VERSION ""

NS_ :

BS_:

BU_: WSGW VCM TBIOM RCIOM FCIOM CCIOM BPMU

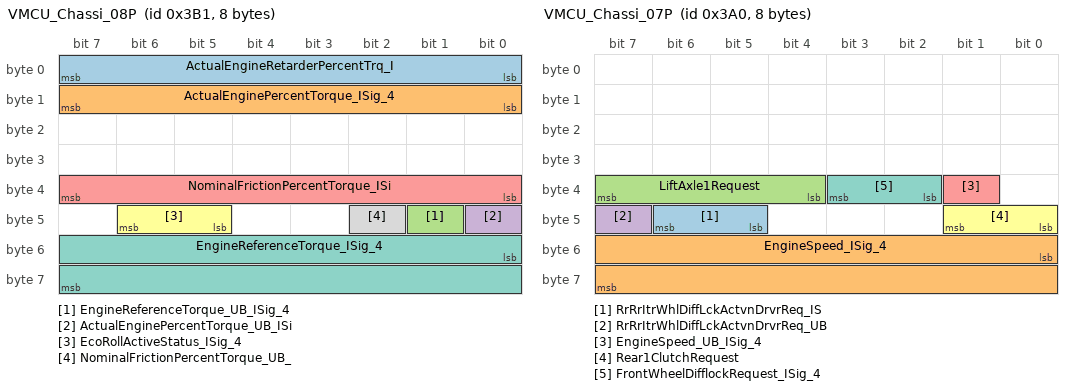
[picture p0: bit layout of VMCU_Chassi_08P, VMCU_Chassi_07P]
BO_ 945 VMCU_Chassi_08P: 8 VCM
 SG_ ActualEngineRetarderPercentTrq_I : 0|8@1+ (1,-125) [-125|130] "Percent"  RCIOM
 SG_ ActualEnginePercentTorque_ISig_4 : 8|8@1+ (1,-125) [-125|130] "Percent"  CCIOM,RCIOM
 SG_ EngineReferenceTorque_UB_ISig_4 : 41|1@1+ (1,0) [0|0] ""  RCIOM
 SG_ ActualEnginePercentTorque_UB_ISi : 40|1@1+ (1,0) [0|0] ""  RCIOM,CCIOM
 SG_ NominalFrictionPercentTorque_ISi : 32|8@1+ (1,-125) [-125|130] "Percent"  RCIOM
 SG_ EcoRollActiveStatus_ISig_4 : 45|2@1+ (1,0) [0|0] ""  CCIOM
 SG_ EngineReferenceTorque_ISig_4 : 48|16@1+ (1,0) [0|65535] "Nm"  RCIOM
 SG_ NominalFrictionPercentTorque_UB_ : 42|1@1+ (1,0) [0|0] ""  RCIOM

BO_ 928 VMCU_Chassi_07P: 8 VCM
 SG_ RrRrItrWhlDiffLckActvnDrvrReq_IS : 45|2@1+ (1,0) [0|0] ""  RCIOM
 SG_ EngineSpeed_ISig_4 : 48|16@1+ (0.125,0) [0|8191.875] "rpm"  CCIOM
 SG_ LiftAxle1Request : 36|4@1+ (1,0) [0|0] ""  RCIOM
 SG_ RrRrItrWhlDiffLckActvnDrvrReq_UB : 47|1@1+ (1,0) [0|0] ""  RCIOM
 SG_ EngineSpeed_UB_ISig_4 : 33|1@1+ (1,0) [0|0] ""  CCIOM
 SG_ Rear1ClutchRequest : 40|2@1+ (1,0) [0|0] ""  RCIOM
 SG_ FrontWheelDifflockRequest_ISig_4 : 34|2@1+ (1,0) [0|0] ""  CCIOM

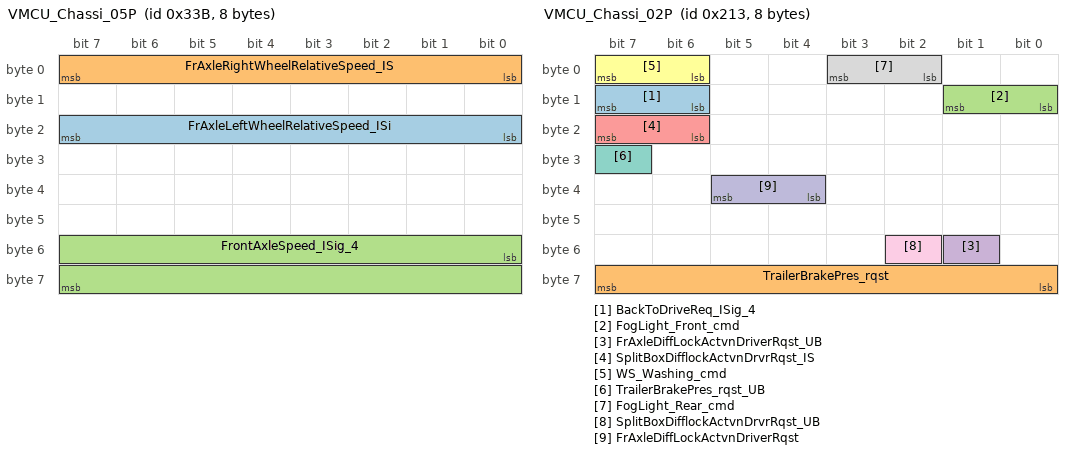
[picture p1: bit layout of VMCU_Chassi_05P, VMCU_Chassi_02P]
BO_ 827 VMCU_Chassi_05P: 8 VCM
 SG_ FrAxleLeftWheelRelativeSpeed_ISi : 16|8@1+ (0.0625,-7.8125) [-7.8125|8.125] "Km_per_h"  RCIOM
 SG_ FrAxleRightWheelRelativeSpeed_IS : 0|8@1+ (0.0625,-7.8125) [-7.8125|8.125] "Km_per_h"  RCIOM
 SG_ FrontAxleSpeed_ISig_4 : 48|16@1+ (0.00390625,0) [0|255.99609375] "Km_per_h"  RCIOM,CCIOM

BO_ 537 VMCU_Chassi_04P: 8 VCM
 SG_ LiftAxle2LiftPositionRequest_ISi : 43|3@1+ (1,0) [0|0] ""  RCIOM
 SG_ LoadDistributionChangeRequest_IS : 48|2@1+ (1,0) [0|0] ""  RCIOM
 SG_ AltLoadDistribution_rqst_ISig_4 : 56|3@1+ (1,0) [0|0] ""  RCIOM
 SG_ LiftAxle1LiftPositionRequest_ISi : 36|3@1+ (1,0) [0|0] ""  RCIOM
 SG_ FerryFunctionRequest_UB_ISig_4 : 10|1@1+ (1,0) [0|0] ""  RCIOM
 SG_ RampLevelRequest_ISig_4 : 0|4@1+ (1,0) [0|0] ""  RCIOM
 SG_ RampLevelStorageRequest_ISig_4 : 16|4@1+ (1,0) [0|0] ""  RCIOM
 SG_ RideHeightFunctionRequest_ISig_4 : 12|4@1+ (1,0) [0|0] ""  RCIOM
 SG_ LiftAxle1AutoLiftRequest_ISig_4 : 34|2@1+ (1,0) [0|0] ""  RCIOM
 SG_ FerryFunctionRequest_ISig_4 : 28|2@1+ (1,0) [0|0] ""  RCIOM
 SG_ AltLoadDistribution_rqst_UB_ISig : 54|1@1+ (1,0) [0|0] ""  RCIOM
 SG_ BBSystemKneelRequest : 8|2@1+ (1,0) [0|0] ""  RCIOM
 SG_ StopLevelChangeRequest_ISig_4 : 24|2@1+ (1,0) [0|0] ""  RCIOM
 SG_ LiftAxle1LiftPositionRequest_UB_ : 39|1@1+ (1,0) [0|0] ""  RCIOM
 SG_ LiftAxle2LiftPositionRequest_UB_ : 46|1@1+ (1,0) [0|0] ""  RCIOM
 SG_ FirstAxleLowerPrioRequested_ISig : 50|3@1+ (1,0) [0|0] ""  RCIOM
 SG_ LiftAxle1AutoLiftRequest_UB_ISig : 23|1@1+ (1,0) [0|0] ""  RCIOM
 SG_ LiftAxle2AutoLiftRequest_ISig_4 : 40|2@1+ (1,0) [0|0] ""  RCIOM
 SG_ LiftAxle2AutoLiftRequest_UB_ISig : 42|1@1+ (1,0) [0|0] ""  RCIOM
 SG_ FerryFunctionSwitchChangeReq_ISi : 61|2@1+ (1,0) [0|0] ""  RCIOM
 SG_ LevelStrokeRequest_ISig_4 : 32|2@1+ (1,0) [0|0] ""  RCIOM
 SG_ BBSystemAlternatLoadDistribReq_U : 55|1@1+ (1,0) [0|0] ""  RCIOM
 SG_ RideHeightFunctionRequest_UB_ISi : 63|1@1+ (1,0) [0|0] ""  RCIOM
 SG_ FirstAxleLowerPrioRequested_UB_I : 53|1@1+ (1,0) [0|0] ""  RCIOM
 SG_ BBSystemProhibitControlRequest : 30|2@1+ (1,0) [0|0] ""  RCIOM
 SG_ LoadDistributionChangeRequest_UB : 47|1@1+ (1,0) [0|0] ""  RCIOM
 SG_ BBSystemAlternatLoadDistribReq : 59|2@1+ (1,0) [0|0] ""  RCIOM
 SG_ RideHeightStorageRequest_ISig_4 : 4|4@1+ (1,0) [0|0] ""  RCIOM
 SG_ BBSystemSpeedDepDriveLevelReq : 26|2@1+ (1,0) [0|0] ""  RCIOM

BO_ 531 VMCU_Chassi_02P: 8 VCM
 SG_ BackToDriveReq_ISig_4 : 14|2@1+ (1,0) [0|0] ""  RCIOM
 SG_ TrailerBrakePres_rqst : 56|8@1+ (8,0) [0|2040] "kPa"  CCIOM
 SG_ FogLight_Front_cmd : 8|2@1+ (1,0) [0|0] ""  FCIOM
 SG_ FrAxleDiffLockActvnDriverRqst_UB : 49|1@1+ (1,0) [0|0] ""  CCIOM
 SG_ SplitBoxDifflockActvnDrvrRqst_IS : 22|2@1+ (1,0) [0|0] ""  CCIOM
 SG_ WS_Washing_cmd : 6|2@1+ (1,0) [0|0] ""  FCIOM
 SG_ TrailerBrakePres_rqst_UB : 31|1@1+ (1,0) [0|0] ""  CCIOM
 SG_ FogLight_Rear_cmd : 2|2@1+ (1,0) [0|0] ""  RCIOM,CCIOM
 SG_ SplitBoxDifflockActvnDrvrRqst_UB : 50|1@1+ (1,0) [0|0] ""  CCIOM
 SG_ FrAxleDiffLockActvnDriverRqst : 36|2@1+ (1,0) [0|0] ""  CCIOM

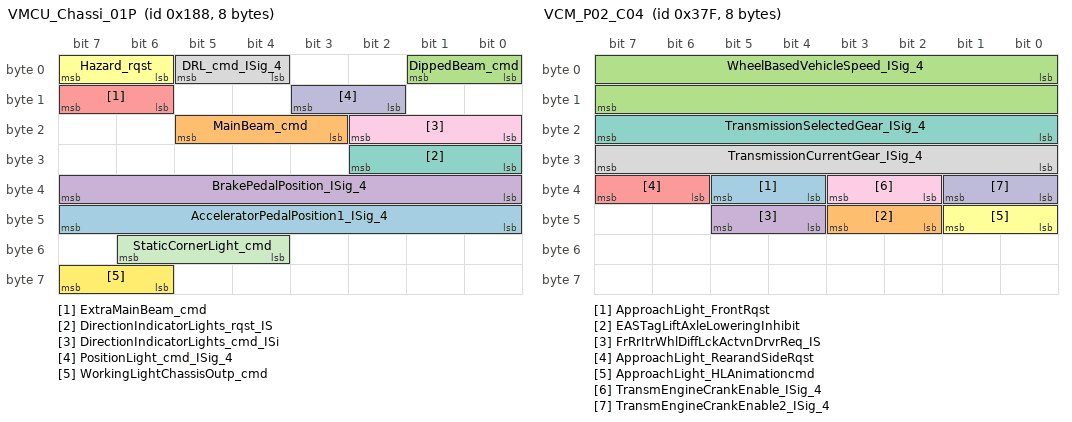
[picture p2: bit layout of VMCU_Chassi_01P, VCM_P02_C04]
BO_ 392 VMCU_Chassi_01P: 8 VCM
 SG_ AcceleratorPedalPosition1_ISig_4 : 40|8@1+ (0.4,0) [0|102] "Percent"  RCIOM,CCIOM
 SG_ MainBeam_cmd : 19|3@1+ (1,0) [0|0] ""  FCIOM,RCIOM
 SG_ DippedBeam_cmd : 0|2@1+ (1,0) [0|0] ""  FCIOM,RCIOM
 SG_ BrakePedalPosition_ISig_4 : 32|8@1+ (0.4,0) [0|102] "Percent"  RCIOM,CCIOM
 SG_ ExtraMainBeam_cmd : 14|2@1+ (1,0) [0|0] ""  FCIOM
 SG_ Hazard_rqst : 6|2@1+ (1,0) [0|0] ""  FCIOM
 SG_ DirectionIndicatorLights_rqst_IS : 24|3@1+ (1,0) [0|0] ""  FCIOM
 SG_ DRL_cmd_ISig_4 : 4|2@1+ (1,0) [0|0] ""  FCIOM,RCIOM
 SG_ DirectionIndicatorLights_cmd_ISi : 16|3@1+ (1,0) [0|0] ""  FCIOM,RCIOM,CCIOM
 SG_ PositionLight_cmd_ISig_4 : 10|2@1+ (1,0) [0|0] ""  FCIOM,RCIOM
 SG_ StaticCornerLight_cmd : 52|3@1+ (1,0) [0|0] ""  FCIOM
 SG_ WorkingLightChassisOutp_cmd : 62|2@1+ (1,0) [0|0] ""  CCIOM

BO_ 895 VCM_P02_C04: 8 VCM
 SG_ ApproachLight_FrontRqst : 36|2@1+ (1,0) [0|0] ""  FCIOM
 SG_ EASTagLiftAxleLoweringInhibit : 42|2@1+ (1,0) [0|0] ""  RCIOM
 SG_ WheelBasedVehicleSpeed_ISig_4 : 0|16@1+ (0.00390625,0) [0|255.99609375] "Km_per_h"  RCIOM,CCIOM,WSGW
 SG_ FrRrItrWhlDiffLckActvnDrvrReq_IS : 44|2@1+ (1,0) [0|0] ""  RCIOM
 SG_ ApproachLight_RearandSideRqst : 38|2@1+ (1,0) [0|0] ""  RCIOM
 SG_ ApproachLight_HLAnimationcmd : 40|2@1+ (1,0) [0|0] ""  FCIOM
 SG_ TransmissionSelectedGear_ISig_4 : 16|8@1+ (1,-125) [-125|130] "GearValue"  CCIOM
 SG_ TransmissionCurrentGear_ISig_4 : 24|8@1+ (1,-125) [-125|130] "GearValue"  CCIOM
 SG_ TransmEngineCrankEnable_ISig_4 : 34|2@1+ (1,0) [0|0] ""  CCIOM
 SG_ TransmEngineCrankEnable2_ISig_4 : 32|2@1+ (1,0) [0|0] ""  CCIOM

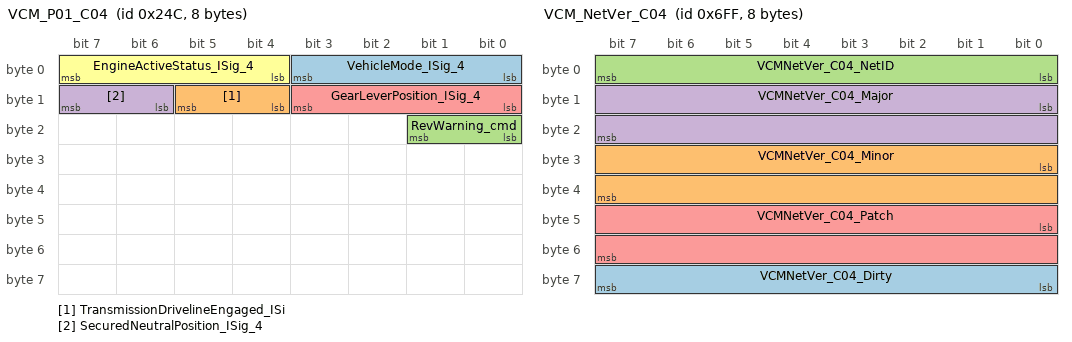
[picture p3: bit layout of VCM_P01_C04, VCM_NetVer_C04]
BO_ 588 VCM_P01_C04: 8 VCM
 SG_ VehicleMode_ISig_4 : 0|4@1+ (1,0) [0|0] ""  CCIOM,WSGW,BPMU,TBIOM,FCIOM,RCIOM
 SG_ TransmissionDrivelineEngaged_ISi : 12|2@1+ (1,0) [0|0] ""  CCIOM
 SG_ RevWarning_cmd : 16|2@1+ (1,0) [0|0] ""  RCIOM
 SG_ SecuredNeutralPosition_ISig_4 : 14|2@1+ (1,0) [0|0] ""  CCIOM
 SG_ GearLeverPosition_ISig_4 : 8|4@1+ (1,0) [0|0] ""  CCIOM
 SG_ EngineActiveStatus_ISig_4 : 4|4@1+ (1,0) [0|0] ""  CCIOM

BO_ 1791 VCM_NetVer_C04: 8 VCM
 SG_ VCMNetVer_C04_Dirty : 56|8@1+ (1,0) [0|255] "NotApplicable" Vector__XXX
 SG_ VCMNetVer_C04_Minor : 24|16@1+ (1,0) [0|65535] "Not Applicable" Vector__XXX
 SG_ VCMNetVer_C04_NetID : 0|8@1+ (1,0) [0|255] "NotApplicable" Vector__XXX
 SG_ VCMNetVer_C04_Major : 8|16@1+ (1,0) [0|65535] "Not Applicable" Vector__XXX
 SG_ VCMNetVer_C04_Patch : 40|16@1+ (1,0) [0|65535] "Not Applicable" Vector__XXX

BO_ 2671902706 TesterFuncDiagMsg_C04: 8 VCM
 SG_ FuncDiagDataTester_ISig_4 : 0|64@1+ (1,0) [0|0] ""  TBIOM,RCIOM,WSGW,FCIOM,CCIOM,BPMU

BO_ 2671902708 TesterFuncDiagMsgF4_C04: 8 VCM
 SG_ FuncDiagDataIntTesterF4_ISig_4 : 0|64@1+ (1,0) [0|0] ""  FCIOM,BPMU,RCIOM,CCIOM,WSGW,TBIOM

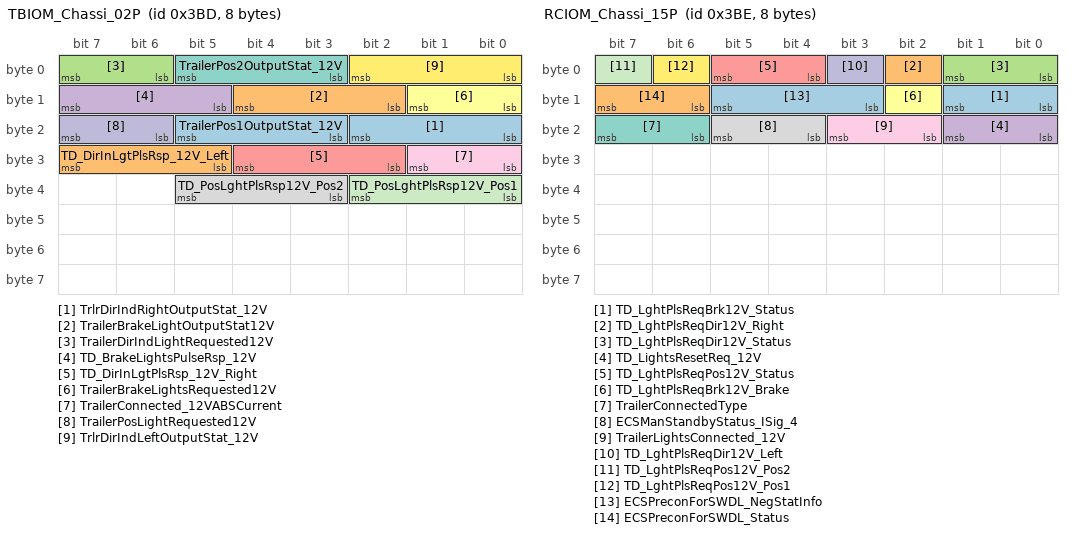
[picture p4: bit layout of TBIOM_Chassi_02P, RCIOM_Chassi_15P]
BO_ 957 TBIOM_Chassi_02P: 8 VCM
 SG_ TrlrDirIndRightOutputStat_12V : 16|3@1+ (1,0) [0|0] ""  RCIOM
 SG_ TrailerBrakeLightOutputStat12V : 10|3@1+ (1,0) [0|0] ""  RCIOM
 SG_ TrailerDirIndLightRequested12V : 6|2@1+ (1,0) [0|0] ""  RCIOM
 SG_ TD_BrakeLightsPulseRsp_12V : 13|3@1+ (1,0) [0|0] ""  RCIOM
 SG_ TD_DirInLgtPlsRsp_12V_Right : 26|3@1+ (1,0) [0|0] ""  RCIOM
 SG_ TrailerBrakeLightsRequested12V : 8|2@1+ (1,0) [0|0] ""  RCIOM
 SG_ TrailerPos2OutputStat_12V : 3|3@1+ (1,0) [0|0] ""  RCIOM
 SG_ TD_PosLghtPlsRsp12V_Pos2 : 35|3@1+ (1,0) [0|0] ""  RCIOM
 SG_ TrailerConnected_12VABSCurrent : 24|2@1+ (1,0) [0|0] ""  RCIOM
 SG_ TrailerPosLightRequested12V : 22|2@1+ (1,0) [0|0] ""  RCIOM
 SG_ TD_PosLghtPlsRsp12V_Pos1 : 32|3@1+ (1,0) [0|0] ""  RCIOM
 SG_ TrlrDirIndLeftOutputStat_12V : 0|3@1+ (1,0) [0|0] ""  RCIOM
 SG_ TrailerPos1OutputStat_12V : 19|3@1+ (1,0) [0|0] ""  RCIOM
 SG_ TD_DirInLgtPlsRsp_12V_Left : 29|3@1+ (1,0) [0|0] ""  RCIOM

BO_ 958 RCIOM_Chassi_15P: 8 RCIOM
 SG_ TD_LghtPlsReqBrk12V_Status : 8|2@1+ (1,0) [0|0] ""  VCM
 SG_ TD_LghtPlsReqDir12V_Right : 2|1@1+ (1,0) [0|0] ""  VCM
 SG_ TD_LghtPlsReqDir12V_Status : 0|2@1+ (1,0) [0|0] ""  VCM
 SG_ TD_LightsResetReq_12V : 16|2@1+ (1,0) [0|0] ""  VCM
 SG_ TD_LghtPlsReqPos12V_Status : 4|2@1+ (1,0) [0|0] ""  VCM
 SG_ TD_LghtPlsReqBrk12V_Brake : 10|1@1+ (1,0) [0|0] ""  VCM
 SG_ TrailerConnectedType : 22|2@1+ (1,0) [0|0] ""  VCM,CCIOM
 SG_ ECSManStandbyStatus_ISig_4 : 20|2@1+ (1,0) [0|0] ""  VCM
 SG_ TrailerLightsConnected_12V : 18|2@1+ (1,0) [0|0] ""  VCM
 SG_ TD_LghtPlsReqDir12V_Left : 3|1@1+ (1,0) [0|0] ""  VCM
 SG_ TD_LghtPlsReqPos12V_Pos2 : 7|1@1+ (1,0) [0|0] ""  VCM
 SG_ TD_LghtPlsReqPos12V_Pos1 : 6|1@1+ (1,0) [0|0] ""  VCM
 SG_ ECSPreconForSWDL_NegStatInfo : 11|3@1+ (1,0) [0|0] ""  VCM
 SG_ ECSPreconForSWDL_Status : 14|2@1+ (1,0) [0|0] ""  VCM

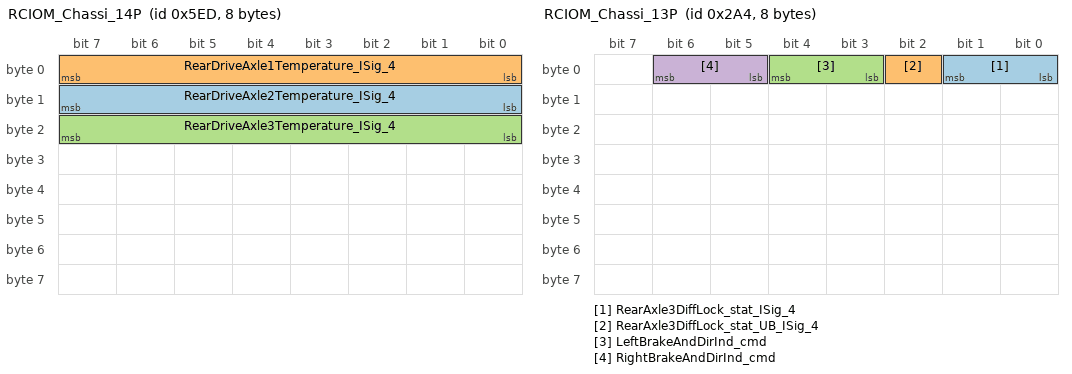
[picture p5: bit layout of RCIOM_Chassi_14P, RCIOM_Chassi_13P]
BO_ 1517 RCIOM_Chassi_14P: 8 RCIOM
 SG_ RearDriveAxle2Temperature_ISig_4 : 8|8@1+ (1,0) [0|255] "DegreeC"  VCM
 SG_ RearDriveAxle1Temperature_ISig_4 : 0|8@1+ (1,0) [0|255] "DegreeC"  VCM
 SG_ RearDriveAxle3Temperature_ISig_4 : 16|8@1+ (1,0) [0|255] "DegreeC"  VCM

BO_ 676 RCIOM_Chassi_13P: 8 RCIOM
 SG_ RearAxle3DiffLock_stat_ISig_4 : 0|2@1+ (1,0) [0|0] ""  VCM
 SG_ RearAxle3DiffLock_stat_UB_ISig_4 : 2|1@1+ (1,0) [0|0] ""  VCM
 SG_ LeftBrakeAndDirInd_cmd : 3|2@1+ (1,0) [0|0] ""  VCM
 SG_ RightBrakeAndDirInd_cmd : 5|2@1+ (1,0) [0|0] ""  VCM

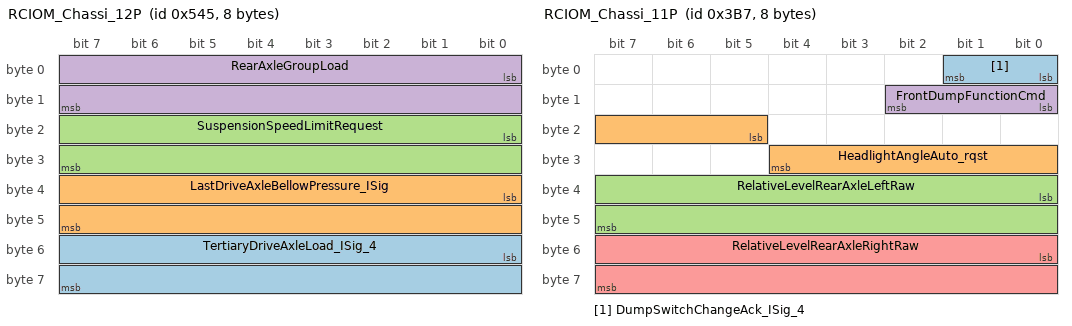
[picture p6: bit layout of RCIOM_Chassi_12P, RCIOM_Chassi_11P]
BO_ 1349 RCIOM_Chassi_12P: 8 RCIOM
 SG_ TertiaryDriveAxleLoad_ISig_4 : 48|16@1+ (0.5,0) [0|32767.5] "kg"  VCM
 SG_ LastDriveAxleBellowPressure_ISig : 32|16@1+ (0.1,0) [0|6553.5] "kPa"  VCM
 SG_ SuspensionSpeedLimitRequest : 16|16@1+ (0.00390625,0) [0|255.99609375] "Km_per_h"  VCM
 SG_ RearAxleGroupLoad : 0|16@1+ (2,0) [0|131070] "kg"  VCM

BO_ 951 RCIOM_Chassi_11P: 8 RCIOM
 SG_ DumpSwitchChangeAck_ISig_4 : 0|2@1+ (1,0) [0|0] ""  VCM
 SG_ HeadlightAngleAuto_rqst : 21|8@1+ (0.025,-4) [-4|2.375] "deg"  VCM
 SG_ RelativeLevelRearAxleLeftRaw : 32|16@1+ (0.1,-3200) [-3200|3353.5] "mm"  VCM
 SG_ FrontDumpFunctionCmd : 8|3@1+ (1,0) [0|0] ""  VCM,CCIOM
 SG_ RelativeLevelRearAxleRightRaw : 48|16@1+ (0.1,-3200) [-3200|3353.5] "mm"  VCM

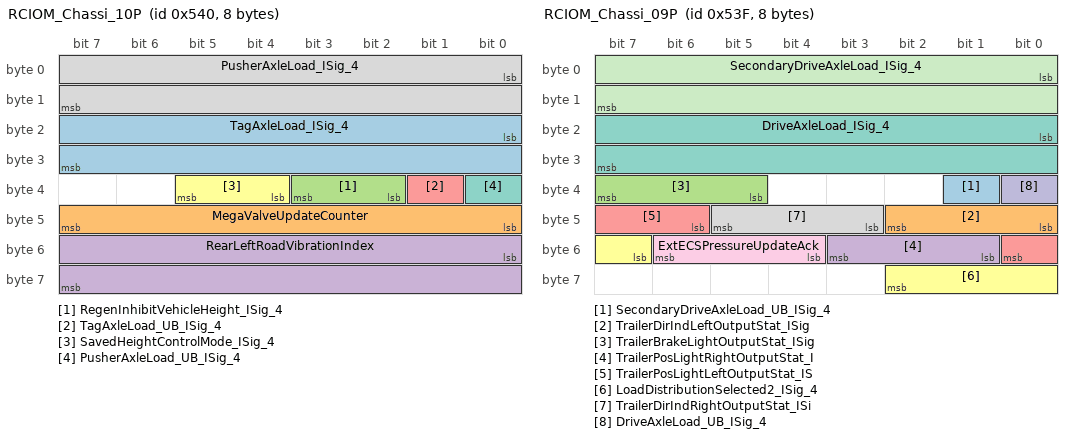
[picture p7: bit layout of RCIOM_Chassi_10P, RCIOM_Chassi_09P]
BO_ 1344 RCIOM_Chassi_10P: 8 RCIOM
 SG_ TagAxleLoad_ISig_4 : 16|16@1+ (0.5,0) [0|32767.5] "kg"  VCM
 SG_ MegaValveUpdateCounter : 40|8@1+ (1,0) [0|255] "Count"  VCM
 SG_ RegenInhibitVehicleHeight_ISig_4 : 34|2@1+ (1,0) [0|0] ""  VCM
 SG_ RearLeftRoadVibrationIndex : 48|16@1+ (0.01,0) [0|655.35] ""  VCM
 SG_ TagAxleLoad_UB_ISig_4 : 33|1@1+ (1,0) [0|0] ""  VCM
 SG_ SavedHeightControlMode_ISig_4 : 36|2@1+ (1,0) [0|0] ""  VCM
 SG_ PusherAxleLoad_UB_ISig_4 : 32|1@1+ (1,0) [0|0] ""  VCM
 SG_ PusherAxleLoad_ISig_4 : 0|16@1+ (0.5,0) [0|32767.5] "kg"  VCM

BO_ 1343 RCIOM_Chassi_09P: 8 RCIOM
 SG_ SecondaryDriveAxleLoad_UB_ISig_4 : 33|1@1+ (1,0) [0|0] ""  VCM
 SG_ TrailerDirIndLeftOutputStat_ISig : 40|3@1+ (1,0) [0|0] ""  VCM
 SG_ TrailerBrakeLightOutputStat_ISig : 37|3@1+ (1,0) [0|0] ""  VCM
 SG_ TrailerPosLightRightOutputStat_I : 49|3@1+ (1,0) [0|0] ""  VCM
 SG_ TrailerPosLightLeftOutputStat_IS : 46|3@1+ (1,0) [0|0] ""  VCM
 SG_ LoadDistributionSelected2_ISig_4 : 55|4@1+ (1,0) [0|0] ""  VCM
 SG_ DriveAxleLoad_ISig_4 : 16|16@1+ (0.5,0) [0|32767.5] "kg"  VCM
 SG_ TrailerDirIndRightOutputStat_ISi : 43|3@1+ (1,0) [0|0] ""  VCM
 SG_ ExtECSPressureUpdateAck : 52|3@1+ (1,0) [0|0] ""  VCM
 SG_ DriveAxleLoad_UB_ISig_4 : 32|1@1+ (1,0) [0|0] ""  VCM
 SG_ SecondaryDriveAxleLoad_ISig_4 : 0|16@1+ (0.5,0) [0|32767.5] "kg"  VCM

BO_ 825 RCIOM_Chassi_08P: 8 RCIOM
 SG_ RevLightLamp_stat_ISig_4 : 43|3@1+ (1,0) [0|0] ""  VCM
 SG_ FirstAxleLowerPrioSelected_ISig_ : 27|3@1+ (1,0) [0|0] ""  VCM
 SG_ FrontParkBrakeOverrideInd_ISig_4 : 46|2@1+ (1,0) [0|0] ""  VCM
 SG_ ECSLimpHomeNotification_ISig_4 : 19|3@1+ (1,0) [0|0] ""  VCM
 SG_ ECSValveActivationAllowed : 30|2@1+ (1,0) [0|0] ""  VCM,CCIOM
 SG_ UnevenLoadWarning_ISig_4 : 38|2@1+ (1,0) [0|0] ""  VCM
 SG_ RampLevelRequestACK_ISig_4 : 4|2@1+ (1,0) [0|0] ""  VCM
 SG_ LoadDistributionSelected_ISig_4 : 12|4@1+ (1,0) [0|0] ""  VCM
 SG_ TrailerABSStatus_ISig_4 : 2|2@1+ (1,0) [0|0] ""  VCM
 SG_ LoadDistributionALDChangeACK_ISi : 32|3@1+ (1,0) [0|0] ""  VCM
 SG_ FogLightRearLamp_stat_ISig_4 : 48|3@1+ (1,0) [0|0] ""  VCM
 SG_ PositionLightRearLamp_stat_ISig_ : 40|3@1+ (1,0) [0|0] ""  VCM
 SG_ FerryFunctionSwitchChangeACK_ISi : 0|2@1+ (1,0) [0|0] ""  VCM
 SG_ LiftAxle1AutoLiftSelected_ISig_4 : 8|2@1+ (1,0) [0|0] ""  VCM
 SG_ BrakeLightLamp_stat_ISig_4 : 35|3@1+ (1,0) [0|0] ""  VCM
 SG_ LiftAxle2AutoLiftSelected_ISig_4 : 10|2@1+ (1,0) [0|0] ""  VCM
 SG_ StartupProhibitStatus_ISig_4 : 53|2@1+ (1,0) [0|0] ""  VCM
 SG_ LiftAxle1LowerACK_ISig_4 : 24|3@1+ (1,0) [0|0] ""  VCM
 SG_ TrailerDirInd_status : 56|3@1+ (1,0) [0|0] ""  VCM
 SG_ DriveLevelPosUserInteraction_ISi : 59|3@1+ (1,0) [0|0] ""  VCM

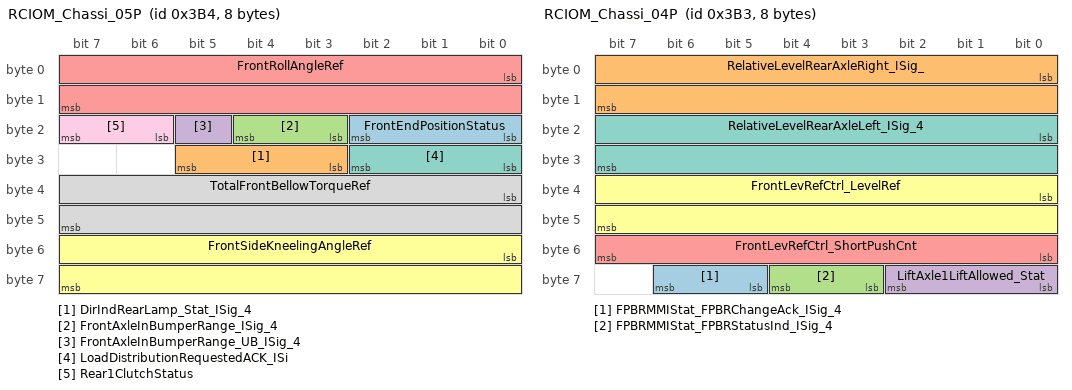
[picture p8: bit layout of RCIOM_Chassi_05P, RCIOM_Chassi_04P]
BO_ 948 RCIOM_Chassi_05P: 8 RCIOM
 SG_ FrontEndPositionStatus : 16|3@1+ (1,0) [0|0] ""  VCM
 SG_ DirIndRearLamp_Stat_ISig_4 : 27|3@1+ (1,0) [0|0] ""  VCM
 SG_ FrontAxleInBumperRange_ISig_4 : 19|2@1+ (1,0) [0|0] ""  VCM
 SG_ FrontAxleInBumperRange_UB_ISig_4 : 21|1@1+ (1,0) [0|0] ""  VCM
 SG_ FrontRollAngleRef : 0|16@1+ (0.001,-30) [-30|35.535] "deg"  VCM,CCIOM
 SG_ FrontSideKneelingAngleRef : 48|16@1+ (0.001,-30) [-30|35.535] "deg"  CCIOM,VCM
 SG_ LoadDistributionRequestedACK_ISi : 24|3@1+ (1,0) [0|0] ""  VCM
 SG_ TotalFrontBellowTorqueRef : 32|16@1+ (1000,-10000000) [-10000000|55535000] "Nm"  VCM,CCIOM
 SG_ Rear1ClutchStatus : 22|2@1+ (1,0) [0|0] ""  VCM

BO_ 947 RCIOM_Chassi_04P: 8 RCIOM
 SG_ FPBRMMIStat_FPBRChangeAck_ISig_4 : 61|2@1+ (1,0) [0|0] ""  VCM
 SG_ RelativeLevelRearAxleRight_ISig_ : 0|16@1+ (0.1,-3200) [-3200|3353.5] "mm"  VCM
 SG_ FPBRMMIStat_FPBRStatusInd_ISig_4 : 59|2@1+ (1,0) [0|0] ""  VCM
 SG_ LiftAxle1LiftAllowed_Stat : 56|3@1+ (1,0) [0|0] ""  VCM
 SG_ FrontLevRefCtrl_ShortPushCnt : 48|8@1+ (1,0) [0|255] "Count"  VCM,CCIOM
 SG_ FrontLevRefCtrl_LevelRef : 32|16@1+ (0.1,-3200) [-3200|3353.5] "mm"  CCIOM,VCM
 SG_ RelativeLevelRearAxleLeft_ISig_4 : 16|16@1+ (0.1,-3200) [-3200|3353.5] "mm"  VCM

BO_ 530 RCIOM_Chassi_03P: 8 RCIOM
 SG_ AirDumpStatus_ISig_4 : 60|3@1+ (1,0) [0|0] ""  VCM
 SG_ RearAxle2DiffLock_stat_ISig_4 : 46|2@1+ (1,0) [0|0] ""  WSGW,VCM
 SG_ SWBrakeSwitch_UB_ISig_4 : 51|1@1+ (1,0) [0|0] ""  VCM
 SG_ SWBrakeSwitch_ISig_4 : 49|2@1+ (1,0) [0|0] ""  VCM
 SG_ RearAxle1DiffLock_stat_ISig_4 : 43|2@1+ (1,0) [0|0] ""  WSGW,VCM
 SG_ SupplyPressure_ISig_4 : 0|8@1+ (8,0) [0|2040] "kPa"  VCM,CCIOM
 SG_ RearAxle2DiffLock_stat_UB_ISig_4 : 48|1@1+ (1,0) [0|0] ""  VCM
 SG_ BackToDriveReqACK_ISig_4 : 58|2@1+ (1,0) [0|0] ""  VCM
 SG_ PitchAngleRef_ISig_4 : 24|16@1+ (0.001,-30) [-30|35.535] "deg"  VCM,CCIOM
 SG_ TrailerConnected_UB_ISig_4 : 54|1@1+ (1,0) [0|0] ""  VCM,CCIOM
 SG_ CentralRearDiffLock_stat_UB_ISig : 42|1@1+ (1,0) [0|0] ""  VCM
 SG_ PitchAngle_ISig_4 : 8|16@1+ (0.001,-30) [-30|35.535] "deg"  VCM,CCIOM
 SG_ TrailerWithoutABS_ISig_4 : 56|2@1+ (1,0) [0|0] ""  VCM
 SG_ TrailerWithoutABS_UB_ISig_4 : 55|1@1+ (1,0) [0|0] ""  VCM
 SG_ TrailerConnected_ISig_4 : 52|2@1+ (1,0) [0|0] ""  VCM,CCIOM,WSGW
 SG_ CentralRearDiffLock_stat_ISig_4 : 40|2@1+ (1,0) [0|0] ""  VCM
 SG_ RearAxle1DiffLock_stat_UB_ISig_4 : 45|1@1+ (1,0) [0|0] ""  VCM

BO_ 528 RCIOM_Chassi_02P: 8 RCIOM
 SG_ RollEndPositionStatus_ISig_4 : 3|3@1+ (1,0) [0|0] ""  VCM
 SG_ FrontFerryFunctionCmd_ISig_4 : 59|3@1+ (1,0) [0|0] ""  VCM,CCIOM
 SG_ RideHeightFunctionStatus_ISig_4 : 36|4@1+ (1,0) [0|0] ""  VCM
 SG_ HeightControlMode_ISig_4 : 32|4@1+ (1,0) [0|0] ""  CCIOM,VCM
 SG_ ECSShutdownCmd_ISig_4 : 43|2@1+ (1,0) [0|0] ""  VCM,CCIOM
 SG_ FerryFunctionStatus_ISig_4 : 56|3@1+ (1,0) [0|0] ""  VCM
 SG_ LevelControlInformation_ISig_4 : 16|4@1+ (1,0) [0|0] ""  VCM
 SG_ ChangeKneelACK_ISig_4 : 45|2@1+ (1,0) [0|0] ""  VCM
 SG_ RearEndPositionStatus_ISig_4 : 48|3@1+ (1,0) [0|0] ""  VCM
 SG_ RampHeightOutsideTargetRange_ISi : 51|3@1+ (1,0) [0|0] ""  VCM
 SG_ LoadDistributionFuncSelected_ISi : 28|4@1+ (1,0) [0|0] ""  VCM
 SG_ HeightAdjustmentAllowed_ISig_4 : 54|2@1+ (1,0) [0|0] ""  VCM
 SG_ LevelControlInformation_UB_ISig_ : 40|1@1+ (1,0) [0|0] ""  VCM
 SG_ KneelingInformation_ISig_4 : 24|4@1+ (1,0) [0|0] ""  VCM
 SG_ KneelingStatusHMI_ISig_4 : 41|2@1+ (1,0) [0|0] ""  VCM
 SG_ LiftAxle1PositionStatus_ISig_4 : 8|3@1+ (1,0) [0|0] ""  CCIOM,WSGW,VCM
 SG_ VehicleDynamicSuspProhibitStat_I : 62|2@1+ (1,0) [0|0] ""  CCIOM,VCM
 SG_ LiftAxle2PositionStatus_ISig_4 : 11|3@1+ (1,0) [0|0] ""  WSGW,VCM
 SG_ RideHeightStatus_ISig_4 : 20|4@1+ (1,0) [0|0] ""  VCM
 SG_ DirInd_Rear_Status_ISig_4 : 0|3@1+ (1,0) [0|0] ""  VCM

CM_ BO_ 827 "This is a sporadic message but this message comes periodically because all signal in the message are gatewayed signals from BB1 and they are periodical there. If there is no traffic on BB1 this message is not sent on Chassi network.";
BA_DEF_ BO_  "GenMsgStartDelayTime" INT 0 0;
BA_DEF_ BO_  "GenMsgDelayTime" INT 0 0;
BA_DEF_ BO_  "GenMsgCycleTime" INT 0 0;
BA_DEF_ BO_  "GenMsgSendType" ENUM  "Cyclic","NotUsed","NotUsed","NotUsed","NotUsed","NotUsed","NotUsed","IfActive","NoMsgSendType","NotUsed";
BA_DEF_ SG_  "GenSigStartValue" INT 0 0;
BA_DEF_ SG_  "GenSigInactiveValue" INT 0 0;
BA_DEF_ SG_  "GenSigCycleTimeActive" INT 0 0;
BA_DEF_ SG_  "GenSigCycleTime" INT 0 0;
BA_DEF_ SG_  "GenSigSendType" ENUM  "Cyclic","OnWrite","OnWriteWithRepetition","OnChange","OnChangeWithRepetition","IfActive","IfActiveWithRepetition","NoSigSendType","NotUsed","NotUsed","NotUsed","NotUsed","NotUsed";
BA_DEF_ BO_  "VFrameFormat" ENUM  "StandardCAN","ExtendedCAN","reserved","J1939PG","reserved","reserved","reserved","reserved","reserved","reserved","reserved","reserved","reserved","reserved","StandardCAN_FD","ExtendedCAN_FD";
BA_DEF_ SG_  "SigType" ENUM  "Default","Range","RangeSigned","ASCII","Discrete","Control","ReferencePGN","DTC","StringDelimiter","StringLength","StringLengthControl";
BA_DEF_ SG_  "Platform_Vivis2_Sig" ENUM  "No","Yes";
BA_DEF_ SG_  "Platform_VMCU1_Sig" ENUM  "No","Yes";
BA_DEF_ BO_  "NmAsrMessage" ENUM  "No","Yes";
BA_DEF_ SG_  "NeedsUpdateBit" ENUM  "No","Yes";
BA_DEF_ SG_  "MmAnSignal" ENUM  "No","Yes";
BA_DEF_ SG_  "GenSigMaxLatency" INT 0 65535;
BA_DEF_ SG_  "GenSigILSupport" ENUM  "Yes","No";
BA_DEF_ BO_  "GenMsgILSupport" ENUM  "No","Yes";
BA_DEF_ SG_  "E2EProfile" STRING ;
BA_DEF_ SG_  "E2EDataLength" INT 0 65535;
BA_DEF_ SG_  "E2EDataId" INT 0 65535;
BA_DEF_ BO_  "DiagUUDTResponse" ENUM  "No","Yes";
BA_DEF_ BO_  "DiagState" ENUM  "No","Yes";
BA_DEF_ BO_  "DiagResponse" ENUM  "No","Yes";
BA_DEF_ BO_  "DiagRequest" ENUM  "No","Yes";
BA_DEF_ BO_  "DiagConnection" HEX 0 65535;
BA_DEF_ BO_  "CanTpFcFrameId" HEX 0 2147483647;
BA_DEF_ BO_  "CanTpBs" INT 0 255;
BA_DEF_ SG_  "SystemSignalLongSymbol" STRING ;
BA_DEF_REL_ BU_SG_REL_  "GenSigTimeoutTime" INT 0 65535;
BA_DEF_REL_ BU_SG_REL_  "GenSigFirstTimeoutTime" INT 0 65535;
BA_DEF_DEF_  "GenMsgStartDelayTime" 0;
BA_DEF_DEF_  "GenMsgDelayTime" 0;
BA_DEF_DEF_  "GenMsgCycleTime" 0;
BA_DEF_DEF_  "GenMsgSendType" "Cyclic";
BA_DEF_DEF_  "GenSigStartValue" 0;
BA_DEF_DEF_  "GenSigInactiveValue" 0;
BA_DEF_DEF_  "GenSigCycleTimeActive" 0;
BA_DEF_DEF_  "GenSigCycleTime" 0;
BA_DEF_DEF_  "GenSigSendType" "Cyclic";
BA_DEF_DEF_  "VFrameFormat" "ExtendedCAN";
BA_DEF_DEF_  "SigType" "Default";
BA_DEF_DEF_  "Platform_Vivis2_Sig" "No";
BA_DEF_DEF_  "Platform_VMCU1_Sig" "No";
BA_DEF_DEF_  "NmAsrMessage" "No";
BA_DEF_DEF_  "NeedsUpdateBit" "No";
BA_DEF_DEF_  "MmAnSignal" "No";
BA_DEF_DEF_  "GenSigMaxLatency" 0;
BA_DEF_DEF_  "GenSigILSupport" "Yes";
BA_DEF_DEF_  "GenMsgILSupport" "Yes";
BA_DEF_DEF_  "E2EProfile" "none";
BA_DEF_DEF_  "E2EDataLength" 0;
BA_DEF_DEF_  "E2EDataId" 0;
BA_DEF_DEF_  "DiagUUDTResponse" "No";
BA_DEF_DEF_  "DiagState" "No";
BA_DEF_DEF_  "DiagResponse" "No";
BA_DEF_DEF_  "DiagRequest" "No";
BA_DEF_DEF_  "DiagConnection" 0;
BA_DEF_DEF_  "CanTpFcFrameId" 2147483647;
BA_DEF_DEF_  "CanTpBs" 255;
BA_DEF_DEF_REL_ "GenSigTimeoutTime" 0;
BA_DEF_DEF_REL_ "GenSigFirstTimeoutTime" 0;
BA_DEF_DEF_  "SystemSignalLongSymbol" "";
BA_ "VFrameFormat" BO_ 945 0;
BA_ "GenMsgCycleTime" BO_ 945 50;
BA_ "GenMsgStartDelayTime" BO_ 945 15;
BA_ "VFrameFormat" BO_ 928 0;
BA_ "GenMsgCycleTime" BO_ 928 50;
BA_ "GenMsgStartDelayTime" BO_ 928 20;
BA_ "VFrameFormat" BO_ 827 0;
BA_ "GenMsgSendType" BO_ 827 8;
BA_ "GenMsgDelayTime" BO_ 827 25;
BA_ "VFrameFormat" BO_ 537 0;
BA_ "GenMsgCycleTime" BO_ 537 20;
BA_ "GenMsgStartDelayTime" BO_ 537 15;
BA_ "VFrameFormat" BO_ 531 0;
BA_ "GenMsgCycleTime" BO_ 531 20;
BA_ "VFrameFormat" BO_ 392 0;
BA_ "GenMsgCycleTime" BO_ 392 10;
BA_ "GenMsgStartDelayTime" BO_ 392 5;
BA_ "VFrameFormat" BO_ 895 0;
BA_ "GenMsgCycleTime" BO_ 895 50;
BA_ "GenMsgStartDelayTime" BO_ 895 5;
BA_ "VFrameFormat" BO_ 588 0;
BA_ "GenMsgCycleTime" BO_ 588 20;
BA_ "GenMsgStartDelayTime" BO_ 588 5;
BA_ "VFrameFormat" BO_ 1791 0;
BA_ "GenMsgCycleTime" BO_ 1791 1000;
BA_ "DiagConnection" BO_ 2671902706 61991;
BA_ "DiagState" BO_ 2671902706 1;
BA_ "GenMsgILSupport" BO_ 2671902706 0;
BA_ "GenMsgSendType" BO_ 2671902706 8;
BA_ "DiagConnection" BO_ 2671902708 62719;
BA_ "DiagState" BO_ 2671902708 1;
BA_ "GenMsgILSupport" BO_ 2671902708 0;
BA_ "GenMsgSendType" BO_ 2671902708 8;
BA_ "VFrameFormat" BO_ 957 0;
BA_ "GenMsgCycleTime" BO_ 957 100;
BA_ "GenMsgStartDelayTime" BO_ 957 5;
BA_ "VFrameFormat" BO_ 958 0;
BA_ "GenMsgCycleTime" BO_ 958 100;
BA_ "GenMsgStartDelayTime" BO_ 958 10;
BA_ "VFrameFormat" BO_ 1517 0;
BA_ "GenMsgCycleTime" BO_ 1517 1000;
BA_ "GenMsgStartDelayTime" BO_ 1517 60;
BA_ "VFrameFormat" BO_ 676 0;
BA_ "GenMsgCycleTime" BO_ 676 20;
BA_ "GenMsgStartDelayTime" BO_ 676 15;
BA_ "VFrameFormat" BO_ 1349 0;
BA_ "GenMsgCycleTime" BO_ 1349 250;
BA_ "GenMsgStartDelayTime" BO_ 1349 75;
BA_ "VFrameFormat" BO_ 951 0;
BA_ "GenMsgCycleTime" BO_ 951 50;
BA_ "GenMsgStartDelayTime" BO_ 951 5;
BA_ "VFrameFormat" BO_ 1344 0;
BA_ "GenMsgCycleTime" BO_ 1344 250;
BA_ "GenMsgStartDelayTime" BO_ 1344 150;
BA_ "VFrameFormat" BO_ 1343 0;
BA_ "GenMsgCycleTime" BO_ 1343 250;
BA_ "GenMsgStartDelayTime" BO_ 1343 50;
BA_ "VFrameFormat" BO_ 825 0;
BA_ "GenMsgCycleTime" BO_ 825 30;
BA_ "GenMsgStartDelayTime" BO_ 825 5;
BA_ "VFrameFormat" BO_ 948 0;
BA_ "GenMsgCycleTime" BO_ 948 50;
BA_ "GenMsgStartDelayTime" BO_ 948 30;
BA_ "VFrameFormat" BO_ 947 0;
BA_ "GenMsgCycleTime" BO_ 947 50;
BA_ "GenMsgStartDelayTime" BO_ 947 10;
BA_ "VFrameFormat" BO_ 530 0;
BA_ "GenMsgCycleTime" BO_ 530 20;
BA_ "GenMsgStartDelayTime" BO_ 530 10;
BA_ "VFrameFormat" BO_ 528 0;
BA_ "GenMsgCycleTime" BO_ 528 20;
BA_ "GenMsgStartDelayTime" BO_ 528 5;
BA_ "GenSigCycleTime" SG_ 945 ActualEngineRetarderPercentTrq_I 100;
BA_ "GenSigCycleTimeActive" SG_ 945 ActualEngineRetarderPercentTrq_I 100;
BA_ "GenSigStartValue" SG_ 945 ActualEngineRetarderPercentTrq_I 255;
BA_ "GenSigMaxLatency" SG_ 945 ActualEngineRetarderPercentTrq_I 54;
BA_ "Platform_VMCU1_Sig" SG_ 945 ActualEngineRetarderPercentTrq_I 1;
BA_ "Platform_Vivis2_Sig" SG_ 945 ActualEngineRetarderPercentTrq_I 1;
BA_ "SystemSignalLongSymbol" SG_ 945 ActualEngineRetarderPercentTrq_I "ActualEngineRetarderPercentTrq_ISig_4";
BA_ "GenSigCycleTime" SG_ 945 ActualEnginePercentTorque_ISig_4 100;
BA_ "GenSigCycleTimeActive" SG_ 945 ActualEnginePercentTorque_ISig_4 100;
BA_ "GenSigStartValue" SG_ 945 ActualEnginePercentTorque_ISig_4 255;
BA_ "GenSigMaxLatency" SG_ 945 ActualEnginePercentTorque_ISig_4 54;
BA_ "NeedsUpdateBit" SG_ 945 ActualEnginePercentTorque_ISig_4 1;
BA_ "Platform_VMCU1_Sig" SG_ 945 ActualEnginePercentTorque_ISig_4 1;
BA_ "Platform_Vivis2_Sig" SG_ 945 ActualEnginePercentTorque_ISig_4 1;
BA_ "GenSigSendType" SG_ 945 EngineReferenceTorque_UB_ISig_4 7;
BA_ "Platform_VMCU1_Sig" SG_ 945 EngineReferenceTorque_UB_ISig_4 1;
BA_ "Platform_Vivis2_Sig" SG_ 945 EngineReferenceTorque_UB_ISig_4 1;
BA_ "GenSigSendType" SG_ 945 ActualEnginePercentTorque_UB_ISi 7;
BA_ "Platform_VMCU1_Sig" SG_ 945 ActualEnginePercentTorque_UB_ISi 1;
BA_ "Platform_Vivis2_Sig" SG_ 945 ActualEnginePercentTorque_UB_ISi 1;
BA_ "SystemSignalLongSymbol" SG_ 945 ActualEnginePercentTorque_UB_ISi "ActualEnginePercentTorque_UB_ISig_4";
BA_ "GenSigCycleTime" SG_ 945 NominalFrictionPercentTorque_ISi 100;
BA_ "GenSigCycleTimeActive" SG_ 945 NominalFrictionPercentTorque_ISi 100;
BA_ "GenSigStartValue" SG_ 945 NominalFrictionPercentTorque_ISi 255;
BA_ "GenSigMaxLatency" SG_ 945 NominalFrictionPercentTorque_ISi 35;
BA_ "NeedsUpdateBit" SG_ 945 NominalFrictionPercentTorque_ISi 1;
BA_ "Platform_VMCU1_Sig" SG_ 945 NominalFrictionPercentTorque_ISi 1;
BA_ "Platform_Vivis2_Sig" SG_ 945 NominalFrictionPercentTorque_ISi 1;
BA_ "SystemSignalLongSymbol" SG_ 945 NominalFrictionPercentTorque_ISi "NominalFrictionPercentTorque_ISig_4";
BA_ "GenSigCycleTime" SG_ 945 EcoRollActiveStatus_ISig_4 100;
BA_ "GenSigCycleTimeActive" SG_ 945 EcoRollActiveStatus_ISig_4 100;
BA_ "GenSigStartValue" SG_ 945 EcoRollActiveStatus_ISig_4 3;
BA_ "Platform_VMCU1_Sig" SG_ 945 EcoRollActiveStatus_ISig_4 1;
BA_ "Platform_Vivis2_Sig" SG_ 945 EcoRollActiveStatus_ISig_4 1;
BA_ "GenSigCycleTime" SG_ 945 EngineReferenceTorque_ISig_4 100;
BA_ "GenSigCycleTimeActive" SG_ 945 EngineReferenceTorque_ISig_4 100;
BA_ "GenSigStartValue" SG_ 945 EngineReferenceTorque_ISig_4 65535;
BA_ "NeedsUpdateBit" SG_ 945 EngineReferenceTorque_ISig_4 1;
BA_ "Platform_VMCU1_Sig" SG_ 945 EngineReferenceTorque_ISig_4 1;
BA_ "Platform_Vivis2_Sig" SG_ 945 EngineReferenceTorque_ISig_4 1;
BA_ "GenSigSendType" SG_ 945 NominalFrictionPercentTorque_UB_ 7;
BA_ "Platform_VMCU1_Sig" SG_ 945 NominalFrictionPercentTorque_UB_ 1;
BA_ "Platform_Vivis2_Sig" SG_ 945 NominalFrictionPercentTorque_UB_ 1;
BA_ "SystemSignalLongSymbol" SG_ 945 NominalFrictionPercentTorque_UB_ "NominalFrictionPercentTorque_UB_ISig_4";
BA_ "GenSigCycleTime" SG_ 928 RrRrItrWhlDiffLckActvnDrvrReq_IS 100;
BA_ "GenSigCycleTimeActive" SG_ 928 RrRrItrWhlDiffLckActvnDrvrReq_IS 100;
BA_ "GenSigStartValue" SG_ 928 RrRrItrWhlDiffLckActvnDrvrReq_IS 3;
BA_ "NeedsUpdateBit" SG_ 928 RrRrItrWhlDiffLckActvnDrvrReq_IS 1;
BA_ "Platform_Vivis2_Sig" SG_ 928 RrRrItrWhlDiffLckActvnDrvrReq_IS 1;
BA_ "SystemSignalLongSymbol" SG_ 928 RrRrItrWhlDiffLckActvnDrvrReq_IS "RrRrItrWhlDiffLckActvnDrvrReq_ISig_4";
BA_ "GenSigCycleTime" SG_ 928 EngineSpeed_ISig_4 100;
BA_ "GenSigCycleTimeActive" SG_ 928 EngineSpeed_ISig_4 100;
BA_ "GenSigStartValue" SG_ 928 EngineSpeed_ISig_4 65535;
BA_ "GenSigMaxLatency" SG_ 928 EngineSpeed_ISig_4 54;
BA_ "NeedsUpdateBit" SG_ 928 EngineSpeed_ISig_4 1;
BA_ "Platform_VMCU1_Sig" SG_ 928 EngineSpeed_ISig_4 1;
BA_ "Platform_Vivis2_Sig" SG_ 928 EngineSpeed_ISig_4 1;
BA_ "GenSigCycleTime" SG_ 928 LiftAxle1Request 100;
BA_ "GenSigCycleTimeActive" SG_ 928 LiftAxle1Request 100;
BA_ "GenSigStartValue" SG_ 928 LiftAxle1Request 15;
BA_ "Platform_VMCU1_Sig" SG_ 928 LiftAxle1Request 1;
BA_ "Platform_Vivis2_Sig" SG_ 928 LiftAxle1Request 1;
BA_ "GenSigSendType" SG_ 928 RrRrItrWhlDiffLckActvnDrvrReq_UB 7;
BA_ "Platform_Vivis2_Sig" SG_ 928 RrRrItrWhlDiffLckActvnDrvrReq_UB 1;
BA_ "SystemSignalLongSymbol" SG_ 928 RrRrItrWhlDiffLckActvnDrvrReq_UB "RrRrItrWhlDiffLckActvnDrvrReq_UB_ISig_4";
BA_ "GenSigSendType" SG_ 928 EngineSpeed_UB_ISig_4 7;
BA_ "Platform_VMCU1_Sig" SG_ 928 EngineSpeed_UB_ISig_4 1;
BA_ "Platform_Vivis2_Sig" SG_ 928 EngineSpeed_UB_ISig_4 1;
BA_ "GenSigCycleTime" SG_ 928 Rear1ClutchRequest 100;
BA_ "GenSigCycleTimeActive" SG_ 928 Rear1ClutchRequest 100;
BA_ "GenSigStartValue" SG_ 928 Rear1ClutchRequest 3;
BA_ "Platform_VMCU1_Sig" SG_ 928 Rear1ClutchRequest 1;
BA_ "Platform_Vivis2_Sig" SG_ 928 Rear1ClutchRequest 1;
BA_ "GenSigCycleTime" SG_ 928 FrontWheelDifflockRequest_ISig_4 100;
BA_ "GenSigCycleTimeActive" SG_ 928 FrontWheelDifflockRequest_ISig_4 100;
BA_ "GenSigStartValue" SG_ 928 FrontWheelDifflockRequest_ISig_4 3;
BA_ "Platform_VMCU1_Sig" SG_ 928 FrontWheelDifflockRequest_ISig_4 1;
BA_ "Platform_Vivis2_Sig" SG_ 928 FrontWheelDifflockRequest_ISig_4 1;
BA_ "GenSigSendType" SG_ 827 FrAxleLeftWheelRelativeSpeed_ISi 1;
BA_ "GenSigStartValue" SG_ 827 FrAxleLeftWheelRelativeSpeed_ISi 255;
BA_ "GenSigMaxLatency" SG_ 827 FrAxleLeftWheelRelativeSpeed_ISi 50;
BA_ "Platform_VMCU1_Sig" SG_ 827 FrAxleLeftWheelRelativeSpeed_ISi 1;
BA_ "Platform_Vivis2_Sig" SG_ 827 FrAxleLeftWheelRelativeSpeed_ISi 1;
BA_ "SystemSignalLongSymbol" SG_ 827 FrAxleLeftWheelRelativeSpeed_ISi "FrAxleLeftWheelRelativeSpeed_ISig_4";
BA_ "GenSigSendType" SG_ 827 FrAxleRightWheelRelativeSpeed_IS 1;
BA_ "GenSigStartValue" SG_ 827 FrAxleRightWheelRelativeSpeed_IS 255;
BA_ "GenSigMaxLatency" SG_ 827 FrAxleRightWheelRelativeSpeed_IS 50;
BA_ "Platform_VMCU1_Sig" SG_ 827 FrAxleRightWheelRelativeSpeed_IS 1;
BA_ "Platform_Vivis2_Sig" SG_ 827 FrAxleRightWheelRelativeSpeed_IS 1;
BA_ "SystemSignalLongSymbol" SG_ 827 FrAxleRightWheelRelativeSpeed_IS "FrAxleRightWheelRelativeSpeed_ISig_4";
BA_ "GenSigSendType" SG_ 827 FrontAxleSpeed_ISig_4 1;
BA_ "GenSigStartValue" SG_ 827 FrontAxleSpeed_ISig_4 65535;
BA_ "GenSigMaxLatency" SG_ 827 FrontAxleSpeed_ISig_4 50;
BA_ "Platform_VMCU1_Sig" SG_ 827 FrontAxleSpeed_ISig_4 1;
BA_ "Platform_Vivis2_Sig" SG_ 827 FrontAxleSpeed_ISig_4 1;
BA_ "GenSigCycleTime" SG_ 537 LiftAxle2LiftPositionRequest_ISi 100;
BA_ "GenSigCycleTimeActive" SG_ 537 LiftAxle2LiftPositionRequest_ISi 100;
BA_ "GenSigStartValue" SG_ 537 LiftAxle2LiftPositionRequest_ISi 7;
BA_ "GenSigMaxLatency" SG_ 537 LiftAxle2LiftPositionRequest_ISi 29;
BA_ "NeedsUpdateBit" SG_ 537 LiftAxle2LiftPositionRequest_ISi 1;
BA_ "Platform_VMCU1_Sig" SG_ 537 LiftAxle2LiftPositionRequest_ISi 1;
BA_ "Platform_Vivis2_Sig" SG_ 537 LiftAxle2LiftPositionRequest_ISi 1;
BA_ "SystemSignalLongSymbol" SG_ 537 LiftAxle2LiftPositionRequest_ISi "LiftAxle2LiftPositionRequest_ISig_4";
BA_ "GenSigCycleTime" SG_ 537 LoadDistributionChangeRequest_IS 100;
BA_ "GenSigCycleTimeActive" SG_ 537 LoadDistributionChangeRequest_IS 100;
BA_ "GenSigStartValue" SG_ 537 LoadDistributionChangeRequest_IS 3;
BA_ "GenSigMaxLatency" SG_ 537 LoadDistributionChangeRequest_IS 29;
BA_ "NeedsUpdateBit" SG_ 537 LoadDistributionChangeRequest_IS 1;
BA_ "Platform_VMCU1_Sig" SG_ 537 LoadDistributionChangeRequest_IS 1;
BA_ "Platform_Vivis2_Sig" SG_ 537 LoadDistributionChangeRequest_IS 1;
BA_ "SystemSignalLongSymbol" SG_ 537 LoadDistributionChangeRequest_IS "LoadDistributionChangeRequest_ISig_4";
BA_ "GenSigCycleTime" SG_ 537 AltLoadDistribution_rqst_ISig_4 100;
BA_ "GenSigCycleTimeActive" SG_ 537 AltLoadDistribution_rqst_ISig_4 100;
BA_ "GenSigStartValue" SG_ 537 AltLoadDistribution_rqst_ISig_4 7;
BA_ "GenSigMaxLatency" SG_ 537 AltLoadDistribution_rqst_ISig_4 29;
BA_ "NeedsUpdateBit" SG_ 537 AltLoadDistribution_rqst_ISig_4 1;
BA_ "Platform_VMCU1_Sig" SG_ 537 AltLoadDistribution_rqst_ISig_4 1;
BA_ "Platform_Vivis2_Sig" SG_ 537 AltLoadDistribution_rqst_ISig_4 1;
BA_ "GenSigCycleTime" SG_ 537 LiftAxle1LiftPositionRequest_ISi 100;
BA_ "GenSigCycleTimeActive" SG_ 537 LiftAxle1LiftPositionRequest_ISi 100;
BA_ "GenSigStartValue" SG_ 537 LiftAxle1LiftPositionRequest_ISi 7;
BA_ "GenSigMaxLatency" SG_ 537 LiftAxle1LiftPositionRequest_ISi 29;
BA_ "NeedsUpdateBit" SG_ 537 LiftAxle1LiftPositionRequest_ISi 1;
BA_ "Platform_VMCU1_Sig" SG_ 537 LiftAxle1LiftPositionRequest_ISi 1;
BA_ "Platform_Vivis2_Sig" SG_ 537 LiftAxle1LiftPositionRequest_ISi 1;
BA_ "SystemSignalLongSymbol" SG_ 537 LiftAxle1LiftPositionRequest_ISi "LiftAxle1LiftPositionRequest_ISig_4";
BA_ "GenSigSendType" SG_ 537 FerryFunctionRequest_UB_ISig_4 7;
BA_ "Platform_VMCU1_Sig" SG_ 537 FerryFunctionRequest_UB_ISig_4 1;
BA_ "Platform_Vivis2_Sig" SG_ 537 FerryFunctionRequest_UB_ISig_4 1;
BA_ "GenSigCycleTime" SG_ 537 RampLevelRequest_ISig_4 100;
BA_ "GenSigCycleTimeActive" SG_ 537 RampLevelRequest_ISig_4 100;
BA_ "GenSigStartValue" SG_ 537 RampLevelRequest_ISig_4 15;
BA_ "GenSigMaxLatency" SG_ 537 RampLevelRequest_ISig_4 29;
BA_ "Platform_VMCU1_Sig" SG_ 537 RampLevelRequest_ISig_4 1;
BA_ "Platform_Vivis2_Sig" SG_ 537 RampLevelRequest_ISig_4 1;
BA_ "GenSigCycleTime" SG_ 537 RampLevelStorageRequest_ISig_4 100;
BA_ "GenSigCycleTimeActive" SG_ 537 RampLevelStorageRequest_ISig_4 100;
BA_ "GenSigStartValue" SG_ 537 RampLevelStorageRequest_ISig_4 15;
BA_ "GenSigMaxLatency" SG_ 537 RampLevelStorageRequest_ISig_4 29;
BA_ "Platform_VMCU1_Sig" SG_ 537 RampLevelStorageRequest_ISig_4 1;
BA_ "Platform_Vivis2_Sig" SG_ 537 RampLevelStorageRequest_ISig_4 1;
BA_ "GenSigCycleTime" SG_ 537 RideHeightFunctionRequest_ISig_4 100;
BA_ "GenSigCycleTimeActive" SG_ 537 RideHeightFunctionRequest_ISig_4 100;
BA_ "GenSigStartValue" SG_ 537 RideHeightFunctionRequest_ISig_4 15;
BA_ "GenSigMaxLatency" SG_ 537 RideHeightFunctionRequest_ISig_4 29;
BA_ "NeedsUpdateBit" SG_ 537 RideHeightFunctionRequest_ISig_4 1;
BA_ "Platform_VMCU1_Sig" SG_ 537 RideHeightFunctionRequest_ISig_4 1;
BA_ "Platform_Vivis2_Sig" SG_ 537 RideHeightFunctionRequest_ISig_4 1;
BA_ "GenSigCycleTime" SG_ 537 LiftAxle1AutoLiftRequest_ISig_4 100;
BA_ "GenSigCycleTimeActive" SG_ 537 LiftAxle1AutoLiftRequest_ISig_4 100;
BA_ "GenSigStartValue" SG_ 537 LiftAxle1AutoLiftRequest_ISig_4 3;
BA_ "GenSigMaxLatency" SG_ 537 LiftAxle1AutoLiftRequest_ISig_4 29;
BA_ "NeedsUpdateBit" SG_ 537 LiftAxle1AutoLiftRequest_ISig_4 1;
BA_ "Platform_VMCU1_Sig" SG_ 537 LiftAxle1AutoLiftRequest_ISig_4 1;
BA_ "Platform_Vivis2_Sig" SG_ 537 LiftAxle1AutoLiftRequest_ISig_4 1;
BA_ "GenSigCycleTime" SG_ 537 FerryFunctionRequest_ISig_4 100;
BA_ "GenSigCycleTimeActive" SG_ 537 FerryFunctionRequest_ISig_4 100;
BA_ "GenSigStartValue" SG_ 537 FerryFunctionRequest_ISig_4 3;
BA_ "GenSigMaxLatency" SG_ 537 FerryFunctionRequest_ISig_4 29;
BA_ "NeedsUpdateBit" SG_ 537 FerryFunctionRequest_ISig_4 1;
BA_ "Platform_VMCU1_Sig" SG_ 537 FerryFunctionRequest_ISig_4 1;
BA_ "Platform_Vivis2_Sig" SG_ 537 FerryFunctionRequest_ISig_4 1;
BA_ "GenSigSendType" SG_ 537 AltLoadDistribution_rqst_UB_ISig 7;
BA_ "Platform_VMCU1_Sig" SG_ 537 AltLoadDistribution_rqst_UB_ISig 1;
BA_ "Platform_Vivis2_Sig" SG_ 537 AltLoadDistribution_rqst_UB_ISig 1;
BA_ "SystemSignalLongSymbol" SG_ 537 AltLoadDistribution_rqst_UB_ISig "AltLoadDistribution_rqst_UB_ISig_4";
BA_ "GenSigCycleTime" SG_ 537 BBSystemKneelRequest 100;
BA_ "GenSigCycleTimeActive" SG_ 537 BBSystemKneelRequest 100;
BA_ "GenSigStartValue" SG_ 537 BBSystemKneelRequest 3;
BA_ "Platform_VMCU1_Sig" SG_ 537 BBSystemKneelRequest 1;
BA_ "Platform_Vivis2_Sig" SG_ 537 BBSystemKneelRequest 1;
BA_ "GenSigCycleTime" SG_ 537 StopLevelChangeRequest_ISig_4 100;
BA_ "GenSigCycleTimeActive" SG_ 537 StopLevelChangeRequest_ISig_4 100;
BA_ "GenSigStartValue" SG_ 537 StopLevelChangeRequest_ISig_4 3;
BA_ "GenSigMaxLatency" SG_ 537 StopLevelChangeRequest_ISig_4 29;
BA_ "Platform_VMCU1_Sig" SG_ 537 StopLevelChangeRequest_ISig_4 1;
BA_ "Platform_Vivis2_Sig" SG_ 537 StopLevelChangeRequest_ISig_4 1;
BA_ "GenSigSendType" SG_ 537 LiftAxle1LiftPositionRequest_UB_ 7;
BA_ "Platform_VMCU1_Sig" SG_ 537 LiftAxle1LiftPositionRequest_UB_ 1;
BA_ "Platform_Vivis2_Sig" SG_ 537 LiftAxle1LiftPositionRequest_UB_ 1;
BA_ "SystemSignalLongSymbol" SG_ 537 LiftAxle1LiftPositionRequest_UB_ "LiftAxle1LiftPositionRequest_UB_ISig_4";
BA_ "GenSigSendType" SG_ 537 LiftAxle2LiftPositionRequest_UB_ 7;
BA_ "Platform_VMCU1_Sig" SG_ 537 LiftAxle2LiftPositionRequest_UB_ 1;
BA_ "Platform_Vivis2_Sig" SG_ 537 LiftAxle2LiftPositionRequest_UB_ 1;
BA_ "SystemSignalLongSymbol" SG_ 537 LiftAxle2LiftPositionRequest_UB_ "LiftAxle2LiftPositionRequest_UB_ISig_4";
BA_ "GenSigCycleTime" SG_ 537 FirstAxleLowerPrioRequested_ISig 100;
BA_ "GenSigCycleTimeActive" SG_ 537 FirstAxleLowerPrioRequested_ISig 100;
BA_ "GenSigStartValue" SG_ 537 FirstAxleLowerPrioRequested_ISig 7;
BA_ "NeedsUpdateBit" SG_ 537 FirstAxleLowerPrioRequested_ISig 1;
BA_ "Platform_Vivis2_Sig" SG_ 537 FirstAxleLowerPrioRequested_ISig 1;
BA_ "SystemSignalLongSymbol" SG_ 537 FirstAxleLowerPrioRequested_ISig "FirstAxleLowerPrioRequested_ISig_4";
BA_ "GenSigSendType" SG_ 537 LiftAxle1AutoLiftRequest_UB_ISig 7;
BA_ "Platform_VMCU1_Sig" SG_ 537 LiftAxle1AutoLiftRequest_UB_ISig 1;
BA_ "Platform_Vivis2_Sig" SG_ 537 LiftAxle1AutoLiftRequest_UB_ISig 1;
BA_ "SystemSignalLongSymbol" SG_ 537 LiftAxle1AutoLiftRequest_UB_ISig "LiftAxle1AutoLiftRequest_UB_ISig_4";
BA_ "GenSigCycleTime" SG_ 537 LiftAxle2AutoLiftRequest_ISig_4 100;
BA_ "GenSigCycleTimeActive" SG_ 537 LiftAxle2AutoLiftRequest_ISig_4 100;
BA_ "GenSigStartValue" SG_ 537 LiftAxle2AutoLiftRequest_ISig_4 3;
BA_ "GenSigMaxLatency" SG_ 537 LiftAxle2AutoLiftRequest_ISig_4 29;
BA_ "NeedsUpdateBit" SG_ 537 LiftAxle2AutoLiftRequest_ISig_4 1;
BA_ "Platform_VMCU1_Sig" SG_ 537 LiftAxle2AutoLiftRequest_ISig_4 1;
BA_ "Platform_Vivis2_Sig" SG_ 537 LiftAxle2AutoLiftRequest_ISig_4 1;
BA_ "GenSigSendType" SG_ 537 LiftAxle2AutoLiftRequest_UB_ISig 7;
BA_ "Platform_VMCU1_Sig" SG_ 537 LiftAxle2AutoLiftRequest_UB_ISig 1;
BA_ "Platform_Vivis2_Sig" SG_ 537 LiftAxle2AutoLiftRequest_UB_ISig 1;
BA_ "SystemSignalLongSymbol" SG_ 537 LiftAxle2AutoLiftRequest_UB_ISig "LiftAxle2AutoLiftRequest_UB_ISig_4";
BA_ "GenSigCycleTime" SG_ 537 FerryFunctionSwitchChangeReq_ISi 100;
BA_ "GenSigCycleTimeActive" SG_ 537 FerryFunctionSwitchChangeReq_ISi 100;
BA_ "GenSigStartValue" SG_ 537 FerryFunctionSwitchChangeReq_ISi 3;
BA_ "Platform_VMCU1_Sig" SG_ 537 FerryFunctionSwitchChangeReq_ISi 1;
BA_ "Platform_Vivis2_Sig" SG_ 537 FerryFunctionSwitchChangeReq_ISi 1;
BA_ "SystemSignalLongSymbol" SG_ 537 FerryFunctionSwitchChangeReq_ISi "FerryFunctionSwitchChangeReq_ISig_4";
BA_ "GenSigCycleTime" SG_ 537 LevelStrokeRequest_ISig_4 100;
BA_ "GenSigCycleTimeActive" SG_ 537 LevelStrokeRequest_ISig_4 100;
BA_ "GenSigStartValue" SG_ 537 LevelStrokeRequest_ISig_4 3;
BA_ "GenSigMaxLatency" SG_ 537 LevelStrokeRequest_ISig_4 29;
BA_ "Platform_VMCU1_Sig" SG_ 537 LevelStrokeRequest_ISig_4 1;
BA_ "Platform_Vivis2_Sig" SG_ 537 LevelStrokeRequest_ISig_4 1;
BA_ "GenSigSendType" SG_ 537 BBSystemAlternatLoadDistribReq_U 7;
BA_ "Platform_VMCU1_Sig" SG_ 537 BBSystemAlternatLoadDistribReq_U 1;
BA_ "Platform_Vivis2_Sig" SG_ 537 BBSystemAlternatLoadDistribReq_U 1;
BA_ "SystemSignalLongSymbol" SG_ 537 BBSystemAlternatLoadDistribReq_U "BBSystemAlternatLoadDistribReq_UB";
BA_ "GenSigSendType" SG_ 537 RideHeightFunctionRequest_UB_ISi 7;
BA_ "Platform_VMCU1_Sig" SG_ 537 RideHeightFunctionRequest_UB_ISi 1;
BA_ "Platform_Vivis2_Sig" SG_ 537 RideHeightFunctionRequest_UB_ISi 1;
BA_ "SystemSignalLongSymbol" SG_ 537 RideHeightFunctionRequest_UB_ISi "RideHeightFunctionRequest_UB_ISig_4";
BA_ "GenSigSendType" SG_ 537 FirstAxleLowerPrioRequested_UB_I 7;
BA_ "Platform_Vivis2_Sig" SG_ 537 FirstAxleLowerPrioRequested_UB_I 1;
BA_ "SystemSignalLongSymbol" SG_ 537 FirstAxleLowerPrioRequested_UB_I "FirstAxleLowerPrioRequested_UB_ISig_4";
BA_ "GenSigCycleTime" SG_ 537 BBSystemProhibitControlRequest 100;
BA_ "GenSigCycleTimeActive" SG_ 537 BBSystemProhibitControlRequest 100;
BA_ "GenSigStartValue" SG_ 537 BBSystemProhibitControlRequest 3;
BA_ "Platform_VMCU1_Sig" SG_ 537 BBSystemProhibitControlRequest 1;
BA_ "Platform_Vivis2_Sig" SG_ 537 BBSystemProhibitControlRequest 1;
BA_ "GenSigSendType" SG_ 537 LoadDistributionChangeRequest_UB 7;
BA_ "Platform_VMCU1_Sig" SG_ 537 LoadDistributionChangeRequest_UB 1;
BA_ "Platform_Vivis2_Sig" SG_ 537 LoadDistributionChangeRequest_UB 1;
BA_ "SystemSignalLongSymbol" SG_ 537 LoadDistributionChangeRequest_UB "LoadDistributionChangeRequest_UB_ISig_4";
BA_ "GenSigCycleTime" SG_ 537 BBSystemAlternatLoadDistribReq 100;
BA_ "GenSigCycleTimeActive" SG_ 537 BBSystemAlternatLoadDistribReq 100;
BA_ "GenSigStartValue" SG_ 537 BBSystemAlternatLoadDistribReq 3;
BA_ "NeedsUpdateBit" SG_ 537 BBSystemAlternatLoadDistribReq 1;
BA_ "Platform_VMCU1_Sig" SG_ 537 BBSystemAlternatLoadDistribReq 1;
BA_ "Platform_Vivis2_Sig" SG_ 537 BBSystemAlternatLoadDistribReq 1;
BA_ "GenSigCycleTime" SG_ 537 RideHeightStorageRequest_ISig_4 100;
BA_ "GenSigCycleTimeActive" SG_ 537 RideHeightStorageRequest_ISig_4 100;
BA_ "GenSigStartValue" SG_ 537 RideHeightStorageRequest_ISig_4 15;
BA_ "GenSigMaxLatency" SG_ 537 RideHeightStorageRequest_ISig_4 29;
BA_ "Platform_VMCU1_Sig" SG_ 537 RideHeightStorageRequest_ISig_4 1;
BA_ "Platform_Vivis2_Sig" SG_ 537 RideHeightStorageRequest_ISig_4 1;
BA_ "GenSigCycleTime" SG_ 537 BBSystemSpeedDepDriveLevelReq 100;
BA_ "GenSigCycleTimeActive" SG_ 537 BBSystemSpeedDepDriveLevelReq 100;
BA_ "GenSigStartValue" SG_ 537 BBSystemSpeedDepDriveLevelReq 3;
BA_ "Platform_VMCU1_Sig" SG_ 537 BBSystemSpeedDepDriveLevelReq 1;
BA_ "Platform_Vivis2_Sig" SG_ 537 BBSystemSpeedDepDriveLevelReq 1;
BA_ "GenSigCycleTime" SG_ 531 BackToDriveReq_ISig_4 100;
BA_ "GenSigCycleTimeActive" SG_ 531 BackToDriveReq_ISig_4 100;
BA_ "GenSigStartValue" SG_ 531 BackToDriveReq_ISig_4 3;
BA_ "Platform_VMCU1_Sig" SG_ 531 BackToDriveReq_ISig_4 1;
BA_ "Platform_Vivis2_Sig" SG_ 531 BackToDriveReq_ISig_4 1;
BA_ "GenSigCycleTime" SG_ 531 TrailerBrakePres_rqst 100;
BA_ "GenSigCycleTimeActive" SG_ 531 TrailerBrakePres_rqst 100;
BA_ "GenSigStartValue" SG_ 531 TrailerBrakePres_rqst 255;
BA_ "GenSigMaxLatency" SG_ 531 TrailerBrakePres_rqst 35;
BA_ "NeedsUpdateBit" SG_ 531 TrailerBrakePres_rqst 1;
BA_ "Platform_VMCU1_Sig" SG_ 531 TrailerBrakePres_rqst 1;
BA_ "Platform_Vivis2_Sig" SG_ 531 TrailerBrakePres_rqst 1;
BA_ "GenSigCycleTime" SG_ 531 FogLight_Front_cmd 100;
BA_ "GenSigCycleTimeActive" SG_ 531 FogLight_Front_cmd 100;
BA_ "GenSigStartValue" SG_ 531 FogLight_Front_cmd 3;
BA_ "GenSigMaxLatency" SG_ 531 FogLight_Front_cmd 24;
BA_ "Platform_VMCU1_Sig" SG_ 531 FogLight_Front_cmd 1;
BA_ "Platform_Vivis2_Sig" SG_ 531 FogLight_Front_cmd 1;
BA_ "GenSigSendType" SG_ 531 FrAxleDiffLockActvnDriverRqst_UB 7;
BA_ "Platform_VMCU1_Sig" SG_ 531 FrAxleDiffLockActvnDriverRqst_UB 1;
BA_ "Platform_Vivis2_Sig" SG_ 531 FrAxleDiffLockActvnDriverRqst_UB 1;
BA_ "GenSigCycleTime" SG_ 531 SplitBoxDifflockActvnDrvrRqst_IS 100;
BA_ "GenSigCycleTimeActive" SG_ 531 SplitBoxDifflockActvnDrvrRqst_IS 100;
BA_ "GenSigStartValue" SG_ 531 SplitBoxDifflockActvnDrvrRqst_IS 3;
BA_ "GenSigMaxLatency" SG_ 531 SplitBoxDifflockActvnDrvrRqst_IS 35;
BA_ "NeedsUpdateBit" SG_ 531 SplitBoxDifflockActvnDrvrRqst_IS 1;
BA_ "Platform_VMCU1_Sig" SG_ 531 SplitBoxDifflockActvnDrvrRqst_IS 1;
BA_ "Platform_Vivis2_Sig" SG_ 531 SplitBoxDifflockActvnDrvrRqst_IS 1;
BA_ "SystemSignalLongSymbol" SG_ 531 SplitBoxDifflockActvnDrvrRqst_IS "SplitBoxDifflockActvnDrvrRqst_ISig_4";
BA_ "GenSigCycleTime" SG_ 531 WS_Washing_cmd 100;
BA_ "GenSigCycleTimeActive" SG_ 531 WS_Washing_cmd 100;
BA_ "GenSigStartValue" SG_ 531 WS_Washing_cmd 3;
BA_ "GenSigMaxLatency" SG_ 531 WS_Washing_cmd 24;
BA_ "Platform_VMCU1_Sig" SG_ 531 WS_Washing_cmd 1;
BA_ "Platform_Vivis2_Sig" SG_ 531 WS_Washing_cmd 1;
BA_ "GenSigSendType" SG_ 531 TrailerBrakePres_rqst_UB 7;
BA_ "Platform_VMCU1_Sig" SG_ 531 TrailerBrakePres_rqst_UB 1;
BA_ "Platform_Vivis2_Sig" SG_ 531 TrailerBrakePres_rqst_UB 1;
BA_ "GenSigCycleTime" SG_ 531 FogLight_Rear_cmd 100;
BA_ "GenSigCycleTimeActive" SG_ 531 FogLight_Rear_cmd 100;
BA_ "GenSigStartValue" SG_ 531 FogLight_Rear_cmd 3;
BA_ "GenSigMaxLatency" SG_ 531 FogLight_Rear_cmd 24;
BA_ "Platform_VMCU1_Sig" SG_ 531 FogLight_Rear_cmd 1;
BA_ "Platform_Vivis2_Sig" SG_ 531 FogLight_Rear_cmd 1;
BA_ "GenSigSendType" SG_ 531 SplitBoxDifflockActvnDrvrRqst_UB 7;
BA_ "Platform_VMCU1_Sig" SG_ 531 SplitBoxDifflockActvnDrvrRqst_UB 1;
BA_ "Platform_Vivis2_Sig" SG_ 531 SplitBoxDifflockActvnDrvrRqst_UB 1;
BA_ "SystemSignalLongSymbol" SG_ 531 SplitBoxDifflockActvnDrvrRqst_UB "SplitBoxDifflockActvnDrvrRqst_UB_ISig_4";
BA_ "GenSigCycleTime" SG_ 531 FrAxleDiffLockActvnDriverRqst 100;
BA_ "GenSigCycleTimeActive" SG_ 531 FrAxleDiffLockActvnDriverRqst 100;
BA_ "GenSigStartValue" SG_ 531 FrAxleDiffLockActvnDriverRqst 3;
BA_ "GenSigMaxLatency" SG_ 531 FrAxleDiffLockActvnDriverRqst 35;
BA_ "NeedsUpdateBit" SG_ 531 FrAxleDiffLockActvnDriverRqst 1;
BA_ "Platform_VMCU1_Sig" SG_ 531 FrAxleDiffLockActvnDriverRqst 1;
BA_ "Platform_Vivis2_Sig" SG_ 531 FrAxleDiffLockActvnDriverRqst 1;
BA_ "GenSigCycleTime" SG_ 392 AcceleratorPedalPosition1_ISig_4 100;
BA_ "GenSigCycleTimeActive" SG_ 392 AcceleratorPedalPosition1_ISig_4 100;
BA_ "GenSigStartValue" SG_ 392 AcceleratorPedalPosition1_ISig_4 255;
BA_ "GenSigMaxLatency" SG_ 392 AcceleratorPedalPosition1_ISig_4 23;
BA_ "Platform_VMCU1_Sig" SG_ 392 AcceleratorPedalPosition1_ISig_4 1;
BA_ "Platform_Vivis2_Sig" SG_ 392 AcceleratorPedalPosition1_ISig_4 1;
BA_ "GenSigCycleTime" SG_ 392 MainBeam_cmd 100;
BA_ "GenSigCycleTimeActive" SG_ 392 MainBeam_cmd 100;
BA_ "GenSigStartValue" SG_ 392 MainBeam_cmd 7;
BA_ "GenSigMaxLatency" SG_ 392 MainBeam_cmd 23;
BA_ "Platform_VMCU1_Sig" SG_ 392 MainBeam_cmd 1;
BA_ "Platform_Vivis2_Sig" SG_ 392 MainBeam_cmd 1;
BA_ "GenSigCycleTime" SG_ 392 DippedBeam_cmd 100;
BA_ "GenSigCycleTimeActive" SG_ 392 DippedBeam_cmd 100;
BA_ "GenSigStartValue" SG_ 392 DippedBeam_cmd 3;
BA_ "GenSigMaxLatency" SG_ 392 DippedBeam_cmd 23;
BA_ "Platform_VMCU1_Sig" SG_ 392 DippedBeam_cmd 1;
BA_ "Platform_Vivis2_Sig" SG_ 392 DippedBeam_cmd 1;
BA_ "GenSigCycleTime" SG_ 392 BrakePedalPosition_ISig_4 100;
BA_ "GenSigCycleTimeActive" SG_ 392 BrakePedalPosition_ISig_4 100;
BA_ "GenSigStartValue" SG_ 392 BrakePedalPosition_ISig_4 255;
BA_ "GenSigMaxLatency" SG_ 392 BrakePedalPosition_ISig_4 23;
BA_ "Platform_VMCU1_Sig" SG_ 392 BrakePedalPosition_ISig_4 1;
BA_ "Platform_Vivis2_Sig" SG_ 392 BrakePedalPosition_ISig_4 1;
BA_ "GenSigCycleTime" SG_ 392 ExtraMainBeam_cmd 100;
BA_ "GenSigCycleTimeActive" SG_ 392 ExtraMainBeam_cmd 100;
BA_ "GenSigStartValue" SG_ 392 ExtraMainBeam_cmd 3;
BA_ "GenSigMaxLatency" SG_ 392 ExtraMainBeam_cmd 35;
BA_ "Platform_VMCU1_Sig" SG_ 392 ExtraMainBeam_cmd 1;
BA_ "Platform_Vivis2_Sig" SG_ 392 ExtraMainBeam_cmd 1;
BA_ "GenSigCycleTime" SG_ 392 Hazard_rqst 100;
BA_ "GenSigCycleTimeActive" SG_ 392 Hazard_rqst 100;
BA_ "GenSigStartValue" SG_ 392 Hazard_rqst 3;
BA_ "GenSigMaxLatency" SG_ 392 Hazard_rqst 23;
BA_ "Platform_VMCU1_Sig" SG_ 392 Hazard_rqst 1;
BA_ "Platform_Vivis2_Sig" SG_ 392 Hazard_rqst 1;
BA_ "GenSigCycleTime" SG_ 392 DirectionIndicatorLights_rqst_IS 100;
BA_ "GenSigCycleTimeActive" SG_ 392 DirectionIndicatorLights_rqst_IS 100;
BA_ "GenSigStartValue" SG_ 392 DirectionIndicatorLights_rqst_IS 7;
BA_ "GenSigMaxLatency" SG_ 392 DirectionIndicatorLights_rqst_IS 23;
BA_ "Platform_VMCU1_Sig" SG_ 392 DirectionIndicatorLights_rqst_IS 1;
BA_ "Platform_Vivis2_Sig" SG_ 392 DirectionIndicatorLights_rqst_IS 1;
BA_ "SystemSignalLongSymbol" SG_ 392 DirectionIndicatorLights_rqst_IS "DirectionIndicatorLights_rqst_ISig_4";
BA_ "GenSigCycleTime" SG_ 392 DRL_cmd_ISig_4 100;
BA_ "GenSigCycleTimeActive" SG_ 392 DRL_cmd_ISig_4 100;
BA_ "GenSigStartValue" SG_ 392 DRL_cmd_ISig_4 3;
BA_ "GenSigMaxLatency" SG_ 392 DRL_cmd_ISig_4 23;
BA_ "Platform_VMCU1_Sig" SG_ 392 DRL_cmd_ISig_4 1;
BA_ "Platform_Vivis2_Sig" SG_ 392 DRL_cmd_ISig_4 1;
BA_ "GenSigCycleTime" SG_ 392 DirectionIndicatorLights_cmd_ISi 100;
BA_ "GenSigCycleTimeActive" SG_ 392 DirectionIndicatorLights_cmd_ISi 100;
BA_ "GenSigStartValue" SG_ 392 DirectionIndicatorLights_cmd_ISi 7;
BA_ "GenSigMaxLatency" SG_ 392 DirectionIndicatorLights_cmd_ISi 23;
BA_ "Platform_VMCU1_Sig" SG_ 392 DirectionIndicatorLights_cmd_ISi 1;
BA_ "Platform_Vivis2_Sig" SG_ 392 DirectionIndicatorLights_cmd_ISi 1;
BA_ "SystemSignalLongSymbol" SG_ 392 DirectionIndicatorLights_cmd_ISi "DirectionIndicatorLights_cmd_ISig_4";
BA_ "GenSigCycleTime" SG_ 392 PositionLight_cmd_ISig_4 100;
BA_ "GenSigCycleTimeActive" SG_ 392 PositionLight_cmd_ISig_4 100;
BA_ "GenSigStartValue" SG_ 392 PositionLight_cmd_ISig_4 3;
BA_ "GenSigMaxLatency" SG_ 392 PositionLight_cmd_ISig_4 24;
BA_ "Platform_VMCU1_Sig" SG_ 392 PositionLight_cmd_ISig_4 1;
BA_ "Platform_Vivis2_Sig" SG_ 392 PositionLight_cmd_ISig_4 1;
BA_ "GenSigCycleTime" SG_ 392 StaticCornerLight_cmd 100;
BA_ "GenSigCycleTimeActive" SG_ 392 StaticCornerLight_cmd 100;
BA_ "GenSigInactiveValue" SG_ 392 StaticCornerLight_cmd 7;
BA_ "GenSigStartValue" SG_ 392 StaticCornerLight_cmd 7;
BA_ "Platform_VMCU1_Sig" SG_ 392 StaticCornerLight_cmd 1;
BA_ "Platform_Vivis2_Sig" SG_ 392 StaticCornerLight_cmd 1;
BA_ "GenSigCycleTime" SG_ 392 WorkingLightChassisOutp_cmd 100;
BA_ "GenSigCycleTimeActive" SG_ 392 WorkingLightChassisOutp_cmd 100;
BA_ "GenSigStartValue" SG_ 392 WorkingLightChassisOutp_cmd 3;
BA_ "Platform_VMCU1_Sig" SG_ 392 WorkingLightChassisOutp_cmd 1;
BA_ "Platform_Vivis2_Sig" SG_ 392 WorkingLightChassisOutp_cmd 1;
BA_ "GenSigCycleTime" SG_ 895 ApproachLight_FrontRqst 100;
BA_ "GenSigCycleTimeActive" SG_ 895 ApproachLight_FrontRqst 100;
BA_ "GenSigStartValue" SG_ 895 ApproachLight_FrontRqst 3;
BA_ "GenSigCycleTime" SG_ 895 EASTagLiftAxleLoweringInhibit 100;
BA_ "GenSigCycleTimeActive" SG_ 895 EASTagLiftAxleLoweringInhibit 100;
BA_ "GenSigStartValue" SG_ 895 EASTagLiftAxleLoweringInhibit 3;
BA_ "GenSigCycleTime" SG_ 895 WheelBasedVehicleSpeed_ISig_4 100;
BA_ "GenSigCycleTimeActive" SG_ 895 WheelBasedVehicleSpeed_ISig_4 100;
BA_ "GenSigStartValue" SG_ 895 WheelBasedVehicleSpeed_ISig_4 65535;
BA_ "GenSigMaxLatency" SG_ 895 WheelBasedVehicleSpeed_ISig_4 50;
BA_ "GenSigCycleTime" SG_ 895 FrRrItrWhlDiffLckActvnDrvrReq_IS 100;
BA_ "GenSigCycleTimeActive" SG_ 895 FrRrItrWhlDiffLckActvnDrvrReq_IS 100;
BA_ "GenSigStartValue" SG_ 895 FrRrItrWhlDiffLckActvnDrvrReq_IS 3;
BA_ "SystemSignalLongSymbol" SG_ 895 FrRrItrWhlDiffLckActvnDrvrReq_IS "FrRrItrWhlDiffLckActvnDrvrReq_ISig_4";
BA_ "GenSigCycleTime" SG_ 895 ApproachLight_RearandSideRqst 100;
BA_ "GenSigCycleTimeActive" SG_ 895 ApproachLight_RearandSideRqst 100;
BA_ "GenSigStartValue" SG_ 895 ApproachLight_RearandSideRqst 3;
BA_ "GenSigCycleTime" SG_ 895 ApproachLight_HLAnimationcmd 100;
BA_ "GenSigCycleTimeActive" SG_ 895 ApproachLight_HLAnimationcmd 100;
BA_ "GenSigStartValue" SG_ 895 ApproachLight_HLAnimationcmd 3;
BA_ "GenSigCycleTime" SG_ 895 TransmissionSelectedGear_ISig_4 100;
BA_ "GenSigCycleTimeActive" SG_ 895 TransmissionSelectedGear_ISig_4 100;
BA_ "GenSigStartValue" SG_ 895 TransmissionSelectedGear_ISig_4 255;
BA_ "GenSigMaxLatency" SG_ 895 TransmissionSelectedGear_ISig_4 50;
BA_ "GenSigCycleTime" SG_ 895 TransmissionCurrentGear_ISig_4 100;
BA_ "GenSigCycleTimeActive" SG_ 895 TransmissionCurrentGear_ISig_4 100;
BA_ "GenSigStartValue" SG_ 895 TransmissionCurrentGear_ISig_4 255;
BA_ "GenSigMaxLatency" SG_ 895 TransmissionCurrentGear_ISig_4 50;
BA_ "GenSigCycleTime" SG_ 895 TransmEngineCrankEnable_ISig_4 100;
BA_ "GenSigCycleTimeActive" SG_ 895 TransmEngineCrankEnable_ISig_4 100;
BA_ "GenSigStartValue" SG_ 895 TransmEngineCrankEnable_ISig_4 3;
BA_ "GenSigMaxLatency" SG_ 895 TransmEngineCrankEnable_ISig_4 50;
BA_ "GenSigCycleTime" SG_ 895 TransmEngineCrankEnable2_ISig_4 100;
BA_ "GenSigCycleTimeActive" SG_ 895 TransmEngineCrankEnable2_ISig_4 100;
BA_ "GenSigStartValue" SG_ 895 TransmEngineCrankEnable2_ISig_4 3;
BA_ "GenSigMaxLatency" SG_ 895 TransmEngineCrankEnable2_ISig_4 50;
BA_ "GenSigCycleTime" SG_ 588 VehicleMode_ISig_4 100;
BA_ "GenSigCycleTimeActive" SG_ 588 VehicleMode_ISig_4 100;
BA_ "GenSigStartValue" SG_ 588 VehicleMode_ISig_4 15;
BA_ "GenSigMaxLatency" SG_ 588 VehicleMode_ISig_4 20;
BA_ "GenSigCycleTime" SG_ 588 TransmissionDrivelineEngaged_ISi 100;
BA_ "GenSigCycleTimeActive" SG_ 588 TransmissionDrivelineEngaged_ISi 100;
BA_ "GenSigStartValue" SG_ 588 TransmissionDrivelineEngaged_ISi 3;
BA_ "GenSigMaxLatency" SG_ 588 TransmissionDrivelineEngaged_ISi 20;
BA_ "SystemSignalLongSymbol" SG_ 588 TransmissionDrivelineEngaged_ISi "TransmissionDrivelineEngaged_ISig_4";
BA_ "GenSigCycleTime" SG_ 588 RevWarning_cmd 100;
BA_ "GenSigCycleTimeActive" SG_ 588 RevWarning_cmd 100;
BA_ "GenSigStartValue" SG_ 588 RevWarning_cmd 3;
BA_ "Platform_Vivis2_Sig" SG_ 588 RevWarning_cmd 1;
BA_ "GenSigCycleTime" SG_ 588 SecuredNeutralPosition_ISig_4 100;
BA_ "GenSigCycleTimeActive" SG_ 588 SecuredNeutralPosition_ISig_4 100;
BA_ "GenSigStartValue" SG_ 588 SecuredNeutralPosition_ISig_4 3;
BA_ "GenSigMaxLatency" SG_ 588 SecuredNeutralPosition_ISig_4 20;
BA_ "GenSigCycleTime" SG_ 588 GearLeverPosition_ISig_4 100;
BA_ "GenSigCycleTimeActive" SG_ 588 GearLeverPosition_ISig_4 100;
BA_ "GenSigStartValue" SG_ 588 GearLeverPosition_ISig_4 15;
BA_ "GenSigMaxLatency" SG_ 588 GearLeverPosition_ISig_4 20;
BA_ "GenSigCycleTime" SG_ 588 EngineActiveStatus_ISig_4 100;
BA_ "GenSigCycleTimeActive" SG_ 588 EngineActiveStatus_ISig_4 100;
BA_ "GenSigStartValue" SG_ 588 EngineActiveStatus_ISig_4 15;
BA_ "GenSigMaxLatency" SG_ 588 EngineActiveStatus_ISig_4 20;
BA_ "GenSigCycleTime" SG_ 1791 VCMNetVer_C04_Dirty 100;
BA_ "GenSigCycleTimeActive" SG_ 1791 VCMNetVer_C04_Dirty 100;
BA_ "GenSigCycleTime" SG_ 1791 VCMNetVer_C04_Minor 100;
BA_ "GenSigCycleTimeActive" SG_ 1791 VCMNetVer_C04_Minor 100;
BA_ "GenSigStartValue" SG_ 1791 VCMNetVer_C04_Minor 3;
BA_ "GenSigCycleTime" SG_ 1791 VCMNetVer_C04_NetID 100;
BA_ "GenSigCycleTimeActive" SG_ 1791 VCMNetVer_C04_NetID 100;
BA_ "GenSigStartValue" SG_ 1791 VCMNetVer_C04_NetID 4;
BA_ "GenSigCycleTime" SG_ 1791 VCMNetVer_C04_Major 100;
BA_ "GenSigCycleTimeActive" SG_ 1791 VCMNetVer_C04_Major 100;
BA_ "GenSigStartValue" SG_ 1791 VCMNetVer_C04_Major 2;
BA_ "GenSigCycleTime" SG_ 1791 VCMNetVer_C04_Patch 100;
BA_ "GenSigCycleTimeActive" SG_ 1791 VCMNetVer_C04_Patch 100;
BA_ "GenSigSendType" SG_ 2671902706 FuncDiagDataTester_ISig_4 7;
BA_ "GenSigSendType" SG_ 2671902708 FuncDiagDataIntTesterF4_ISig_4 7;
BA_ "GenSigCycleTime" SG_ 957 TrlrDirIndRightOutputStat_12V 100;
BA_ "GenSigCycleTimeActive" SG_ 957 TrlrDirIndRightOutputStat_12V 100;
BA_ "GenSigStartValue" SG_ 957 TrlrDirIndRightOutputStat_12V 7;
BA_ "GenSigMaxLatency" SG_ 957 TrlrDirIndRightOutputStat_12V 100;
BA_ "Platform_Vivis2_Sig" SG_ 957 TrlrDirIndRightOutputStat_12V 1;
BA_ "GenSigCycleTime" SG_ 957 TrailerBrakeLightOutputStat12V 100;
BA_ "GenSigCycleTimeActive" SG_ 957 TrailerBrakeLightOutputStat12V 100;
BA_ "GenSigStartValue" SG_ 957 TrailerBrakeLightOutputStat12V 7;
BA_ "GenSigMaxLatency" SG_ 957 TrailerBrakeLightOutputStat12V 100;
BA_ "Platform_Vivis2_Sig" SG_ 957 TrailerBrakeLightOutputStat12V 1;
BA_ "GenSigCycleTime" SG_ 957 TrailerDirIndLightRequested12V 100;
BA_ "GenSigCycleTimeActive" SG_ 957 TrailerDirIndLightRequested12V 100;
BA_ "GenSigStartValue" SG_ 957 TrailerDirIndLightRequested12V 3;
BA_ "GenSigMaxLatency" SG_ 957 TrailerDirIndLightRequested12V 100;
BA_ "Platform_Vivis2_Sig" SG_ 957 TrailerDirIndLightRequested12V 1;
BA_ "GenSigCycleTime" SG_ 957 TD_BrakeLightsPulseRsp_12V 100;
BA_ "GenSigCycleTimeActive" SG_ 957 TD_BrakeLightsPulseRsp_12V 100;
BA_ "GenSigStartValue" SG_ 957 TD_BrakeLightsPulseRsp_12V 7;
BA_ "GenSigMaxLatency" SG_ 957 TD_BrakeLightsPulseRsp_12V 100;
BA_ "Platform_Vivis2_Sig" SG_ 957 TD_BrakeLightsPulseRsp_12V 1;
BA_ "GenSigCycleTime" SG_ 957 TD_DirInLgtPlsRsp_12V_Right 100;
BA_ "GenSigCycleTimeActive" SG_ 957 TD_DirInLgtPlsRsp_12V_Right 100;
BA_ "GenSigStartValue" SG_ 957 TD_DirInLgtPlsRsp_12V_Right 7;
BA_ "GenSigMaxLatency" SG_ 957 TD_DirInLgtPlsRsp_12V_Right 100;
BA_ "Platform_Vivis2_Sig" SG_ 957 TD_DirInLgtPlsRsp_12V_Right 1;
BA_ "GenSigCycleTime" SG_ 957 TrailerBrakeLightsRequested12V 100;
BA_ "GenSigCycleTimeActive" SG_ 957 TrailerBrakeLightsRequested12V 100;
BA_ "GenSigStartValue" SG_ 957 TrailerBrakeLightsRequested12V 3;
BA_ "GenSigMaxLatency" SG_ 957 TrailerBrakeLightsRequested12V 100;
BA_ "Platform_Vivis2_Sig" SG_ 957 TrailerBrakeLightsRequested12V 1;
BA_ "GenSigCycleTime" SG_ 957 TrailerPos2OutputStat_12V 100;
BA_ "GenSigCycleTimeActive" SG_ 957 TrailerPos2OutputStat_12V 100;
BA_ "GenSigStartValue" SG_ 957 TrailerPos2OutputStat_12V 7;
BA_ "GenSigMaxLatency" SG_ 957 TrailerPos2OutputStat_12V 100;
BA_ "Platform_Vivis2_Sig" SG_ 957 TrailerPos2OutputStat_12V 1;
BA_ "GenSigCycleTime" SG_ 957 TD_PosLghtPlsRsp12V_Pos2 100;
BA_ "GenSigCycleTimeActive" SG_ 957 TD_PosLghtPlsRsp12V_Pos2 100;
BA_ "GenSigStartValue" SG_ 957 TD_PosLghtPlsRsp12V_Pos2 7;
BA_ "GenSigMaxLatency" SG_ 957 TD_PosLghtPlsRsp12V_Pos2 100;
BA_ "Platform_Vivis2_Sig" SG_ 957 TD_PosLghtPlsRsp12V_Pos2 1;
BA_ "GenSigCycleTime" SG_ 957 TrailerConnected_12VABSCurrent 100;
BA_ "GenSigCycleTimeActive" SG_ 957 TrailerConnected_12VABSCurrent 100;
BA_ "GenSigStartValue" SG_ 957 TrailerConnected_12VABSCurrent 3;
BA_ "GenSigMaxLatency" SG_ 957 TrailerConnected_12VABSCurrent 100;
BA_ "Platform_Vivis2_Sig" SG_ 957 TrailerConnected_12VABSCurrent 1;
BA_ "GenSigCycleTime" SG_ 957 TrailerPosLightRequested12V 100;
BA_ "GenSigCycleTimeActive" SG_ 957 TrailerPosLightRequested12V 100;
BA_ "GenSigStartValue" SG_ 957 TrailerPosLightRequested12V 3;
BA_ "GenSigMaxLatency" SG_ 957 TrailerPosLightRequested12V 100;
BA_ "Platform_Vivis2_Sig" SG_ 957 TrailerPosLightRequested12V 1;
BA_ "GenSigCycleTime" SG_ 957 TD_PosLghtPlsRsp12V_Pos1 100;
BA_ "GenSigCycleTimeActive" SG_ 957 TD_PosLghtPlsRsp12V_Pos1 100;
BA_ "GenSigStartValue" SG_ 957 TD_PosLghtPlsRsp12V_Pos1 7;
BA_ "GenSigMaxLatency" SG_ 957 TD_PosLghtPlsRsp12V_Pos1 100;
BA_ "Platform_Vivis2_Sig" SG_ 957 TD_PosLghtPlsRsp12V_Pos1 1;
BA_ "GenSigCycleTime" SG_ 957 TrlrDirIndLeftOutputStat_12V 100;
BA_ "GenSigCycleTimeActive" SG_ 957 TrlrDirIndLeftOutputStat_12V 100;
BA_ "GenSigStartValue" SG_ 957 TrlrDirIndLeftOutputStat_12V 7;
BA_ "GenSigMaxLatency" SG_ 957 TrlrDirIndLeftOutputStat_12V 100;
BA_ "Platform_Vivis2_Sig" SG_ 957 TrlrDirIndLeftOutputStat_12V 1;
BA_ "GenSigCycleTime" SG_ 957 TrailerPos1OutputStat_12V 100;
BA_ "GenSigCycleTimeActive" SG_ 957 TrailerPos1OutputStat_12V 100;
BA_ "GenSigStartValue" SG_ 957 TrailerPos1OutputStat_12V 7;
BA_ "GenSigMaxLatency" SG_ 957 TrailerPos1OutputStat_12V 100;
BA_ "Platform_Vivis2_Sig" SG_ 957 TrailerPos1OutputStat_12V 1;
BA_ "GenSigCycleTime" SG_ 957 TD_DirInLgtPlsRsp_12V_Left 100;
BA_ "GenSigCycleTimeActive" SG_ 957 TD_DirInLgtPlsRsp_12V_Left 100;
BA_ "GenSigStartValue" SG_ 957 TD_DirInLgtPlsRsp_12V_Left 7;
BA_ "GenSigMaxLatency" SG_ 957 TD_DirInLgtPlsRsp_12V_Left 100;
BA_ "Platform_Vivis2_Sig" SG_ 957 TD_DirInLgtPlsRsp_12V_Left 1;
BA_ "GenSigCycleTime" SG_ 958 TD_LghtPlsReqBrk12V_Status 100;
BA_ "GenSigCycleTimeActive" SG_ 958 TD_LghtPlsReqBrk12V_Status 100;
BA_ "GenSigStartValue" SG_ 958 TD_LghtPlsReqBrk12V_Status 3;
BA_ "GenSigMaxLatency" SG_ 958 TD_LghtPlsReqBrk12V_Status 100;
BA_ "Platform_Vivis2_Sig" SG_ 958 TD_LghtPlsReqBrk12V_Status 1;
BA_ "GenSigCycleTime" SG_ 958 TD_LghtPlsReqDir12V_Right 100;
BA_ "GenSigCycleTimeActive" SG_ 958 TD_LghtPlsReqDir12V_Right 100;
BA_ "GenSigMaxLatency" SG_ 958 TD_LghtPlsReqDir12V_Right 100;
BA_ "Platform_Vivis2_Sig" SG_ 958 TD_LghtPlsReqDir12V_Right 1;
BA_ "GenSigCycleTime" SG_ 958 TD_LghtPlsReqDir12V_Status 100;
BA_ "GenSigCycleTimeActive" SG_ 958 TD_LghtPlsReqDir12V_Status 100;
BA_ "GenSigStartValue" SG_ 958 TD_LghtPlsReqDir12V_Status 3;
BA_ "GenSigMaxLatency" SG_ 958 TD_LghtPlsReqDir12V_Status 100;
BA_ "Platform_Vivis2_Sig" SG_ 958 TD_LghtPlsReqDir12V_Status 1;
BA_ "GenSigCycleTime" SG_ 958 TD_LightsResetReq_12V 100;
BA_ "GenSigCycleTimeActive" SG_ 958 TD_LightsResetReq_12V 100;
BA_ "GenSigStartValue" SG_ 958 TD_LightsResetReq_12V 3;
BA_ "GenSigMaxLatency" SG_ 958 TD_LightsResetReq_12V 100;
BA_ "Platform_Vivis2_Sig" SG_ 958 TD_LightsResetReq_12V 1;
BA_ "GenSigCycleTime" SG_ 958 TD_LghtPlsReqPos12V_Status 100;
BA_ "GenSigCycleTimeActive" SG_ 958 TD_LghtPlsReqPos12V_Status 100;
BA_ "GenSigStartValue" SG_ 958 TD_LghtPlsReqPos12V_Status 3;
BA_ "GenSigMaxLatency" SG_ 958 TD_LghtPlsReqPos12V_Status 100;
BA_ "Platform_Vivis2_Sig" SG_ 958 TD_LghtPlsReqPos12V_Status 1;
BA_ "GenSigCycleTime" SG_ 958 TD_LghtPlsReqBrk12V_Brake 100;
BA_ "GenSigCycleTimeActive" SG_ 958 TD_LghtPlsReqBrk12V_Brake 100;
BA_ "GenSigMaxLatency" SG_ 958 TD_LghtPlsReqBrk12V_Brake 100;
BA_ "Platform_Vivis2_Sig" SG_ 958 TD_LghtPlsReqBrk12V_Brake 1;
BA_ "GenSigCycleTime" SG_ 958 TrailerConnectedType 100;
BA_ "GenSigCycleTimeActive" SG_ 958 TrailerConnectedType 100;
BA_ "GenSigStartValue" SG_ 958 TrailerConnectedType 3;
BA_ "Platform_Vivis2_Sig" SG_ 958 TrailerConnectedType 1;
BA_ "GenSigCycleTime" SG_ 958 ECSManStandbyStatus_ISig_4 100;
BA_ "GenSigCycleTimeActive" SG_ 958 ECSManStandbyStatus_ISig_4 100;
BA_ "GenSigStartValue" SG_ 958 ECSManStandbyStatus_ISig_4 3;
BA_ "Platform_Vivis2_Sig" SG_ 958 ECSManStandbyStatus_ISig_4 1;
BA_ "GenSigCycleTime" SG_ 958 TrailerLightsConnected_12V 100;
BA_ "GenSigCycleTimeActive" SG_ 958 TrailerLightsConnected_12V 100;
BA_ "GenSigStartValue" SG_ 958 TrailerLightsConnected_12V 3;
BA_ "GenSigMaxLatency" SG_ 958 TrailerLightsConnected_12V 100;
BA_ "Platform_Vivis2_Sig" SG_ 958 TrailerLightsConnected_12V 1;
BA_ "GenSigCycleTime" SG_ 958 TD_LghtPlsReqDir12V_Left 100;
BA_ "GenSigCycleTimeActive" SG_ 958 TD_LghtPlsReqDir12V_Left 100;
BA_ "GenSigMaxLatency" SG_ 958 TD_LghtPlsReqDir12V_Left 100;
BA_ "Platform_Vivis2_Sig" SG_ 958 TD_LghtPlsReqDir12V_Left 1;
BA_ "GenSigCycleTime" SG_ 958 TD_LghtPlsReqPos12V_Pos2 100;
BA_ "GenSigCycleTimeActive" SG_ 958 TD_LghtPlsReqPos12V_Pos2 100;
BA_ "GenSigMaxLatency" SG_ 958 TD_LghtPlsReqPos12V_Pos2 100;
BA_ "Platform_Vivis2_Sig" SG_ 958 TD_LghtPlsReqPos12V_Pos2 1;
BA_ "GenSigCycleTime" SG_ 958 TD_LghtPlsReqPos12V_Pos1 100;
BA_ "GenSigCycleTimeActive" SG_ 958 TD_LghtPlsReqPos12V_Pos1 100;
BA_ "GenSigMaxLatency" SG_ 958 TD_LghtPlsReqPos12V_Pos1 100;
BA_ "Platform_Vivis2_Sig" SG_ 958 TD_LghtPlsReqPos12V_Pos1 1;
BA_ "GenSigCycleTime" SG_ 958 ECSPreconForSWDL_NegStatInfo 100;
BA_ "GenSigCycleTimeActive" SG_ 958 ECSPreconForSWDL_NegStatInfo 100;
BA_ "GenSigStartValue" SG_ 958 ECSPreconForSWDL_NegStatInfo 7;
BA_ "GenSigMaxLatency" SG_ 958 ECSPreconForSWDL_NegStatInfo 100;
BA_ "Platform_Vivis2_Sig" SG_ 958 ECSPreconForSWDL_NegStatInfo 1;
BA_ "GenSigCycleTime" SG_ 958 ECSPreconForSWDL_Status 100;
BA_ "GenSigCycleTimeActive" SG_ 958 ECSPreconForSWDL_Status 100;
BA_ "GenSigStartValue" SG_ 958 ECSPreconForSWDL_Status 3;
BA_ "GenSigMaxLatency" SG_ 958 ECSPreconForSWDL_Status 100;
BA_ "Platform_Vivis2_Sig" SG_ 958 ECSPreconForSWDL_Status 1;
BA_ "GenSigCycleTime" SG_ 1517 RearDriveAxle2Temperature_ISig_4 100;
BA_ "GenSigCycleTimeActive" SG_ 1517 RearDriveAxle2Temperature_ISig_4 100;
BA_ "GenSigStartValue" SG_ 1517 RearDriveAxle2Temperature_ISig_4 255;
BA_ "Platform_Vivis2_Sig" SG_ 1517 RearDriveAxle2Temperature_ISig_4 1;
BA_ "GenSigCycleTime" SG_ 1517 RearDriveAxle1Temperature_ISig_4 100;
BA_ "GenSigCycleTimeActive" SG_ 1517 RearDriveAxle1Temperature_ISig_4 100;
BA_ "GenSigStartValue" SG_ 1517 RearDriveAxle1Temperature_ISig_4 255;
BA_ "Platform_Vivis2_Sig" SG_ 1517 RearDriveAxle1Temperature_ISig_4 1;
BA_ "GenSigCycleTime" SG_ 1517 RearDriveAxle3Temperature_ISig_4 100;
BA_ "GenSigCycleTimeActive" SG_ 1517 RearDriveAxle3Temperature_ISig_4 100;
BA_ "GenSigStartValue" SG_ 1517 RearDriveAxle3Temperature_ISig_4 255;
BA_ "Platform_Vivis2_Sig" SG_ 1517 RearDriveAxle3Temperature_ISig_4 1;
BA_ "GenSigCycleTime" SG_ 676 RearAxle3DiffLock_stat_ISig_4 100;
BA_ "GenSigCycleTimeActive" SG_ 676 RearAxle3DiffLock_stat_ISig_4 100;
BA_ "GenSigStartValue" SG_ 676 RearAxle3DiffLock_stat_ISig_4 3;
BA_ "NeedsUpdateBit" SG_ 676 RearAxle3DiffLock_stat_ISig_4 1;
BA_ "Platform_Vivis2_Sig" SG_ 676 RearAxle3DiffLock_stat_ISig_4 1;
BA_ "GenSigSendType" SG_ 676 RearAxle3DiffLock_stat_UB_ISig_4 7;
BA_ "Platform_Vivis2_Sig" SG_ 676 RearAxle3DiffLock_stat_UB_ISig_4 1;
BA_ "GenSigCycleTime" SG_ 676 LeftBrakeAndDirInd_cmd 100;
BA_ "GenSigCycleTimeActive" SG_ 676 LeftBrakeAndDirInd_cmd 100;
BA_ "GenSigStartValue" SG_ 676 LeftBrakeAndDirInd_cmd 3;
BA_ "Platform_Vivis2_Sig" SG_ 676 LeftBrakeAndDirInd_cmd 1;
BA_ "GenSigCycleTime" SG_ 676 RightBrakeAndDirInd_cmd 100;
BA_ "GenSigCycleTimeActive" SG_ 676 RightBrakeAndDirInd_cmd 100;
BA_ "GenSigStartValue" SG_ 676 RightBrakeAndDirInd_cmd 3;
BA_ "Platform_Vivis2_Sig" SG_ 676 RightBrakeAndDirInd_cmd 1;
BA_ "GenSigCycleTime" SG_ 1349 TertiaryDriveAxleLoad_ISig_4 100;
BA_ "GenSigCycleTimeActive" SG_ 1349 TertiaryDriveAxleLoad_ISig_4 100;
BA_ "GenSigStartValue" SG_ 1349 TertiaryDriveAxleLoad_ISig_4 65535;
BA_ "Platform_Vivis2_Sig" SG_ 1349 TertiaryDriveAxleLoad_ISig_4 1;
BA_ "GenSigCycleTime" SG_ 1349 LastDriveAxleBellowPressure_ISig 100;
BA_ "GenSigCycleTimeActive" SG_ 1349 LastDriveAxleBellowPressure_ISig 100;
BA_ "GenSigStartValue" SG_ 1349 LastDriveAxleBellowPressure_ISig 65535;
BA_ "Platform_Vivis2_Sig" SG_ 1349 LastDriveAxleBellowPressure_ISig 1;
BA_ "SystemSignalLongSymbol" SG_ 1349 LastDriveAxleBellowPressure_ISig "LastDriveAxleBellowPressure_ISig_4";
BA_ "GenSigCycleTime" SG_ 1349 SuspensionSpeedLimitRequest 100;
BA_ "GenSigCycleTimeActive" SG_ 1349 SuspensionSpeedLimitRequest 100;
BA_ "GenSigStartValue" SG_ 1349 SuspensionSpeedLimitRequest 65535;
BA_ "Platform_Vivis2_Sig" SG_ 1349 SuspensionSpeedLimitRequest 1;
BA_ "GenSigCycleTime" SG_ 1349 RearAxleGroupLoad 100;
BA_ "GenSigCycleTimeActive" SG_ 1349 RearAxleGroupLoad 100;
BA_ "GenSigStartValue" SG_ 1349 RearAxleGroupLoad 65535;
BA_ "Platform_Vivis2_Sig" SG_ 1349 RearAxleGroupLoad 1;
BA_ "GenSigCycleTime" SG_ 951 DumpSwitchChangeAck_ISig_4 100;
BA_ "GenSigCycleTimeActive" SG_ 951 DumpSwitchChangeAck_ISig_4 100;
BA_ "GenSigStartValue" SG_ 951 DumpSwitchChangeAck_ISig_4 3;
BA_ "Platform_Vivis2_Sig" SG_ 951 DumpSwitchChangeAck_ISig_4 1;
BA_ "GenSigCycleTime" SG_ 951 HeadlightAngleAuto_rqst 100;
BA_ "GenSigCycleTimeActive" SG_ 951 HeadlightAngleAuto_rqst 100;
BA_ "GenSigStartValue" SG_ 951 HeadlightAngleAuto_rqst 255;
BA_ "Platform_Vivis2_Sig" SG_ 951 HeadlightAngleAuto_rqst 1;
BA_ "GenSigCycleTime" SG_ 951 RelativeLevelRearAxleLeftRaw 100;
BA_ "GenSigCycleTimeActive" SG_ 951 RelativeLevelRearAxleLeftRaw 100;
BA_ "GenSigStartValue" SG_ 951 RelativeLevelRearAxleLeftRaw 65535;
BA_ "Platform_Vivis2_Sig" SG_ 951 RelativeLevelRearAxleLeftRaw 1;
BA_ "GenSigCycleTime" SG_ 951 FrontDumpFunctionCmd 100;
BA_ "GenSigCycleTimeActive" SG_ 951 FrontDumpFunctionCmd 100;
BA_ "GenSigStartValue" SG_ 951 FrontDumpFunctionCmd 7;
BA_ "Platform_Vivis2_Sig" SG_ 951 FrontDumpFunctionCmd 1;
BA_ "GenSigCycleTime" SG_ 951 RelativeLevelRearAxleRightRaw 100;
BA_ "GenSigCycleTimeActive" SG_ 951 RelativeLevelRearAxleRightRaw 100;
BA_ "GenSigStartValue" SG_ 951 RelativeLevelRearAxleRightRaw 65535;
BA_ "Platform_Vivis2_Sig" SG_ 951 RelativeLevelRearAxleRightRaw 1;
BA_ "GenSigCycleTime" SG_ 1344 TagAxleLoad_ISig_4 100;
BA_ "GenSigCycleTimeActive" SG_ 1344 TagAxleLoad_ISig_4 100;
BA_ "GenSigStartValue" SG_ 1344 TagAxleLoad_ISig_4 65535;
BA_ "GenSigMaxLatency" SG_ 1344 TagAxleLoad_ISig_4 255;
BA_ "NeedsUpdateBit" SG_ 1344 TagAxleLoad_ISig_4 1;
BA_ "Platform_VMCU1_Sig" SG_ 1344 TagAxleLoad_ISig_4 1;
BA_ "Platform_Vivis2_Sig" SG_ 1344 TagAxleLoad_ISig_4 1;
BA_ "GenSigCycleTime" SG_ 1344 MegaValveUpdateCounter 100;
BA_ "GenSigCycleTimeActive" SG_ 1344 MegaValveUpdateCounter 100;
BA_ "GenSigStartValue" SG_ 1344 MegaValveUpdateCounter 255;
BA_ "Platform_Vivis2_Sig" SG_ 1344 MegaValveUpdateCounter 1;
BA_ "GenSigCycleTime" SG_ 1344 RegenInhibitVehicleHeight_ISig_4 100;
BA_ "GenSigCycleTimeActive" SG_ 1344 RegenInhibitVehicleHeight_ISig_4 100;
BA_ "GenSigStartValue" SG_ 1344 RegenInhibitVehicleHeight_ISig_4 3;
BA_ "Platform_VMCU1_Sig" SG_ 1344 RegenInhibitVehicleHeight_ISig_4 1;
BA_ "Platform_Vivis2_Sig" SG_ 1344 RegenInhibitVehicleHeight_ISig_4 1;
BA_ "GenSigCycleTime" SG_ 1344 RearLeftRoadVibrationIndex 100;
BA_ "GenSigCycleTimeActive" SG_ 1344 RearLeftRoadVibrationIndex 100;
BA_ "GenSigStartValue" SG_ 1344 RearLeftRoadVibrationIndex 65535;
BA_ "Platform_VMCU1_Sig" SG_ 1344 RearLeftRoadVibrationIndex 1;
BA_ "Platform_Vivis2_Sig" SG_ 1344 RearLeftRoadVibrationIndex 1;
BA_ "GenSigSendType" SG_ 1344 TagAxleLoad_UB_ISig_4 7;
BA_ "Platform_VMCU1_Sig" SG_ 1344 TagAxleLoad_UB_ISig_4 1;
BA_ "Platform_Vivis2_Sig" SG_ 1344 TagAxleLoad_UB_ISig_4 1;
BA_ "GenSigCycleTime" SG_ 1344 SavedHeightControlMode_ISig_4 100;
BA_ "GenSigCycleTimeActive" SG_ 1344 SavedHeightControlMode_ISig_4 100;
BA_ "GenSigStartValue" SG_ 1344 SavedHeightControlMode_ISig_4 3;
BA_ "Platform_Vivis2_Sig" SG_ 1344 SavedHeightControlMode_ISig_4 1;
BA_ "GenSigSendType" SG_ 1344 PusherAxleLoad_UB_ISig_4 7;
BA_ "Platform_VMCU1_Sig" SG_ 1344 PusherAxleLoad_UB_ISig_4 1;
BA_ "Platform_Vivis2_Sig" SG_ 1344 PusherAxleLoad_UB_ISig_4 1;
BA_ "GenSigCycleTime" SG_ 1344 PusherAxleLoad_ISig_4 100;
BA_ "GenSigCycleTimeActive" SG_ 1344 PusherAxleLoad_ISig_4 100;
BA_ "GenSigStartValue" SG_ 1344 PusherAxleLoad_ISig_4 65535;
BA_ "GenSigMaxLatency" SG_ 1344 PusherAxleLoad_ISig_4 255;
BA_ "NeedsUpdateBit" SG_ 1344 PusherAxleLoad_ISig_4 1;
BA_ "Platform_VMCU1_Sig" SG_ 1344 PusherAxleLoad_ISig_4 1;
BA_ "Platform_Vivis2_Sig" SG_ 1344 PusherAxleLoad_ISig_4 1;
BA_ "GenSigSendType" SG_ 1343 SecondaryDriveAxleLoad_UB_ISig_4 7;
BA_ "Platform_VMCU1_Sig" SG_ 1343 SecondaryDriveAxleLoad_UB_ISig_4 1;
BA_ "Platform_Vivis2_Sig" SG_ 1343 SecondaryDriveAxleLoad_UB_ISig_4 1;
BA_ "GenSigCycleTime" SG_ 1343 TrailerDirIndLeftOutputStat_ISig 100;
BA_ "GenSigCycleTimeActive" SG_ 1343 TrailerDirIndLeftOutputStat_ISig 100;
BA_ "GenSigStartValue" SG_ 1343 TrailerDirIndLeftOutputStat_ISig 7;
BA_ "Platform_Vivis2_Sig" SG_ 1343 TrailerDirIndLeftOutputStat_ISig 1;
BA_ "SystemSignalLongSymbol" SG_ 1343 TrailerDirIndLeftOutputStat_ISig "TrailerDirIndLeftOutputStat_ISig_4";
BA_ "GenSigCycleTime" SG_ 1343 TrailerBrakeLightOutputStat_ISig 100;
BA_ "GenSigCycleTimeActive" SG_ 1343 TrailerBrakeLightOutputStat_ISig 100;
BA_ "GenSigStartValue" SG_ 1343 TrailerBrakeLightOutputStat_ISig 7;
BA_ "Platform_Vivis2_Sig" SG_ 1343 TrailerBrakeLightOutputStat_ISig 1;
BA_ "SystemSignalLongSymbol" SG_ 1343 TrailerBrakeLightOutputStat_ISig "TrailerBrakeLightOutputStat_ISig_4";
BA_ "GenSigCycleTime" SG_ 1343 TrailerPosLightRightOutputStat_I 100;
BA_ "GenSigCycleTimeActive" SG_ 1343 TrailerPosLightRightOutputStat_I 100;
BA_ "GenSigStartValue" SG_ 1343 TrailerPosLightRightOutputStat_I 7;
BA_ "Platform_Vivis2_Sig" SG_ 1343 TrailerPosLightRightOutputStat_I 1;
BA_ "SystemSignalLongSymbol" SG_ 1343 TrailerPosLightRightOutputStat_I "TrailerPosLightRightOutputStat_ISig_4";
BA_ "GenSigCycleTime" SG_ 1343 TrailerPosLightLeftOutputStat_IS 100;
BA_ "GenSigCycleTimeActive" SG_ 1343 TrailerPosLightLeftOutputStat_IS 100;
BA_ "GenSigStartValue" SG_ 1343 TrailerPosLightLeftOutputStat_IS 7;
BA_ "Platform_Vivis2_Sig" SG_ 1343 TrailerPosLightLeftOutputStat_IS 1;
BA_ "SystemSignalLongSymbol" SG_ 1343 TrailerPosLightLeftOutputStat_IS "TrailerPosLightLeftOutputStat_ISig_4";
BA_ "GenSigCycleTime" SG_ 1343 LoadDistributionSelected2_ISig_4 100;
BA_ "GenSigCycleTimeActive" SG_ 1343 LoadDistributionSelected2_ISig_4 100;
BA_ "GenSigStartValue" SG_ 1343 LoadDistributionSelected2_ISig_4 15;
BA_ "Platform_Vivis2_Sig" SG_ 1343 LoadDistributionSelected2_ISig_4 1;
BA_ "GenSigCycleTime" SG_ 1343 DriveAxleLoad_ISig_4 100;
BA_ "GenSigCycleTimeActive" SG_ 1343 DriveAxleLoad_ISig_4 100;
BA_ "GenSigStartValue" SG_ 1343 DriveAxleLoad_ISig_4 65535;
BA_ "GenSigMaxLatency" SG_ 1343 DriveAxleLoad_ISig_4 255;
BA_ "NeedsUpdateBit" SG_ 1343 DriveAxleLoad_ISig_4 1;
BA_ "Platform_VMCU1_Sig" SG_ 1343 DriveAxleLoad_ISig_4 1;
BA_ "Platform_Vivis2_Sig" SG_ 1343 DriveAxleLoad_ISig_4 1;
BA_ "GenSigCycleTime" SG_ 1343 TrailerDirIndRightOutputStat_ISi 100;
BA_ "GenSigCycleTimeActive" SG_ 1343 TrailerDirIndRightOutputStat_ISi 100;
BA_ "GenSigStartValue" SG_ 1343 TrailerDirIndRightOutputStat_ISi 7;
BA_ "Platform_Vivis2_Sig" SG_ 1343 TrailerDirIndRightOutputStat_ISi 1;
BA_ "SystemSignalLongSymbol" SG_ 1343 TrailerDirIndRightOutputStat_ISi "TrailerDirIndRightOutputStat_ISig_4";
BA_ "GenSigCycleTime" SG_ 1343 ExtECSPressureUpdateAck 100;
BA_ "GenSigCycleTimeActive" SG_ 1343 ExtECSPressureUpdateAck 100;
BA_ "GenSigStartValue" SG_ 1343 ExtECSPressureUpdateAck 7;
BA_ "Platform_Vivis2_Sig" SG_ 1343 ExtECSPressureUpdateAck 1;
BA_ "GenSigSendType" SG_ 1343 DriveAxleLoad_UB_ISig_4 7;
BA_ "Platform_VMCU1_Sig" SG_ 1343 DriveAxleLoad_UB_ISig_4 1;
BA_ "Platform_Vivis2_Sig" SG_ 1343 DriveAxleLoad_UB_ISig_4 1;
BA_ "GenSigCycleTime" SG_ 1343 SecondaryDriveAxleLoad_ISig_4 100;
BA_ "GenSigCycleTimeActive" SG_ 1343 SecondaryDriveAxleLoad_ISig_4 100;
BA_ "GenSigStartValue" SG_ 1343 SecondaryDriveAxleLoad_ISig_4 65535;
BA_ "GenSigMaxLatency" SG_ 1343 SecondaryDriveAxleLoad_ISig_4 255;
BA_ "NeedsUpdateBit" SG_ 1343 SecondaryDriveAxleLoad_ISig_4 1;
BA_ "Platform_VMCU1_Sig" SG_ 1343 SecondaryDriveAxleLoad_ISig_4 1;
BA_ "Platform_Vivis2_Sig" SG_ 1343 SecondaryDriveAxleLoad_ISig_4 1;
BA_ "GenSigCycleTime" SG_ 825 RevLightLamp_stat_ISig_4 100;
BA_ "GenSigCycleTimeActive" SG_ 825 RevLightLamp_stat_ISig_4 100;
BA_ "GenSigInactiveValue" SG_ 825 RevLightLamp_stat_ISig_4 7;
BA_ "GenSigStartValue" SG_ 825 RevLightLamp_stat_ISig_4 7;
BA_ "GenSigMaxLatency" SG_ 825 RevLightLamp_stat_ISig_4 35;
BA_ "Platform_VMCU1_Sig" SG_ 825 RevLightLamp_stat_ISig_4 1;
BA_ "Platform_Vivis2_Sig" SG_ 825 RevLightLamp_stat_ISig_4 1;
BA_ "GenSigCycleTime" SG_ 825 FirstAxleLowerPrioSelected_ISig_ 100;
BA_ "GenSigCycleTimeActive" SG_ 825 FirstAxleLowerPrioSelected_ISig_ 100;
BA_ "GenSigStartValue" SG_ 825 FirstAxleLowerPrioSelected_ISig_ 7;
BA_ "Platform_Vivis2_Sig" SG_ 825 FirstAxleLowerPrioSelected_ISig_ 1;
BA_ "SystemSignalLongSymbol" SG_ 825 FirstAxleLowerPrioSelected_ISig_ "FirstAxleLowerPrioSelected_ISig_4";
BA_ "GenSigCycleTime" SG_ 825 FrontParkBrakeOverrideInd_ISig_4 100;
BA_ "GenSigCycleTimeActive" SG_ 825 FrontParkBrakeOverrideInd_ISig_4 100;
BA_ "GenSigStartValue" SG_ 825 FrontParkBrakeOverrideInd_ISig_4 3;
BA_ "Platform_Vivis2_Sig" SG_ 825 FrontParkBrakeOverrideInd_ISig_4 1;
BA_ "GenSigCycleTime" SG_ 825 ECSLimpHomeNotification_ISig_4 100;
BA_ "GenSigCycleTimeActive" SG_ 825 ECSLimpHomeNotification_ISig_4 100;
BA_ "GenSigStartValue" SG_ 825 ECSLimpHomeNotification_ISig_4 7;
BA_ "GenSigMaxLatency" SG_ 825 ECSLimpHomeNotification_ISig_4 35;
BA_ "Platform_VMCU1_Sig" SG_ 825 ECSLimpHomeNotification_ISig_4 1;
BA_ "Platform_Vivis2_Sig" SG_ 825 ECSLimpHomeNotification_ISig_4 1;
BA_ "GenSigCycleTime" SG_ 825 ECSValveActivationAllowed 100;
BA_ "GenSigCycleTimeActive" SG_ 825 ECSValveActivationAllowed 100;
BA_ "GenSigStartValue" SG_ 825 ECSValveActivationAllowed 3;
BA_ "GenSigMaxLatency" SG_ 825 ECSValveActivationAllowed 35;
BA_ "Platform_VMCU1_Sig" SG_ 825 ECSValveActivationAllowed 1;
BA_ "Platform_Vivis2_Sig" SG_ 825 ECSValveActivationAllowed 1;
BA_ "GenSigCycleTime" SG_ 825 UnevenLoadWarning_ISig_4 100;
BA_ "GenSigCycleTimeActive" SG_ 825 UnevenLoadWarning_ISig_4 100;
BA_ "GenSigStartValue" SG_ 825 UnevenLoadWarning_ISig_4 3;
BA_ "GenSigMaxLatency" SG_ 825 UnevenLoadWarning_ISig_4 35;
BA_ "Platform_VMCU1_Sig" SG_ 825 UnevenLoadWarning_ISig_4 1;
BA_ "Platform_Vivis2_Sig" SG_ 825 UnevenLoadWarning_ISig_4 1;
BA_ "GenSigCycleTime" SG_ 825 RampLevelRequestACK_ISig_4 100;
BA_ "GenSigCycleTimeActive" SG_ 825 RampLevelRequestACK_ISig_4 100;
BA_ "GenSigStartValue" SG_ 825 RampLevelRequestACK_ISig_4 3;
BA_ "Platform_VMCU1_Sig" SG_ 825 RampLevelRequestACK_ISig_4 1;
BA_ "Platform_Vivis2_Sig" SG_ 825 RampLevelRequestACK_ISig_4 1;
BA_ "GenSigCycleTime" SG_ 825 LoadDistributionSelected_ISig_4 100;
BA_ "GenSigCycleTimeActive" SG_ 825 LoadDistributionSelected_ISig_4 100;
BA_ "GenSigStartValue" SG_ 825 LoadDistributionSelected_ISig_4 15;
BA_ "GenSigMaxLatency" SG_ 825 LoadDistributionSelected_ISig_4 35;
BA_ "Platform_VMCU1_Sig" SG_ 825 LoadDistributionSelected_ISig_4 1;
BA_ "Platform_Vivis2_Sig" SG_ 825 LoadDistributionSelected_ISig_4 1;
BA_ "GenSigCycleTime" SG_ 825 TrailerABSStatus_ISig_4 100;
BA_ "GenSigCycleTimeActive" SG_ 825 TrailerABSStatus_ISig_4 100;
BA_ "GenSigStartValue" SG_ 825 TrailerABSStatus_ISig_4 3;
BA_ "GenSigMaxLatency" SG_ 825 TrailerABSStatus_ISig_4 35;
BA_ "Platform_VMCU1_Sig" SG_ 825 TrailerABSStatus_ISig_4 1;
BA_ "Platform_Vivis2_Sig" SG_ 825 TrailerABSStatus_ISig_4 1;
BA_ "GenSigCycleTime" SG_ 825 LoadDistributionALDChangeACK_ISi 100;
BA_ "GenSigCycleTimeActive" SG_ 825 LoadDistributionALDChangeACK_ISi 100;
BA_ "GenSigStartValue" SG_ 825 LoadDistributionALDChangeACK_ISi 7;
BA_ "GenSigMaxLatency" SG_ 825 LoadDistributionALDChangeACK_ISi 35;
BA_ "Platform_VMCU1_Sig" SG_ 825 LoadDistributionALDChangeACK_ISi 1;
BA_ "Platform_Vivis2_Sig" SG_ 825 LoadDistributionALDChangeACK_ISi 1;
BA_ "SystemSignalLongSymbol" SG_ 825 LoadDistributionALDChangeACK_ISi "LoadDistributionALDChangeACK_ISig_4";
BA_ "GenSigCycleTime" SG_ 825 FogLightRearLamp_stat_ISig_4 100;
BA_ "GenSigCycleTimeActive" SG_ 825 FogLightRearLamp_stat_ISig_4 100;
BA_ "GenSigInactiveValue" SG_ 825 FogLightRearLamp_stat_ISig_4 7;
BA_ "GenSigStartValue" SG_ 825 FogLightRearLamp_stat_ISig_4 7;
BA_ "GenSigMaxLatency" SG_ 825 FogLightRearLamp_stat_ISig_4 35;
BA_ "Platform_VMCU1_Sig" SG_ 825 FogLightRearLamp_stat_ISig_4 1;
BA_ "Platform_Vivis2_Sig" SG_ 825 FogLightRearLamp_stat_ISig_4 1;
BA_ "GenSigCycleTime" SG_ 825 PositionLightRearLamp_stat_ISig_ 100;
BA_ "GenSigCycleTimeActive" SG_ 825 PositionLightRearLamp_stat_ISig_ 100;
BA_ "GenSigInactiveValue" SG_ 825 PositionLightRearLamp_stat_ISig_ 7;
BA_ "GenSigStartValue" SG_ 825 PositionLightRearLamp_stat_ISig_ 7;
BA_ "GenSigMaxLatency" SG_ 825 PositionLightRearLamp_stat_ISig_ 35;
BA_ "Platform_VMCU1_Sig" SG_ 825 PositionLightRearLamp_stat_ISig_ 1;
BA_ "Platform_Vivis2_Sig" SG_ 825 PositionLightRearLamp_stat_ISig_ 1;
BA_ "SystemSignalLongSymbol" SG_ 825 PositionLightRearLamp_stat_ISig_ "PositionLightRearLamp_stat_ISig_4";
BA_ "GenSigCycleTime" SG_ 825 FerryFunctionSwitchChangeACK_ISi 100;
BA_ "GenSigCycleTimeActive" SG_ 825 FerryFunctionSwitchChangeACK_ISi 100;
BA_ "GenSigStartValue" SG_ 825 FerryFunctionSwitchChangeACK_ISi 3;
BA_ "Platform_VMCU1_Sig" SG_ 825 FerryFunctionSwitchChangeACK_ISi 1;
BA_ "Platform_Vivis2_Sig" SG_ 825 FerryFunctionSwitchChangeACK_ISi 1;
BA_ "SystemSignalLongSymbol" SG_ 825 FerryFunctionSwitchChangeACK_ISi "FerryFunctionSwitchChangeACK_ISig_4";
BA_ "GenSigCycleTime" SG_ 825 LiftAxle1AutoLiftSelected_ISig_4 100;
BA_ "GenSigCycleTimeActive" SG_ 825 LiftAxle1AutoLiftSelected_ISig_4 100;
BA_ "GenSigStartValue" SG_ 825 LiftAxle1AutoLiftSelected_ISig_4 3;
BA_ "Platform_Vivis2_Sig" SG_ 825 LiftAxle1AutoLiftSelected_ISig_4 1;
BA_ "GenSigCycleTime" SG_ 825 BrakeLightLamp_stat_ISig_4 100;
BA_ "GenSigCycleTimeActive" SG_ 825 BrakeLightLamp_stat_ISig_4 100;
BA_ "GenSigInactiveValue" SG_ 825 BrakeLightLamp_stat_ISig_4 7;
BA_ "GenSigStartValue" SG_ 825 BrakeLightLamp_stat_ISig_4 7;
BA_ "GenSigMaxLatency" SG_ 825 BrakeLightLamp_stat_ISig_4 35;
BA_ "Platform_VMCU1_Sig" SG_ 825 BrakeLightLamp_stat_ISig_4 1;
BA_ "Platform_Vivis2_Sig" SG_ 825 BrakeLightLamp_stat_ISig_4 1;
BA_ "GenSigCycleTime" SG_ 825 LiftAxle2AutoLiftSelected_ISig_4 100;
BA_ "GenSigCycleTimeActive" SG_ 825 LiftAxle2AutoLiftSelected_ISig_4 100;
BA_ "GenSigStartValue" SG_ 825 LiftAxle2AutoLiftSelected_ISig_4 3;
BA_ "Platform_Vivis2_Sig" SG_ 825 LiftAxle2AutoLiftSelected_ISig_4 1;
BA_ "GenSigCycleTime" SG_ 825 StartupProhibitStatus_ISig_4 100;
BA_ "GenSigCycleTimeActive" SG_ 825 StartupProhibitStatus_ISig_4 100;
BA_ "GenSigStartValue" SG_ 825 StartupProhibitStatus_ISig_4 3;
BA_ "Platform_VMCU1_Sig" SG_ 825 StartupProhibitStatus_ISig_4 1;
BA_ "Platform_Vivis2_Sig" SG_ 825 StartupProhibitStatus_ISig_4 1;
BA_ "GenSigCycleTime" SG_ 825 LiftAxle1LowerACK_ISig_4 100;
BA_ "GenSigCycleTimeActive" SG_ 825 LiftAxle1LowerACK_ISig_4 100;
BA_ "GenSigStartValue" SG_ 825 LiftAxle1LowerACK_ISig_4 7;
BA_ "Platform_Vivis2_Sig" SG_ 825 LiftAxle1LowerACK_ISig_4 1;
BA_ "GenSigCycleTime" SG_ 825 TrailerDirInd_status 100;
BA_ "GenSigCycleTimeActive" SG_ 825 TrailerDirInd_status 100;
BA_ "GenSigStartValue" SG_ 825 TrailerDirInd_status 7;
BA_ "GenSigMaxLatency" SG_ 825 TrailerDirInd_status 23;
BA_ "Platform_VMCU1_Sig" SG_ 825 TrailerDirInd_status 1;
BA_ "Platform_Vivis2_Sig" SG_ 825 TrailerDirInd_status 1;
BA_ "GenSigCycleTime" SG_ 825 DriveLevelPosUserInteraction_ISi 100;
BA_ "GenSigCycleTimeActive" SG_ 825 DriveLevelPosUserInteraction_ISi 100;
BA_ "GenSigStartValue" SG_ 825 DriveLevelPosUserInteraction_ISi 7;
BA_ "Platform_VMCU1_Sig" SG_ 825 DriveLevelPosUserInteraction_ISi 1;
BA_ "Platform_Vivis2_Sig" SG_ 825 DriveLevelPosUserInteraction_ISi 1;
BA_ "SystemSignalLongSymbol" SG_ 825 DriveLevelPosUserInteraction_ISi "DriveLevelPosUserInteraction_ISig_4";
BA_ "GenSigCycleTime" SG_ 948 FrontEndPositionStatus 100;
BA_ "GenSigCycleTimeActive" SG_ 948 FrontEndPositionStatus 100;
BA_ "GenSigInactiveValue" SG_ 948 FrontEndPositionStatus 7;
BA_ "GenSigStartValue" SG_ 948 FrontEndPositionStatus 7;
BA_ "GenSigMaxLatency" SG_ 948 FrontEndPositionStatus 35;
BA_ "Platform_VMCU1_Sig" SG_ 948 FrontEndPositionStatus 1;
BA_ "Platform_Vivis2_Sig" SG_ 948 FrontEndPositionStatus 1;
BA_ "GenSigCycleTime" SG_ 948 DirIndRearLamp_Stat_ISig_4 100;
BA_ "GenSigCycleTimeActive" SG_ 948 DirIndRearLamp_Stat_ISig_4 100;
BA_ "GenSigStartValue" SG_ 948 DirIndRearLamp_Stat_ISig_4 7;
BA_ "Platform_VMCU1_Sig" SG_ 948 DirIndRearLamp_Stat_ISig_4 1;
BA_ "Platform_Vivis2_Sig" SG_ 948 DirIndRearLamp_Stat_ISig_4 1;
BA_ "GenSigCycleTime" SG_ 948 FrontAxleInBumperRange_ISig_4 100;
BA_ "GenSigCycleTimeActive" SG_ 948 FrontAxleInBumperRange_ISig_4 100;
BA_ "GenSigStartValue" SG_ 948 FrontAxleInBumperRange_ISig_4 3;
BA_ "GenSigMaxLatency" SG_ 948 FrontAxleInBumperRange_ISig_4 27;
BA_ "NeedsUpdateBit" SG_ 948 FrontAxleInBumperRange_ISig_4 1;
BA_ "Platform_VMCU1_Sig" SG_ 948 FrontAxleInBumperRange_ISig_4 1;
BA_ "Platform_Vivis2_Sig" SG_ 948 FrontAxleInBumperRange_ISig_4 1;
BA_ "GenSigSendType" SG_ 948 FrontAxleInBumperRange_UB_ISig_4 7;
BA_ "Platform_VMCU1_Sig" SG_ 948 FrontAxleInBumperRange_UB_ISig_4 1;
BA_ "Platform_Vivis2_Sig" SG_ 948 FrontAxleInBumperRange_UB_ISig_4 1;
BA_ "GenSigCycleTime" SG_ 948 FrontRollAngleRef 100;
BA_ "GenSigCycleTimeActive" SG_ 948 FrontRollAngleRef 100;
BA_ "GenSigStartValue" SG_ 948 FrontRollAngleRef 65535;
BA_ "GenSigMaxLatency" SG_ 948 FrontRollAngleRef 57;
BA_ "Platform_VMCU1_Sig" SG_ 948 FrontRollAngleRef 1;
BA_ "Platform_Vivis2_Sig" SG_ 948 FrontRollAngleRef 1;
BA_ "GenSigCycleTime" SG_ 948 FrontSideKneelingAngleRef 100;
BA_ "GenSigCycleTimeActive" SG_ 948 FrontSideKneelingAngleRef 100;
BA_ "GenSigStartValue" SG_ 948 FrontSideKneelingAngleRef 65535;
BA_ "Platform_VMCU1_Sig" SG_ 948 FrontSideKneelingAngleRef 1;
BA_ "Platform_Vivis2_Sig" SG_ 948 FrontSideKneelingAngleRef 1;
BA_ "GenSigCycleTime" SG_ 948 LoadDistributionRequestedACK_ISi 100;
BA_ "GenSigCycleTimeActive" SG_ 948 LoadDistributionRequestedACK_ISi 100;
BA_ "GenSigStartValue" SG_ 948 LoadDistributionRequestedACK_ISi 7;
BA_ "Platform_VMCU1_Sig" SG_ 948 LoadDistributionRequestedACK_ISi 1;
BA_ "Platform_Vivis2_Sig" SG_ 948 LoadDistributionRequestedACK_ISi 1;
BA_ "SystemSignalLongSymbol" SG_ 948 LoadDistributionRequestedACK_ISi "LoadDistributionRequestedACK_ISig_4";
BA_ "GenSigCycleTime" SG_ 948 TotalFrontBellowTorqueRef 100;
BA_ "GenSigCycleTimeActive" SG_ 948 TotalFrontBellowTorqueRef 100;
BA_ "GenSigStartValue" SG_ 948 TotalFrontBellowTorqueRef 65535;
BA_ "GenSigMaxLatency" SG_ 948 TotalFrontBellowTorqueRef 57;
BA_ "Platform_VMCU1_Sig" SG_ 948 TotalFrontBellowTorqueRef 1;
BA_ "Platform_Vivis2_Sig" SG_ 948 TotalFrontBellowTorqueRef 1;
BA_ "GenSigCycleTime" SG_ 948 Rear1ClutchStatus 100;
BA_ "GenSigCycleTimeActive" SG_ 948 Rear1ClutchStatus 100;
BA_ "GenSigStartValue" SG_ 948 Rear1ClutchStatus 3;
BA_ "Platform_VMCU1_Sig" SG_ 948 Rear1ClutchStatus 1;
BA_ "Platform_Vivis2_Sig" SG_ 948 Rear1ClutchStatus 1;
BA_ "GenSigCycleTime" SG_ 947 FPBRMMIStat_FPBRChangeAck_ISig_4 100;
BA_ "GenSigCycleTimeActive" SG_ 947 FPBRMMIStat_FPBRChangeAck_ISig_4 100;
BA_ "GenSigStartValue" SG_ 947 FPBRMMIStat_FPBRChangeAck_ISig_4 3;
BA_ "Platform_VMCU1_Sig" SG_ 947 FPBRMMIStat_FPBRChangeAck_ISig_4 1;
BA_ "Platform_Vivis2_Sig" SG_ 947 FPBRMMIStat_FPBRChangeAck_ISig_4 1;
BA_ "GenSigCycleTime" SG_ 947 RelativeLevelRearAxleRight_ISig_ 100;
BA_ "GenSigCycleTimeActive" SG_ 947 RelativeLevelRearAxleRight_ISig_ 100;
BA_ "GenSigStartValue" SG_ 947 RelativeLevelRearAxleRight_ISig_ 65535;
BA_ "GenSigMaxLatency" SG_ 947 RelativeLevelRearAxleRight_ISig_ 56;
BA_ "Platform_VMCU1_Sig" SG_ 947 RelativeLevelRearAxleRight_ISig_ 1;
BA_ "Platform_Vivis2_Sig" SG_ 947 RelativeLevelRearAxleRight_ISig_ 1;
BA_ "SystemSignalLongSymbol" SG_ 947 RelativeLevelRearAxleRight_ISig_ "RelativeLevelRearAxleRight_ISig_4";
BA_ "GenSigCycleTime" SG_ 947 FPBRMMIStat_FPBRStatusInd_ISig_4 100;
BA_ "GenSigCycleTimeActive" SG_ 947 FPBRMMIStat_FPBRStatusInd_ISig_4 100;
BA_ "GenSigStartValue" SG_ 947 FPBRMMIStat_FPBRStatusInd_ISig_4 3;
BA_ "Platform_VMCU1_Sig" SG_ 947 FPBRMMIStat_FPBRStatusInd_ISig_4 1;
BA_ "Platform_Vivis2_Sig" SG_ 947 FPBRMMIStat_FPBRStatusInd_ISig_4 1;
BA_ "GenSigCycleTime" SG_ 947 LiftAxle1LiftAllowed_Stat 100;
BA_ "GenSigCycleTimeActive" SG_ 947 LiftAxle1LiftAllowed_Stat 100;
BA_ "GenSigStartValue" SG_ 947 LiftAxle1LiftAllowed_Stat 7;
BA_ "Platform_VMCU1_Sig" SG_ 947 LiftAxle1LiftAllowed_Stat 1;
BA_ "Platform_Vivis2_Sig" SG_ 947 LiftAxle1LiftAllowed_Stat 1;
BA_ "GenSigCycleTime" SG_ 947 FrontLevRefCtrl_ShortPushCnt 100;
BA_ "GenSigCycleTimeActive" SG_ 947 FrontLevRefCtrl_ShortPushCnt 100;
BA_ "GenSigStartValue" SG_ 947 FrontLevRefCtrl_ShortPushCnt 255;
BA_ "Platform_VMCU1_Sig" SG_ 947 FrontLevRefCtrl_ShortPushCnt 1;
BA_ "Platform_Vivis2_Sig" SG_ 947 FrontLevRefCtrl_ShortPushCnt 1;
BA_ "GenSigCycleTime" SG_ 947 FrontLevRefCtrl_LevelRef 100;
BA_ "GenSigCycleTimeActive" SG_ 947 FrontLevRefCtrl_LevelRef 100;
BA_ "GenSigStartValue" SG_ 947 FrontLevRefCtrl_LevelRef 65535;
BA_ "Platform_VMCU1_Sig" SG_ 947 FrontLevRefCtrl_LevelRef 1;
BA_ "Platform_Vivis2_Sig" SG_ 947 FrontLevRefCtrl_LevelRef 1;
BA_ "GenSigCycleTime" SG_ 947 RelativeLevelRearAxleLeft_ISig_4 100;
BA_ "GenSigCycleTimeActive" SG_ 947 RelativeLevelRearAxleLeft_ISig_4 100;
BA_ "GenSigStartValue" SG_ 947 RelativeLevelRearAxleLeft_ISig_4 65535;
BA_ "GenSigMaxLatency" SG_ 947 RelativeLevelRearAxleLeft_ISig_4 56;
BA_ "Platform_VMCU1_Sig" SG_ 947 RelativeLevelRearAxleLeft_ISig_4 1;
BA_ "Platform_Vivis2_Sig" SG_ 947 RelativeLevelRearAxleLeft_ISig_4 1;
BA_ "GenSigCycleTime" SG_ 530 AirDumpStatus_ISig_4 100;
BA_ "GenSigCycleTimeActive" SG_ 530 AirDumpStatus_ISig_4 100;
BA_ "GenSigStartValue" SG_ 530 AirDumpStatus_ISig_4 7;
BA_ "Platform_Vivis2_Sig" SG_ 530 AirDumpStatus_ISig_4 1;
BA_ "GenSigCycleTime" SG_ 530 RearAxle2DiffLock_stat_ISig_4 100;
BA_ "GenSigCycleTimeActive" SG_ 530 RearAxle2DiffLock_stat_ISig_4 100;
BA_ "GenSigStartValue" SG_ 530 RearAxle2DiffLock_stat_ISig_4 3;
BA_ "GenSigMaxLatency" SG_ 530 RearAxle2DiffLock_stat_ISig_4 23;
BA_ "NeedsUpdateBit" SG_ 530 RearAxle2DiffLock_stat_ISig_4 1;
BA_ "Platform_VMCU1_Sig" SG_ 530 RearAxle2DiffLock_stat_ISig_4 1;
BA_ "Platform_Vivis2_Sig" SG_ 530 RearAxle2DiffLock_stat_ISig_4 1;
BA_ "GenSigSendType" SG_ 530 SWBrakeSwitch_UB_ISig_4 7;
BA_ "Platform_VMCU1_Sig" SG_ 530 SWBrakeSwitch_UB_ISig_4 1;
BA_ "Platform_Vivis2_Sig" SG_ 530 SWBrakeSwitch_UB_ISig_4 1;
BA_ "GenSigCycleTime" SG_ 530 SWBrakeSwitch_ISig_4 100;
BA_ "GenSigCycleTimeActive" SG_ 530 SWBrakeSwitch_ISig_4 100;
BA_ "GenSigStartValue" SG_ 530 SWBrakeSwitch_ISig_4 3;
BA_ "GenSigMaxLatency" SG_ 530 SWBrakeSwitch_ISig_4 23;
BA_ "NeedsUpdateBit" SG_ 530 SWBrakeSwitch_ISig_4 1;
BA_ "Platform_VMCU1_Sig" SG_ 530 SWBrakeSwitch_ISig_4 1;
BA_ "Platform_Vivis2_Sig" SG_ 530 SWBrakeSwitch_ISig_4 1;
BA_ "GenSigCycleTime" SG_ 530 RearAxle1DiffLock_stat_ISig_4 100;
BA_ "GenSigCycleTimeActive" SG_ 530 RearAxle1DiffLock_stat_ISig_4 100;
BA_ "GenSigStartValue" SG_ 530 RearAxle1DiffLock_stat_ISig_4 3;
BA_ "GenSigMaxLatency" SG_ 530 RearAxle1DiffLock_stat_ISig_4 23;
BA_ "NeedsUpdateBit" SG_ 530 RearAxle1DiffLock_stat_ISig_4 1;
BA_ "Platform_VMCU1_Sig" SG_ 530 RearAxle1DiffLock_stat_ISig_4 1;
BA_ "Platform_Vivis2_Sig" SG_ 530 RearAxle1DiffLock_stat_ISig_4 1;
BA_ "GenSigCycleTime" SG_ 530 SupplyPressure_ISig_4 100;
BA_ "GenSigCycleTimeActive" SG_ 530 SupplyPressure_ISig_4 100;
BA_ "GenSigStartValue" SG_ 530 SupplyPressure_ISig_4 255;
BA_ "GenSigMaxLatency" SG_ 530 SupplyPressure_ISig_4 55;
BA_ "Platform_VMCU1_Sig" SG_ 530 SupplyPressure_ISig_4 1;
BA_ "Platform_Vivis2_Sig" SG_ 530 SupplyPressure_ISig_4 1;
BA_ "GenSigSendType" SG_ 530 RearAxle2DiffLock_stat_UB_ISig_4 7;
BA_ "Platform_VMCU1_Sig" SG_ 530 RearAxle2DiffLock_stat_UB_ISig_4 1;
BA_ "Platform_Vivis2_Sig" SG_ 530 RearAxle2DiffLock_stat_UB_ISig_4 1;
BA_ "GenSigCycleTime" SG_ 530 BackToDriveReqACK_ISig_4 100;
BA_ "GenSigCycleTimeActive" SG_ 530 BackToDriveReqACK_ISig_4 100;
BA_ "GenSigStartValue" SG_ 530 BackToDriveReqACK_ISig_4 3;
BA_ "Platform_VMCU1_Sig" SG_ 530 BackToDriveReqACK_ISig_4 1;
BA_ "Platform_Vivis2_Sig" SG_ 530 BackToDriveReqACK_ISig_4 1;
BA_ "GenSigCycleTime" SG_ 530 PitchAngleRef_ISig_4 100;
BA_ "GenSigCycleTimeActive" SG_ 530 PitchAngleRef_ISig_4 100;
BA_ "GenSigStartValue" SG_ 530 PitchAngleRef_ISig_4 65535;
BA_ "GenSigMaxLatency" SG_ 530 PitchAngleRef_ISig_4 55;
BA_ "Platform_VMCU1_Sig" SG_ 530 PitchAngleRef_ISig_4 1;
BA_ "Platform_Vivis2_Sig" SG_ 530 PitchAngleRef_ISig_4 1;
BA_ "GenSigSendType" SG_ 530 TrailerConnected_UB_ISig_4 7;
BA_ "Platform_VMCU1_Sig" SG_ 530 TrailerConnected_UB_ISig_4 1;
BA_ "Platform_Vivis2_Sig" SG_ 530 TrailerConnected_UB_ISig_4 1;
BA_ "GenSigSendType" SG_ 530 CentralRearDiffLock_stat_UB_ISig 7;
BA_ "Platform_VMCU1_Sig" SG_ 530 CentralRearDiffLock_stat_UB_ISig 1;
BA_ "Platform_Vivis2_Sig" SG_ 530 CentralRearDiffLock_stat_UB_ISig 1;
BA_ "SystemSignalLongSymbol" SG_ 530 CentralRearDiffLock_stat_UB_ISig "CentralRearDiffLock_stat_UB_ISig_4";
BA_ "GenSigCycleTime" SG_ 530 PitchAngle_ISig_4 100;
BA_ "GenSigCycleTimeActive" SG_ 530 PitchAngle_ISig_4 100;
BA_ "GenSigStartValue" SG_ 530 PitchAngle_ISig_4 65535;
BA_ "GenSigMaxLatency" SG_ 530 PitchAngle_ISig_4 55;
BA_ "Platform_VMCU1_Sig" SG_ 530 PitchAngle_ISig_4 1;
BA_ "Platform_Vivis2_Sig" SG_ 530 PitchAngle_ISig_4 1;
BA_ "GenSigCycleTime" SG_ 530 TrailerWithoutABS_ISig_4 100;
BA_ "GenSigCycleTimeActive" SG_ 530 TrailerWithoutABS_ISig_4 100;
BA_ "GenSigStartValue" SG_ 530 TrailerWithoutABS_ISig_4 3;
BA_ "GenSigMaxLatency" SG_ 530 TrailerWithoutABS_ISig_4 35;
BA_ "NeedsUpdateBit" SG_ 530 TrailerWithoutABS_ISig_4 1;
BA_ "Platform_VMCU1_Sig" SG_ 530 TrailerWithoutABS_ISig_4 1;
BA_ "Platform_Vivis2_Sig" SG_ 530 TrailerWithoutABS_ISig_4 1;
BA_ "GenSigSendType" SG_ 530 TrailerWithoutABS_UB_ISig_4 7;
BA_ "Platform_VMCU1_Sig" SG_ 530 TrailerWithoutABS_UB_ISig_4 1;
BA_ "Platform_Vivis2_Sig" SG_ 530 TrailerWithoutABS_UB_ISig_4 1;
BA_ "GenSigCycleTime" SG_ 530 TrailerConnected_ISig_4 100;
BA_ "GenSigCycleTimeActive" SG_ 530 TrailerConnected_ISig_4 100;
BA_ "GenSigStartValue" SG_ 530 TrailerConnected_ISig_4 3;
BA_ "GenSigMaxLatency" SG_ 530 TrailerConnected_ISig_4 35;
BA_ "NeedsUpdateBit" SG_ 530 TrailerConnected_ISig_4 1;
BA_ "Platform_VMCU1_Sig" SG_ 530 TrailerConnected_ISig_4 1;
BA_ "Platform_Vivis2_Sig" SG_ 530 TrailerConnected_ISig_4 1;
BA_ "GenSigCycleTime" SG_ 530 CentralRearDiffLock_stat_ISig_4 100;
BA_ "GenSigCycleTimeActive" SG_ 530 CentralRearDiffLock_stat_ISig_4 100;
BA_ "GenSigStartValue" SG_ 530 CentralRearDiffLock_stat_ISig_4 3;
BA_ "GenSigMaxLatency" SG_ 530 CentralRearDiffLock_stat_ISig_4 23;
BA_ "NeedsUpdateBit" SG_ 530 CentralRearDiffLock_stat_ISig_4 1;
BA_ "Platform_VMCU1_Sig" SG_ 530 CentralRearDiffLock_stat_ISig_4 1;
BA_ "Platform_Vivis2_Sig" SG_ 530 CentralRearDiffLock_stat_ISig_4 1;
BA_ "GenSigSendType" SG_ 530 RearAxle1DiffLock_stat_UB_ISig_4 7;
BA_ "Platform_VMCU1_Sig" SG_ 530 RearAxle1DiffLock_stat_UB_ISig_4 1;
BA_ "Platform_Vivis2_Sig" SG_ 530 RearAxle1DiffLock_stat_UB_ISig_4 1;
BA_ "GenSigCycleTime" SG_ 528 RollEndPositionStatus_ISig_4 100;
BA_ "GenSigCycleTimeActive" SG_ 528 RollEndPositionStatus_ISig_4 100;
BA_ "GenSigInactiveValue" SG_ 528 RollEndPositionStatus_ISig_4 7;
BA_ "GenSigStartValue" SG_ 528 RollEndPositionStatus_ISig_4 7;
BA_ "Platform_VMCU1_Sig" SG_ 528 RollEndPositionStatus_ISig_4 1;
BA_ "Platform_Vivis2_Sig" SG_ 528 RollEndPositionStatus_ISig_4 1;
BA_ "GenSigCycleTime" SG_ 528 FrontFerryFunctionCmd_ISig_4 100;
BA_ "GenSigCycleTimeActive" SG_ 528 FrontFerryFunctionCmd_ISig_4 100;
BA_ "GenSigStartValue" SG_ 528 FrontFerryFunctionCmd_ISig_4 7;
BA_ "GenSigMaxLatency" SG_ 528 FrontFerryFunctionCmd_ISig_4 23;
BA_ "Platform_VMCU1_Sig" SG_ 528 FrontFerryFunctionCmd_ISig_4 1;
BA_ "Platform_Vivis2_Sig" SG_ 528 FrontFerryFunctionCmd_ISig_4 1;
BA_ "GenSigCycleTime" SG_ 528 RideHeightFunctionStatus_ISig_4 100;
BA_ "GenSigCycleTimeActive" SG_ 528 RideHeightFunctionStatus_ISig_4 100;
BA_ "GenSigStartValue" SG_ 528 RideHeightFunctionStatus_ISig_4 15;
BA_ "GenSigMaxLatency" SG_ 528 RideHeightFunctionStatus_ISig_4 23;
BA_ "Platform_VMCU1_Sig" SG_ 528 RideHeightFunctionStatus_ISig_4 1;
BA_ "Platform_Vivis2_Sig" SG_ 528 RideHeightFunctionStatus_ISig_4 1;
BA_ "GenSigCycleTime" SG_ 528 HeightControlMode_ISig_4 100;
BA_ "GenSigCycleTimeActive" SG_ 528 HeightControlMode_ISig_4 100;
BA_ "GenSigStartValue" SG_ 528 HeightControlMode_ISig_4 15;
BA_ "GenSigMaxLatency" SG_ 528 HeightControlMode_ISig_4 23;
BA_ "Platform_VMCU1_Sig" SG_ 528 HeightControlMode_ISig_4 1;
BA_ "Platform_Vivis2_Sig" SG_ 528 HeightControlMode_ISig_4 1;
BA_ "GenSigCycleTime" SG_ 528 ECSShutdownCmd_ISig_4 100;
BA_ "GenSigCycleTimeActive" SG_ 528 ECSShutdownCmd_ISig_4 100;
BA_ "GenSigStartValue" SG_ 528 ECSShutdownCmd_ISig_4 3;
BA_ "Platform_VMCU1_Sig" SG_ 528 ECSShutdownCmd_ISig_4 1;
BA_ "Platform_Vivis2_Sig" SG_ 528 ECSShutdownCmd_ISig_4 1;
BA_ "GenSigCycleTime" SG_ 528 FerryFunctionStatus_ISig_4 100;
BA_ "GenSigCycleTimeActive" SG_ 528 FerryFunctionStatus_ISig_4 100;
BA_ "GenSigStartValue" SG_ 528 FerryFunctionStatus_ISig_4 7;
BA_ "GenSigMaxLatency" SG_ 528 FerryFunctionStatus_ISig_4 35;
BA_ "Platform_VMCU1_Sig" SG_ 528 FerryFunctionStatus_ISig_4 1;
BA_ "Platform_Vivis2_Sig" SG_ 528 FerryFunctionStatus_ISig_4 1;
BA_ "GenSigCycleTime" SG_ 528 LevelControlInformation_ISig_4 100;
BA_ "GenSigCycleTimeActive" SG_ 528 LevelControlInformation_ISig_4 100;
BA_ "GenSigStartValue" SG_ 528 LevelControlInformation_ISig_4 15;
BA_ "GenSigMaxLatency" SG_ 528 LevelControlInformation_ISig_4 23;
BA_ "NeedsUpdateBit" SG_ 528 LevelControlInformation_ISig_4 1;
BA_ "Platform_VMCU1_Sig" SG_ 528 LevelControlInformation_ISig_4 1;
BA_ "Platform_Vivis2_Sig" SG_ 528 LevelControlInformation_ISig_4 1;
BA_ "GenSigCycleTime" SG_ 528 ChangeKneelACK_ISig_4 100;
BA_ "GenSigCycleTimeActive" SG_ 528 ChangeKneelACK_ISig_4 100;
BA_ "GenSigStartValue" SG_ 528 ChangeKneelACK_ISig_4 3;
BA_ "Platform_VMCU1_Sig" SG_ 528 ChangeKneelACK_ISig_4 1;
BA_ "Platform_Vivis2_Sig" SG_ 528 ChangeKneelACK_ISig_4 1;
BA_ "GenSigCycleTime" SG_ 528 RearEndPositionStatus_ISig_4 100;
BA_ "GenSigCycleTimeActive" SG_ 528 RearEndPositionStatus_ISig_4 100;
BA_ "GenSigInactiveValue" SG_ 528 RearEndPositionStatus_ISig_4 7;
BA_ "GenSigStartValue" SG_ 528 RearEndPositionStatus_ISig_4 7;
BA_ "Platform_VMCU1_Sig" SG_ 528 RearEndPositionStatus_ISig_4 1;
BA_ "Platform_Vivis2_Sig" SG_ 528 RearEndPositionStatus_ISig_4 1;
BA_ "GenSigCycleTime" SG_ 528 RampHeightOutsideTargetRange_ISi 100;
BA_ "GenSigCycleTimeActive" SG_ 528 RampHeightOutsideTargetRange_ISi 100;
BA_ "GenSigInactiveValue" SG_ 528 RampHeightOutsideTargetRange_ISi 7;
BA_ "GenSigStartValue" SG_ 528 RampHeightOutsideTargetRange_ISi 7;
BA_ "Platform_VMCU1_Sig" SG_ 528 RampHeightOutsideTargetRange_ISi 1;
BA_ "Platform_Vivis2_Sig" SG_ 528 RampHeightOutsideTargetRange_ISi 1;
BA_ "SystemSignalLongSymbol" SG_ 528 RampHeightOutsideTargetRange_ISi "RampHeightOutsideTargetRange_ISig_4";
BA_ "GenSigCycleTime" SG_ 528 LoadDistributionFuncSelected_ISi 100;
BA_ "GenSigCycleTimeActive" SG_ 528 LoadDistributionFuncSelected_ISi 100;
BA_ "GenSigStartValue" SG_ 528 LoadDistributionFuncSelected_ISi 15;
BA_ "GenSigMaxLatency" SG_ 528 LoadDistributionFuncSelected_ISi 23;
BA_ "Platform_VMCU1_Sig" SG_ 528 LoadDistributionFuncSelected_ISi 1;
BA_ "Platform_Vivis2_Sig" SG_ 528 LoadDistributionFuncSelected_ISi 1;
BA_ "SystemSignalLongSymbol" SG_ 528 LoadDistributionFuncSelected_ISi "LoadDistributionFuncSelected_ISig_4";
BA_ "GenSigCycleTime" SG_ 528 HeightAdjustmentAllowed_ISig_4 100;
BA_ "GenSigCycleTimeActive" SG_ 528 HeightAdjustmentAllowed_ISig_4 100;
BA_ "GenSigStartValue" SG_ 528 HeightAdjustmentAllowed_ISig_4 3;
BA_ "Platform_VMCU1_Sig" SG_ 528 HeightAdjustmentAllowed_ISig_4 1;
BA_ "Platform_Vivis2_Sig" SG_ 528 HeightAdjustmentAllowed_ISig_4 1;
BA_ "GenSigSendType" SG_ 528 LevelControlInformation_UB_ISig_ 7;
BA_ "Platform_VMCU1_Sig" SG_ 528 LevelControlInformation_UB_ISig_ 1;
BA_ "Platform_Vivis2_Sig" SG_ 528 LevelControlInformation_UB_ISig_ 1;
BA_ "SystemSignalLongSymbol" SG_ 528 LevelControlInformation_UB_ISig_ "LevelControlInformation_UB_ISig_4";
BA_ "GenSigCycleTime" SG_ 528 KneelingInformation_ISig_4 100;
BA_ "GenSigCycleTimeActive" SG_ 528 KneelingInformation_ISig_4 100;
BA_ "GenSigStartValue" SG_ 528 KneelingInformation_ISig_4 15;
BA_ "Platform_VMCU1_Sig" SG_ 528 KneelingInformation_ISig_4 1;
BA_ "Platform_Vivis2_Sig" SG_ 528 KneelingInformation_ISig_4 1;
BA_ "GenSigCycleTime" SG_ 528 KneelingStatusHMI_ISig_4 100;
BA_ "GenSigCycleTimeActive" SG_ 528 KneelingStatusHMI_ISig_4 100;
BA_ "GenSigStartValue" SG_ 528 KneelingStatusHMI_ISig_4 3;
BA_ "Platform_VMCU1_Sig" SG_ 528 KneelingStatusHMI_ISig_4 1;
BA_ "Platform_Vivis2_Sig" SG_ 528 KneelingStatusHMI_ISig_4 1;
BA_ "GenSigCycleTime" SG_ 528 LiftAxle1PositionStatus_ISig_4 100;
BA_ "GenSigCycleTimeActive" SG_ 528 LiftAxle1PositionStatus_ISig_4 100;
BA_ "GenSigStartValue" SG_ 528 LiftAxle1PositionStatus_ISig_4 7;
BA_ "GenSigMaxLatency" SG_ 528 LiftAxle1PositionStatus_ISig_4 23;
BA_ "Platform_VMCU1_Sig" SG_ 528 LiftAxle1PositionStatus_ISig_4 1;
BA_ "Platform_Vivis2_Sig" SG_ 528 LiftAxle1PositionStatus_ISig_4 1;
BA_ "GenSigCycleTime" SG_ 528 VehicleDynamicSuspProhibitStat_I 100;
BA_ "GenSigCycleTimeActive" SG_ 528 VehicleDynamicSuspProhibitStat_I 100;
BA_ "GenSigStartValue" SG_ 528 VehicleDynamicSuspProhibitStat_I 3;
BA_ "Platform_VMCU1_Sig" SG_ 528 VehicleDynamicSuspProhibitStat_I 1;
BA_ "Platform_Vivis2_Sig" SG_ 528 VehicleDynamicSuspProhibitStat_I 1;
BA_ "SystemSignalLongSymbol" SG_ 528 VehicleDynamicSuspProhibitStat_I "VehicleDynamicSuspProhibitStat_ISig_4";
BA_ "GenSigCycleTime" SG_ 528 LiftAxle2PositionStatus_ISig_4 100;
BA_ "GenSigCycleTimeActive" SG_ 528 LiftAxle2PositionStatus_ISig_4 100;
BA_ "GenSigStartValue" SG_ 528 LiftAxle2PositionStatus_ISig_4 7;
BA_ "GenSigMaxLatency" SG_ 528 LiftAxle2PositionStatus_ISig_4 23;
BA_ "Platform_VMCU1_Sig" SG_ 528 LiftAxle2PositionStatus_ISig_4 1;
BA_ "Platform_Vivis2_Sig" SG_ 528 LiftAxle2PositionStatus_ISig_4 1;
BA_ "GenSigCycleTime" SG_ 528 RideHeightStatus_ISig_4 100;
BA_ "GenSigCycleTimeActive" SG_ 528 RideHeightStatus_ISig_4 100;
BA_ "GenSigStartValue" SG_ 528 RideHeightStatus_ISig_4 15;
BA_ "GenSigMaxLatency" SG_ 528 RideHeightStatus_ISig_4 23;
BA_ "Platform_VMCU1_Sig" SG_ 528 RideHeightStatus_ISig_4 1;
BA_ "Platform_Vivis2_Sig" SG_ 528 RideHeightStatus_ISig_4 1;
BA_ "GenSigCycleTime" SG_ 528 DirInd_Rear_Status_ISig_4 100;
BA_ "GenSigCycleTimeActive" SG_ 528 DirInd_Rear_Status_ISig_4 100;
BA_ "GenSigStartValue" SG_ 528 DirInd_Rear_Status_ISig_4 7;
BA_ "GenSigMaxLatency" SG_ 528 DirInd_Rear_Status_ISig_4 23;
BA_ "Platform_VMCU1_Sig" SG_ 528 DirInd_Rear_Status_ISig_4 1;
BA_ "Platform_Vivis2_Sig" SG_ 528 DirInd_Rear_Status_ISig_4 1;
BA_REL_ "GenSigFirstTimeoutTime" BU_SG_REL_ RCIOM SG_ 945 ActualEngineRetarderPercentTrq_I 3000;
BA_REL_ "GenSigTimeoutTime" BU_SG_REL_ RCIOM SG_ 945 ActualEngineRetarderPercentTrq_I 300;
BA_REL_ "GenSigFirstTimeoutTime" BU_SG_REL_ CCIOM SG_ 945 ActualEnginePercentTorque_ISig_4 3000;
BA_REL_ "GenSigTimeoutTime" BU_SG_REL_ CCIOM SG_ 945 ActualEnginePercentTorque_ISig_4 500;
BA_REL_ "GenSigFirstTimeoutTime" BU_SG_REL_ RCIOM SG_ 945 ActualEnginePercentTorque_ISig_4 3000;
BA_REL_ "GenSigTimeoutTime" BU_SG_REL_ RCIOM SG_ 945 ActualEnginePercentTorque_ISig_4 500;
BA_REL_ "GenSigFirstTimeoutTime" BU_SG_REL_ RCIOM SG_ 945 NominalFrictionPercentTorque_ISi 3000;
BA_REL_ "GenSigTimeoutTime" BU_SG_REL_ RCIOM SG_ 945 NominalFrictionPercentTorque_ISi 500;
BA_REL_ "GenSigFirstTimeoutTime" BU_SG_REL_ CCIOM SG_ 945 EcoRollActiveStatus_ISig_4 3000;
BA_REL_ "GenSigTimeoutTime" BU_SG_REL_ CCIOM SG_ 945 EcoRollActiveStatus_ISig_4 300;
BA_REL_ "GenSigFirstTimeoutTime" BU_SG_REL_ RCIOM SG_ 945 EngineReferenceTorque_ISig_4 3000;
BA_REL_ "GenSigTimeoutTime" BU_SG_REL_ RCIOM SG_ 945 EngineReferenceTorque_ISig_4 500;
BA_REL_ "GenSigFirstTimeoutTime" BU_SG_REL_ RCIOM SG_ 928 RrRrItrWhlDiffLckActvnDrvrReq_IS 3000;
BA_REL_ "GenSigTimeoutTime" BU_SG_REL_ RCIOM SG_ 928 RrRrItrWhlDiffLckActvnDrvrReq_IS 500;
BA_REL_ "GenSigFirstTimeoutTime" BU_SG_REL_ CCIOM SG_ 928 EngineSpeed_ISig_4 3000;
BA_REL_ "GenSigTimeoutTime" BU_SG_REL_ CCIOM SG_ 928 EngineSpeed_ISig_4 500;
BA_REL_ "GenSigFirstTimeoutTime" BU_SG_REL_ RCIOM SG_ 928 LiftAxle1Request 3000;
BA_REL_ "GenSigTimeoutTime" BU_SG_REL_ RCIOM SG_ 928 LiftAxle1Request 270;
BA_REL_ "GenSigFirstTimeoutTime" BU_SG_REL_ RCIOM SG_ 928 Rear1ClutchRequest 3000;
BA_REL_ "GenSigTimeoutTime" BU_SG_REL_ RCIOM SG_ 928 Rear1ClutchRequest 270;
BA_REL_ "GenSigFirstTimeoutTime" BU_SG_REL_ CCIOM SG_ 928 FrontWheelDifflockRequest_ISig_4 3000;
BA_REL_ "GenSigTimeoutTime" BU_SG_REL_ CCIOM SG_ 928 FrontWheelDifflockRequest_ISig_4 500;
BA_REL_ "GenSigFirstTimeoutTime" BU_SG_REL_ RCIOM SG_ 827 FrAxleLeftWheelRelativeSpeed_ISi 3000;
BA_REL_ "GenSigTimeoutTime" BU_SG_REL_ RCIOM SG_ 827 FrAxleLeftWheelRelativeSpeed_ISi 240;
BA_REL_ "GenSigFirstTimeoutTime" BU_SG_REL_ RCIOM SG_ 827 FrAxleRightWheelRelativeSpeed_IS 3000;
BA_REL_ "GenSigTimeoutTime" BU_SG_REL_ RCIOM SG_ 827 FrAxleRightWheelRelativeSpeed_IS 240;
BA_REL_ "GenSigFirstTimeoutTime" BU_SG_REL_ RCIOM SG_ 827 FrontAxleSpeed_ISig_4 3000;
BA_REL_ "GenSigTimeoutTime" BU_SG_REL_ RCIOM SG_ 827 FrontAxleSpeed_ISig_4 240;
BA_REL_ "GenSigFirstTimeoutTime" BU_SG_REL_ CCIOM SG_ 827 FrontAxleSpeed_ISig_4 3000;
BA_REL_ "GenSigTimeoutTime" BU_SG_REL_ CCIOM SG_ 827 FrontAxleSpeed_ISig_4 240;
BA_REL_ "GenSigFirstTimeoutTime" BU_SG_REL_ RCIOM SG_ 537 LiftAxle2LiftPositionRequest_ISi 3000;
BA_REL_ "GenSigTimeoutTime" BU_SG_REL_ RCIOM SG_ 537 LiftAxle2LiftPositionRequest_ISi 500;
BA_REL_ "GenSigFirstTimeoutTime" BU_SG_REL_ RCIOM SG_ 537 LoadDistributionChangeRequest_IS 3000;
BA_REL_ "GenSigTimeoutTime" BU_SG_REL_ RCIOM SG_ 537 LoadDistributionChangeRequest_IS 500;
BA_REL_ "GenSigFirstTimeoutTime" BU_SG_REL_ RCIOM SG_ 537 AltLoadDistribution_rqst_ISig_4 3000;
BA_REL_ "GenSigTimeoutTime" BU_SG_REL_ RCIOM SG_ 537 AltLoadDistribution_rqst_ISig_4 500;
BA_REL_ "GenSigFirstTimeoutTime" BU_SG_REL_ RCIOM SG_ 537 LiftAxle1LiftPositionRequest_ISi 3000;
BA_REL_ "GenSigTimeoutTime" BU_SG_REL_ RCIOM SG_ 537 LiftAxle1LiftPositionRequest_ISi 500;
BA_REL_ "GenSigFirstTimeoutTime" BU_SG_REL_ RCIOM SG_ 537 RampLevelRequest_ISig_4 3000;
BA_REL_ "GenSigTimeoutTime" BU_SG_REL_ RCIOM SG_ 537 RampLevelRequest_ISig_4 150;
BA_REL_ "GenSigFirstTimeoutTime" BU_SG_REL_ RCIOM SG_ 537 RampLevelStorageRequest_ISig_4 3000;
BA_REL_ "GenSigTimeoutTime" BU_SG_REL_ RCIOM SG_ 537 RampLevelStorageRequest_ISig_4 150;
BA_REL_ "GenSigFirstTimeoutTime" BU_SG_REL_ RCIOM SG_ 537 RideHeightFunctionRequest_ISig_4 3000;
BA_REL_ "GenSigTimeoutTime" BU_SG_REL_ RCIOM SG_ 537 RideHeightFunctionRequest_ISig_4 120;
BA_REL_ "GenSigFirstTimeoutTime" BU_SG_REL_ RCIOM SG_ 537 LiftAxle1AutoLiftRequest_ISig_4 3000;
BA_REL_ "GenSigTimeoutTime" BU_SG_REL_ RCIOM SG_ 537 LiftAxle1AutoLiftRequest_ISig_4 500;
BA_REL_ "GenSigFirstTimeoutTime" BU_SG_REL_ RCIOM SG_ 537 FerryFunctionRequest_ISig_4 3000;
BA_REL_ "GenSigTimeoutTime" BU_SG_REL_ RCIOM SG_ 537 FerryFunctionRequest_ISig_4 500;
BA_REL_ "GenSigFirstTimeoutTime" BU_SG_REL_ RCIOM SG_ 537 BBSystemKneelRequest 3000;
BA_REL_ "GenSigTimeoutTime" BU_SG_REL_ RCIOM SG_ 537 BBSystemKneelRequest 150;
BA_REL_ "GenSigFirstTimeoutTime" BU_SG_REL_ RCIOM SG_ 537 StopLevelChangeRequest_ISig_4 3000;
BA_REL_ "GenSigTimeoutTime" BU_SG_REL_ RCIOM SG_ 537 StopLevelChangeRequest_ISig_4 150;
BA_REL_ "GenSigFirstTimeoutTime" BU_SG_REL_ RCIOM SG_ 537 FirstAxleLowerPrioRequested_ISig 3000;
BA_REL_ "GenSigTimeoutTime" BU_SG_REL_ RCIOM SG_ 537 FirstAxleLowerPrioRequested_ISig 500;
BA_REL_ "GenSigFirstTimeoutTime" BU_SG_REL_ RCIOM SG_ 537 LiftAxle2AutoLiftRequest_ISig_4 3000;
BA_REL_ "GenSigTimeoutTime" BU_SG_REL_ RCIOM SG_ 537 LiftAxle2AutoLiftRequest_ISig_4 500;
BA_REL_ "GenSigFirstTimeoutTime" BU_SG_REL_ RCIOM SG_ 537 FerryFunctionSwitchChangeReq_ISi 3000;
BA_REL_ "GenSigTimeoutTime" BU_SG_REL_ RCIOM SG_ 537 FerryFunctionSwitchChangeReq_ISi 120;
BA_REL_ "GenSigFirstTimeoutTime" BU_SG_REL_ RCIOM SG_ 537 LevelStrokeRequest_ISig_4 3000;
BA_REL_ "GenSigTimeoutTime" BU_SG_REL_ RCIOM SG_ 537 LevelStrokeRequest_ISig_4 150;
BA_REL_ "GenSigFirstTimeoutTime" BU_SG_REL_ RCIOM SG_ 537 BBSystemProhibitControlRequest 3000;
BA_REL_ "GenSigTimeoutTime" BU_SG_REL_ RCIOM SG_ 537 BBSystemProhibitControlRequest 150;
BA_REL_ "GenSigFirstTimeoutTime" BU_SG_REL_ RCIOM SG_ 537 BBSystemAlternatLoadDistribReq 3000;
BA_REL_ "GenSigTimeoutTime" BU_SG_REL_ RCIOM SG_ 537 BBSystemAlternatLoadDistribReq 500;
BA_REL_ "GenSigFirstTimeoutTime" BU_SG_REL_ RCIOM SG_ 537 RideHeightStorageRequest_ISig_4 3000;
BA_REL_ "GenSigTimeoutTime" BU_SG_REL_ RCIOM SG_ 537 RideHeightStorageRequest_ISig_4 150;
BA_REL_ "GenSigFirstTimeoutTime" BU_SG_REL_ RCIOM SG_ 537 BBSystemSpeedDepDriveLevelReq 3000;
BA_REL_ "GenSigTimeoutTime" BU_SG_REL_ RCIOM SG_ 537 BBSystemSpeedDepDriveLevelReq 150;
BA_REL_ "GenSigFirstTimeoutTime" BU_SG_REL_ RCIOM SG_ 531 BackToDriveReq_ISig_4 3000;
BA_REL_ "GenSigTimeoutTime" BU_SG_REL_ RCIOM SG_ 531 BackToDriveReq_ISig_4 120;
BA_REL_ "GenSigFirstTimeoutTime" BU_SG_REL_ CCIOM SG_ 531 TrailerBrakePres_rqst 3000;
BA_REL_ "GenSigTimeoutTime" BU_SG_REL_ CCIOM SG_ 531 TrailerBrakePres_rqst 500;
BA_REL_ "GenSigFirstTimeoutTime" BU_SG_REL_ FCIOM SG_ 531 FogLight_Front_cmd 3000;
BA_REL_ "GenSigTimeoutTime" BU_SG_REL_ FCIOM SG_ 531 FogLight_Front_cmd 120;
BA_REL_ "GenSigFirstTimeoutTime" BU_SG_REL_ CCIOM SG_ 531 SplitBoxDifflockActvnDrvrRqst_IS 3000;
BA_REL_ "GenSigTimeoutTime" BU_SG_REL_ CCIOM SG_ 531 SplitBoxDifflockActvnDrvrRqst_IS 500;
BA_REL_ "GenSigFirstTimeoutTime" BU_SG_REL_ FCIOM SG_ 531 WS_Washing_cmd 3000;
BA_REL_ "GenSigTimeoutTime" BU_SG_REL_ FCIOM SG_ 531 WS_Washing_cmd 120;
BA_REL_ "GenSigFirstTimeoutTime" BU_SG_REL_ RCIOM SG_ 531 FogLight_Rear_cmd 3000;
BA_REL_ "GenSigTimeoutTime" BU_SG_REL_ RCIOM SG_ 531 FogLight_Rear_cmd 120;
BA_REL_ "GenSigFirstTimeoutTime" BU_SG_REL_ CCIOM SG_ 531 FogLight_Rear_cmd 3000;
BA_REL_ "GenSigTimeoutTime" BU_SG_REL_ CCIOM SG_ 531 FogLight_Rear_cmd 120;
BA_REL_ "GenSigFirstTimeoutTime" BU_SG_REL_ CCIOM SG_ 531 SplitBoxDifflockActvnDrvrRqst_UB 3000;
BA_REL_ "GenSigTimeoutTime" BU_SG_REL_ CCIOM SG_ 531 SplitBoxDifflockActvnDrvrRqst_UB 120;
BA_REL_ "GenSigFirstTimeoutTime" BU_SG_REL_ CCIOM SG_ 531 FrAxleDiffLockActvnDriverRqst 3000;
BA_REL_ "GenSigTimeoutTime" BU_SG_REL_ CCIOM SG_ 531 FrAxleDiffLockActvnDriverRqst 500;
BA_REL_ "GenSigFirstTimeoutTime" BU_SG_REL_ RCIOM SG_ 392 AcceleratorPedalPosition1_ISig_4 3000;
BA_REL_ "GenSigTimeoutTime" BU_SG_REL_ RCIOM SG_ 392 AcceleratorPedalPosition1_ISig_4 60;
BA_REL_ "GenSigFirstTimeoutTime" BU_SG_REL_ CCIOM SG_ 392 AcceleratorPedalPosition1_ISig_4 3000;
BA_REL_ "GenSigTimeoutTime" BU_SG_REL_ CCIOM SG_ 392 AcceleratorPedalPosition1_ISig_4 60;
BA_REL_ "GenSigFirstTimeoutTime" BU_SG_REL_ FCIOM SG_ 392 MainBeam_cmd 3000;
BA_REL_ "GenSigTimeoutTime" BU_SG_REL_ FCIOM SG_ 392 MainBeam_cmd 60;
BA_REL_ "GenSigFirstTimeoutTime" BU_SG_REL_ RCIOM SG_ 392 MainBeam_cmd 3000;
BA_REL_ "GenSigTimeoutTime" BU_SG_REL_ RCIOM SG_ 392 MainBeam_cmd 60;
BA_REL_ "GenSigFirstTimeoutTime" BU_SG_REL_ FCIOM SG_ 392 DippedBeam_cmd 3000;
BA_REL_ "GenSigTimeoutTime" BU_SG_REL_ FCIOM SG_ 392 DippedBeam_cmd 60;
BA_REL_ "GenSigFirstTimeoutTime" BU_SG_REL_ RCIOM SG_ 392 DippedBeam_cmd 3000;
BA_REL_ "GenSigTimeoutTime" BU_SG_REL_ RCIOM SG_ 392 DippedBeam_cmd 60;
BA_REL_ "GenSigFirstTimeoutTime" BU_SG_REL_ RCIOM SG_ 392 BrakePedalPosition_ISig_4 3000;
BA_REL_ "GenSigTimeoutTime" BU_SG_REL_ RCIOM SG_ 392 BrakePedalPosition_ISig_4 60;
BA_REL_ "GenSigFirstTimeoutTime" BU_SG_REL_ CCIOM SG_ 392 BrakePedalPosition_ISig_4 3000;
BA_REL_ "GenSigTimeoutTime" BU_SG_REL_ CCIOM SG_ 392 BrakePedalPosition_ISig_4 60;
BA_REL_ "GenSigFirstTimeoutTime" BU_SG_REL_ FCIOM SG_ 392 ExtraMainBeam_cmd 3000;
BA_REL_ "GenSigTimeoutTime" BU_SG_REL_ FCIOM SG_ 392 ExtraMainBeam_cmd 60;
BA_REL_ "GenSigFirstTimeoutTime" BU_SG_REL_ FCIOM SG_ 392 Hazard_rqst 3000;
BA_REL_ "GenSigTimeoutTime" BU_SG_REL_ FCIOM SG_ 392 Hazard_rqst 60;
BA_REL_ "GenSigFirstTimeoutTime" BU_SG_REL_ FCIOM SG_ 392 DirectionIndicatorLights_rqst_IS 3000;
BA_REL_ "GenSigTimeoutTime" BU_SG_REL_ FCIOM SG_ 392 DirectionIndicatorLights_rqst_IS 60;
BA_REL_ "GenSigFirstTimeoutTime" BU_SG_REL_ FCIOM SG_ 392 DRL_cmd_ISig_4 3000;
BA_REL_ "GenSigTimeoutTime" BU_SG_REL_ FCIOM SG_ 392 DRL_cmd_ISig_4 60;
BA_REL_ "GenSigFirstTimeoutTime" BU_SG_REL_ RCIOM SG_ 392 DRL_cmd_ISig_4 3000;
BA_REL_ "GenSigTimeoutTime" BU_SG_REL_ RCIOM SG_ 392 DRL_cmd_ISig_4 60;
BA_REL_ "GenSigFirstTimeoutTime" BU_SG_REL_ FCIOM SG_ 392 DirectionIndicatorLights_cmd_ISi 3000;
BA_REL_ "GenSigTimeoutTime" BU_SG_REL_ FCIOM SG_ 392 DirectionIndicatorLights_cmd_ISi 60;
BA_REL_ "GenSigFirstTimeoutTime" BU_SG_REL_ RCIOM SG_ 392 DirectionIndicatorLights_cmd_ISi 3000;
BA_REL_ "GenSigTimeoutTime" BU_SG_REL_ RCIOM SG_ 392 DirectionIndicatorLights_cmd_ISi 60;
BA_REL_ "GenSigFirstTimeoutTime" BU_SG_REL_ CCIOM SG_ 392 DirectionIndicatorLights_cmd_ISi 3000;
BA_REL_ "GenSigTimeoutTime" BU_SG_REL_ CCIOM SG_ 392 DirectionIndicatorLights_cmd_ISi 60;
BA_REL_ "GenSigFirstTimeoutTime" BU_SG_REL_ FCIOM SG_ 392 PositionLight_cmd_ISig_4 3000;
BA_REL_ "GenSigTimeoutTime" BU_SG_REL_ FCIOM SG_ 392 PositionLight_cmd_ISig_4 60;
BA_REL_ "GenSigFirstTimeoutTime" BU_SG_REL_ RCIOM SG_ 392 PositionLight_cmd_ISig_4 3000;
BA_REL_ "GenSigTimeoutTime" BU_SG_REL_ RCIOM SG_ 392 PositionLight_cmd_ISig_4 60;
BA_REL_ "GenSigFirstTimeoutTime" BU_SG_REL_ FCIOM SG_ 392 StaticCornerLight_cmd 3000;
BA_REL_ "GenSigTimeoutTime" BU_SG_REL_ FCIOM SG_ 392 StaticCornerLight_cmd 60;
BA_REL_ "GenSigFirstTimeoutTime" BU_SG_REL_ CCIOM SG_ 392 WorkingLightChassisOutp_cmd 3000;
BA_REL_ "GenSigTimeoutTime" BU_SG_REL_ CCIOM SG_ 392 WorkingLightChassisOutp_cmd 60;
BA_REL_ "GenSigFirstTimeoutTime" BU_SG_REL_ FCIOM SG_ 895 ApproachLight_FrontRqst 3000;
BA_REL_ "GenSigTimeoutTime" BU_SG_REL_ FCIOM SG_ 895 ApproachLight_FrontRqst 300;
BA_REL_ "GenSigFirstTimeoutTime" BU_SG_REL_ RCIOM SG_ 895 EASTagLiftAxleLoweringInhibit 12000;
BA_REL_ "GenSigTimeoutTime" BU_SG_REL_ RCIOM SG_ 895 EASTagLiftAxleLoweringInhibit 300;
BA_REL_ "GenSigFirstTimeoutTime" BU_SG_REL_ RCIOM SG_ 895 WheelBasedVehicleSpeed_ISig_4 12000;
BA_REL_ "GenSigTimeoutTime" BU_SG_REL_ RCIOM SG_ 895 WheelBasedVehicleSpeed_ISig_4 300;
BA_REL_ "GenSigFirstTimeoutTime" BU_SG_REL_ CCIOM SG_ 895 WheelBasedVehicleSpeed_ISig_4 3000;
BA_REL_ "GenSigTimeoutTime" BU_SG_REL_ CCIOM SG_ 895 WheelBasedVehicleSpeed_ISig_4 300;
BA_REL_ "GenSigFirstTimeoutTime" BU_SG_REL_ WSGW SG_ 895 WheelBasedVehicleSpeed_ISig_4 3000;
BA_REL_ "GenSigTimeoutTime" BU_SG_REL_ WSGW SG_ 895 WheelBasedVehicleSpeed_ISig_4 300;
BA_REL_ "GenSigFirstTimeoutTime" BU_SG_REL_ RCIOM SG_ 895 FrRrItrWhlDiffLckActvnDrvrReq_IS 12000;
BA_REL_ "GenSigTimeoutTime" BU_SG_REL_ RCIOM SG_ 895 FrRrItrWhlDiffLckActvnDrvrReq_IS 300;
BA_REL_ "GenSigFirstTimeoutTime" BU_SG_REL_ RCIOM SG_ 895 ApproachLight_RearandSideRqst 12000;
BA_REL_ "GenSigTimeoutTime" BU_SG_REL_ RCIOM SG_ 895 ApproachLight_RearandSideRqst 300;
BA_REL_ "GenSigFirstTimeoutTime" BU_SG_REL_ FCIOM SG_ 895 ApproachLight_HLAnimationcmd 3000;
BA_REL_ "GenSigTimeoutTime" BU_SG_REL_ FCIOM SG_ 895 ApproachLight_HLAnimationcmd 300;
BA_REL_ "GenSigFirstTimeoutTime" BU_SG_REL_ CCIOM SG_ 895 TransmissionSelectedGear_ISig_4 3000;
BA_REL_ "GenSigTimeoutTime" BU_SG_REL_ CCIOM SG_ 895 TransmissionSelectedGear_ISig_4 300;
BA_REL_ "GenSigFirstTimeoutTime" BU_SG_REL_ CCIOM SG_ 895 TransmissionCurrentGear_ISig_4 3000;
BA_REL_ "GenSigTimeoutTime" BU_SG_REL_ CCIOM SG_ 895 TransmissionCurrentGear_ISig_4 300;
BA_REL_ "GenSigFirstTimeoutTime" BU_SG_REL_ CCIOM SG_ 895 TransmEngineCrankEnable_ISig_4 3000;
BA_REL_ "GenSigTimeoutTime" BU_SG_REL_ CCIOM SG_ 895 TransmEngineCrankEnable_ISig_4 300;
BA_REL_ "GenSigFirstTimeoutTime" BU_SG_REL_ CCIOM SG_ 895 TransmEngineCrankEnable2_ISig_4 3000;
BA_REL_ "GenSigTimeoutTime" BU_SG_REL_ CCIOM SG_ 895 TransmEngineCrankEnable2_ISig_4 300;
BA_REL_ "GenSigFirstTimeoutTime" BU_SG_REL_ CCIOM SG_ 588 VehicleMode_ISig_4 3000;
BA_REL_ "GenSigTimeoutTime" BU_SG_REL_ CCIOM SG_ 588 VehicleMode_ISig_4 120;
BA_REL_ "GenSigFirstTimeoutTime" BU_SG_REL_ WSGW SG_ 588 VehicleMode_ISig_4 3000;
BA_REL_ "GenSigTimeoutTime" BU_SG_REL_ WSGW SG_ 588 VehicleMode_ISig_4 120;
BA_REL_ "GenSigFirstTimeoutTime" BU_SG_REL_ BPMU SG_ 588 VehicleMode_ISig_4 3000;
BA_REL_ "GenSigTimeoutTime" BU_SG_REL_ BPMU SG_ 588 VehicleMode_ISig_4 300;
BA_REL_ "GenSigFirstTimeoutTime" BU_SG_REL_ TBIOM SG_ 588 VehicleMode_ISig_4 3000;
BA_REL_ "GenSigTimeoutTime" BU_SG_REL_ TBIOM SG_ 588 VehicleMode_ISig_4 120;
BA_REL_ "GenSigFirstTimeoutTime" BU_SG_REL_ FCIOM SG_ 588 VehicleMode_ISig_4 3000;
BA_REL_ "GenSigTimeoutTime" BU_SG_REL_ FCIOM SG_ 588 VehicleMode_ISig_4 300;
BA_REL_ "GenSigFirstTimeoutTime" BU_SG_REL_ RCIOM SG_ 588 VehicleMode_ISig_4 3000;
BA_REL_ "GenSigTimeoutTime" BU_SG_REL_ RCIOM SG_ 588 VehicleMode_ISig_4 300;
BA_REL_ "GenSigFirstTimeoutTime" BU_SG_REL_ CCIOM SG_ 588 TransmissionDrivelineEngaged_ISi 3000;
BA_REL_ "GenSigTimeoutTime" BU_SG_REL_ CCIOM SG_ 588 TransmissionDrivelineEngaged_ISi 120;
BA_REL_ "GenSigFirstTimeoutTime" BU_SG_REL_ RCIOM SG_ 588 RevWarning_cmd 3000;
BA_REL_ "GenSigTimeoutTime" BU_SG_REL_ RCIOM SG_ 588 RevWarning_cmd 120;
BA_REL_ "GenSigFirstTimeoutTime" BU_SG_REL_ CCIOM SG_ 588 SecuredNeutralPosition_ISig_4 3000;
BA_REL_ "GenSigTimeoutTime" BU_SG_REL_ CCIOM SG_ 588 SecuredNeutralPosition_ISig_4 120;
BA_REL_ "GenSigFirstTimeoutTime" BU_SG_REL_ CCIOM SG_ 588 GearLeverPosition_ISig_4 3000;
BA_REL_ "GenSigTimeoutTime" BU_SG_REL_ CCIOM SG_ 588 GearLeverPosition_ISig_4 120;
BA_REL_ "GenSigFirstTimeoutTime" BU_SG_REL_ CCIOM SG_ 588 EngineActiveStatus_ISig_4 3000;
BA_REL_ "GenSigTimeoutTime" BU_SG_REL_ CCIOM SG_ 588 EngineActiveStatus_ISig_4 120;
BA_REL_ "GenSigFirstTimeoutTime" BU_SG_REL_ RCIOM SG_ 957 TrlrDirIndRightOutputStat_12V 3000;
BA_REL_ "GenSigTimeoutTime" BU_SG_REL_ RCIOM SG_ 957 TrlrDirIndRightOutputStat_12V 600;
BA_REL_ "GenSigFirstTimeoutTime" BU_SG_REL_ RCIOM SG_ 957 TrailerBrakeLightOutputStat12V 3000;
BA_REL_ "GenSigTimeoutTime" BU_SG_REL_ RCIOM SG_ 957 TrailerBrakeLightOutputStat12V 600;
BA_REL_ "GenSigFirstTimeoutTime" BU_SG_REL_ RCIOM SG_ 957 TrailerDirIndLightRequested12V 3000;
BA_REL_ "GenSigTimeoutTime" BU_SG_REL_ RCIOM SG_ 957 TrailerDirIndLightRequested12V 600;
BA_REL_ "GenSigFirstTimeoutTime" BU_SG_REL_ RCIOM SG_ 957 TD_BrakeLightsPulseRsp_12V 3000;
BA_REL_ "GenSigTimeoutTime" BU_SG_REL_ RCIOM SG_ 957 TD_BrakeLightsPulseRsp_12V 600;
BA_REL_ "GenSigFirstTimeoutTime" BU_SG_REL_ RCIOM SG_ 957 TD_DirInLgtPlsRsp_12V_Right 3000;
BA_REL_ "GenSigTimeoutTime" BU_SG_REL_ RCIOM SG_ 957 TD_DirInLgtPlsRsp_12V_Right 600;
BA_REL_ "GenSigFirstTimeoutTime" BU_SG_REL_ RCIOM SG_ 957 TrailerBrakeLightsRequested12V 3000;
BA_REL_ "GenSigTimeoutTime" BU_SG_REL_ RCIOM SG_ 957 TrailerBrakeLightsRequested12V 600;
BA_REL_ "GenSigFirstTimeoutTime" BU_SG_REL_ RCIOM SG_ 957 TrailerPos2OutputStat_12V 3000;
BA_REL_ "GenSigTimeoutTime" BU_SG_REL_ RCIOM SG_ 957 TrailerPos2OutputStat_12V 600;
BA_REL_ "GenSigFirstTimeoutTime" BU_SG_REL_ RCIOM SG_ 957 TD_PosLghtPlsRsp12V_Pos2 3000;
BA_REL_ "GenSigTimeoutTime" BU_SG_REL_ RCIOM SG_ 957 TD_PosLghtPlsRsp12V_Pos2 600;
BA_REL_ "GenSigFirstTimeoutTime" BU_SG_REL_ RCIOM SG_ 957 TrailerConnected_12VABSCurrent 3000;
BA_REL_ "GenSigTimeoutTime" BU_SG_REL_ RCIOM SG_ 957 TrailerConnected_12VABSCurrent 600;
BA_REL_ "GenSigFirstTimeoutTime" BU_SG_REL_ RCIOM SG_ 957 TrailerPosLightRequested12V 3000;
BA_REL_ "GenSigTimeoutTime" BU_SG_REL_ RCIOM SG_ 957 TrailerPosLightRequested12V 600;
BA_REL_ "GenSigFirstTimeoutTime" BU_SG_REL_ RCIOM SG_ 957 TD_PosLghtPlsRsp12V_Pos1 3000;
BA_REL_ "GenSigTimeoutTime" BU_SG_REL_ RCIOM SG_ 957 TD_PosLghtPlsRsp12V_Pos1 600;
BA_REL_ "GenSigFirstTimeoutTime" BU_SG_REL_ RCIOM SG_ 957 TrlrDirIndLeftOutputStat_12V 3000;
BA_REL_ "GenSigTimeoutTime" BU_SG_REL_ RCIOM SG_ 957 TrlrDirIndLeftOutputStat_12V 600;
BA_REL_ "GenSigFirstTimeoutTime" BU_SG_REL_ RCIOM SG_ 957 TrailerPos1OutputStat_12V 3000;
BA_REL_ "GenSigTimeoutTime" BU_SG_REL_ RCIOM SG_ 957 TrailerPos1OutputStat_12V 600;
BA_REL_ "GenSigFirstTimeoutTime" BU_SG_REL_ RCIOM SG_ 957 TD_DirInLgtPlsRsp_12V_Left 3000;
BA_REL_ "GenSigTimeoutTime" BU_SG_REL_ RCIOM SG_ 957 TD_DirInLgtPlsRsp_12V_Left 600;
BA_REL_ "GenSigFirstTimeoutTime" BU_SG_REL_ VCM SG_ 958 TD_LghtPlsReqBrk12V_Status 3000;
BA_REL_ "GenSigTimeoutTime" BU_SG_REL_ VCM SG_ 958 TD_LghtPlsReqBrk12V_Status 600;
BA_REL_ "GenSigFirstTimeoutTime" BU_SG_REL_ VCM SG_ 958 TD_LghtPlsReqDir12V_Right 3000;
BA_REL_ "GenSigTimeoutTime" BU_SG_REL_ VCM SG_ 958 TD_LghtPlsReqDir12V_Right 600;
BA_REL_ "GenSigFirstTimeoutTime" BU_SG_REL_ VCM SG_ 958 TD_LghtPlsReqDir12V_Status 3000;
BA_REL_ "GenSigTimeoutTime" BU_SG_REL_ VCM SG_ 958 TD_LghtPlsReqDir12V_Status 600;
BA_REL_ "GenSigFirstTimeoutTime" BU_SG_REL_ VCM SG_ 958 TD_LightsResetReq_12V 3000;
BA_REL_ "GenSigTimeoutTime" BU_SG_REL_ VCM SG_ 958 TD_LightsResetReq_12V 600;
BA_REL_ "GenSigFirstTimeoutTime" BU_SG_REL_ VCM SG_ 958 TD_LghtPlsReqPos12V_Status 3000;
BA_REL_ "GenSigTimeoutTime" BU_SG_REL_ VCM SG_ 958 TD_LghtPlsReqPos12V_Status 600;
BA_REL_ "GenSigFirstTimeoutTime" BU_SG_REL_ VCM SG_ 958 TD_LghtPlsReqBrk12V_Brake 3000;
BA_REL_ "GenSigTimeoutTime" BU_SG_REL_ VCM SG_ 958 TD_LghtPlsReqBrk12V_Brake 600;
BA_REL_ "GenSigFirstTimeoutTime" BU_SG_REL_ VCM SG_ 958 TrailerConnectedType 3000;
BA_REL_ "GenSigTimeoutTime" BU_SG_REL_ VCM SG_ 958 TrailerConnectedType 600;
BA_REL_ "GenSigFirstTimeoutTime" BU_SG_REL_ CCIOM SG_ 958 TrailerConnectedType 3000;
BA_REL_ "GenSigTimeoutTime" BU_SG_REL_ CCIOM SG_ 958 TrailerConnectedType 600;
BA_REL_ "GenSigFirstTimeoutTime" BU_SG_REL_ VCM SG_ 958 ECSManStandbyStatus_ISig_4 3000;
BA_REL_ "GenSigTimeoutTime" BU_SG_REL_ VCM SG_ 958 ECSManStandbyStatus_ISig_4 600;
BA_REL_ "GenSigFirstTimeoutTime" BU_SG_REL_ VCM SG_ 958 TrailerLightsConnected_12V 3000;
BA_REL_ "GenSigTimeoutTime" BU_SG_REL_ VCM SG_ 958 TrailerLightsConnected_12V 600;
BA_REL_ "GenSigFirstTimeoutTime" BU_SG_REL_ VCM SG_ 958 TD_LghtPlsReqDir12V_Left 3000;
BA_REL_ "GenSigTimeoutTime" BU_SG_REL_ VCM SG_ 958 TD_LghtPlsReqDir12V_Left 600;
BA_REL_ "GenSigFirstTimeoutTime" BU_SG_REL_ VCM SG_ 958 TD_LghtPlsReqPos12V_Pos2 3000;
BA_REL_ "GenSigTimeoutTime" BU_SG_REL_ VCM SG_ 958 TD_LghtPlsReqPos12V_Pos2 600;
BA_REL_ "GenSigFirstTimeoutTime" BU_SG_REL_ VCM SG_ 958 TD_LghtPlsReqPos12V_Pos1 3000;
BA_REL_ "GenSigTimeoutTime" BU_SG_REL_ VCM SG_ 958 TD_LghtPlsReqPos12V_Pos1 600;
BA_REL_ "GenSigFirstTimeoutTime" BU_SG_REL_ VCM SG_ 958 ECSPreconForSWDL_NegStatInfo 3000;
BA_REL_ "GenSigTimeoutTime" BU_SG_REL_ VCM SG_ 958 ECSPreconForSWDL_NegStatInfo 600;
BA_REL_ "GenSigFirstTimeoutTime" BU_SG_REL_ VCM SG_ 958 ECSPreconForSWDL_Status 3000;
BA_REL_ "GenSigTimeoutTime" BU_SG_REL_ VCM SG_ 958 ECSPreconForSWDL_Status 600;
BA_REL_ "GenSigFirstTimeoutTime" BU_SG_REL_ VCM SG_ 1517 RearDriveAxle2Temperature_ISig_4 24000;
BA_REL_ "GenSigTimeoutTime" BU_SG_REL_ VCM SG_ 1517 RearDriveAxle2Temperature_ISig_4 6000;
BA_REL_ "GenSigFirstTimeoutTime" BU_SG_REL_ VCM SG_ 1517 RearDriveAxle1Temperature_ISig_4 24000;
BA_REL_ "GenSigTimeoutTime" BU_SG_REL_ VCM SG_ 1517 RearDriveAxle1Temperature_ISig_4 6000;
BA_REL_ "GenSigFirstTimeoutTime" BU_SG_REL_ VCM SG_ 1517 RearDriveAxle3Temperature_ISig_4 24000;
BA_REL_ "GenSigTimeoutTime" BU_SG_REL_ VCM SG_ 1517 RearDriveAxle3Temperature_ISig_4 6000;
BA_REL_ "GenSigFirstTimeoutTime" BU_SG_REL_ VCM SG_ 676 RearAxle3DiffLock_stat_ISig_4 3000;
BA_REL_ "GenSigTimeoutTime" BU_SG_REL_ VCM SG_ 676 RearAxle3DiffLock_stat_ISig_4 500;
BA_REL_ "GenSigFirstTimeoutTime" BU_SG_REL_ VCM SG_ 676 LeftBrakeAndDirInd_cmd 3000;
BA_REL_ "GenSigTimeoutTime" BU_SG_REL_ VCM SG_ 676 LeftBrakeAndDirInd_cmd 120;
BA_REL_ "GenSigFirstTimeoutTime" BU_SG_REL_ VCM SG_ 676 RightBrakeAndDirInd_cmd 3000;
BA_REL_ "GenSigTimeoutTime" BU_SG_REL_ VCM SG_ 676 RightBrakeAndDirInd_cmd 120;
BA_REL_ "GenSigFirstTimeoutTime" BU_SG_REL_ VCM SG_ 1349 TertiaryDriveAxleLoad_ISig_4 6000;
BA_REL_ "GenSigTimeoutTime" BU_SG_REL_ VCM SG_ 1349 TertiaryDriveAxleLoad_ISig_4 1500;
BA_REL_ "GenSigFirstTimeoutTime" BU_SG_REL_ VCM SG_ 1349 LastDriveAxleBellowPressure_ISig 6000;
BA_REL_ "GenSigTimeoutTime" BU_SG_REL_ VCM SG_ 1349 LastDriveAxleBellowPressure_ISig 1500;
BA_REL_ "GenSigFirstTimeoutTime" BU_SG_REL_ VCM SG_ 1349 SuspensionSpeedLimitRequest 6000;
BA_REL_ "GenSigTimeoutTime" BU_SG_REL_ VCM SG_ 1349 SuspensionSpeedLimitRequest 1500;
BA_REL_ "GenSigFirstTimeoutTime" BU_SG_REL_ VCM SG_ 1349 RearAxleGroupLoad 6000;
BA_REL_ "GenSigTimeoutTime" BU_SG_REL_ VCM SG_ 1349 RearAxleGroupLoad 1500;
BA_REL_ "GenSigFirstTimeoutTime" BU_SG_REL_ VCM SG_ 951 DumpSwitchChangeAck_ISig_4 3000;
BA_REL_ "GenSigTimeoutTime" BU_SG_REL_ VCM SG_ 951 DumpSwitchChangeAck_ISig_4 300;
BA_REL_ "GenSigFirstTimeoutTime" BU_SG_REL_ VCM SG_ 951 HeadlightAngleAuto_rqst 3000;
BA_REL_ "GenSigTimeoutTime" BU_SG_REL_ VCM SG_ 951 HeadlightAngleAuto_rqst 300;
BA_REL_ "GenSigFirstTimeoutTime" BU_SG_REL_ VCM SG_ 951 RelativeLevelRearAxleLeftRaw 3000;
BA_REL_ "GenSigTimeoutTime" BU_SG_REL_ VCM SG_ 951 RelativeLevelRearAxleLeftRaw 300;
BA_REL_ "GenSigFirstTimeoutTime" BU_SG_REL_ VCM SG_ 951 FrontDumpFunctionCmd 3000;
BA_REL_ "GenSigTimeoutTime" BU_SG_REL_ VCM SG_ 951 FrontDumpFunctionCmd 300;
BA_REL_ "GenSigFirstTimeoutTime" BU_SG_REL_ CCIOM SG_ 951 FrontDumpFunctionCmd 3000;
BA_REL_ "GenSigTimeoutTime" BU_SG_REL_ CCIOM SG_ 951 FrontDumpFunctionCmd 300;
BA_REL_ "GenSigFirstTimeoutTime" BU_SG_REL_ VCM SG_ 951 RelativeLevelRearAxleRightRaw 3000;
BA_REL_ "GenSigTimeoutTime" BU_SG_REL_ VCM SG_ 951 RelativeLevelRearAxleRightRaw 300;
BA_REL_ "GenSigFirstTimeoutTime" BU_SG_REL_ VCM SG_ 1344 TagAxleLoad_ISig_4 6000;
BA_REL_ "GenSigTimeoutTime" BU_SG_REL_ VCM SG_ 1344 TagAxleLoad_ISig_4 1500;
BA_REL_ "GenSigFirstTimeoutTime" BU_SG_REL_ VCM SG_ 1344 MegaValveUpdateCounter 6000;
BA_REL_ "GenSigTimeoutTime" BU_SG_REL_ VCM SG_ 1344 MegaValveUpdateCounter 1500;
BA_REL_ "GenSigFirstTimeoutTime" BU_SG_REL_ VCM SG_ 1344 RegenInhibitVehicleHeight_ISig_4 6000;
BA_REL_ "GenSigTimeoutTime" BU_SG_REL_ VCM SG_ 1344 RegenInhibitVehicleHeight_ISig_4 1500;
BA_REL_ "GenSigFirstTimeoutTime" BU_SG_REL_ VCM SG_ 1344 RearLeftRoadVibrationIndex 6000;
BA_REL_ "GenSigTimeoutTime" BU_SG_REL_ VCM SG_ 1344 RearLeftRoadVibrationIndex 1500;
BA_REL_ "GenSigFirstTimeoutTime" BU_SG_REL_ VCM SG_ 1344 SavedHeightControlMode_ISig_4 6000;
BA_REL_ "GenSigTimeoutTime" BU_SG_REL_ VCM SG_ 1344 SavedHeightControlMode_ISig_4 1500;
BA_REL_ "GenSigFirstTimeoutTime" BU_SG_REL_ VCM SG_ 1344 PusherAxleLoad_ISig_4 6000;
BA_REL_ "GenSigTimeoutTime" BU_SG_REL_ VCM SG_ 1344 PusherAxleLoad_ISig_4 1500;
BA_REL_ "GenSigFirstTimeoutTime" BU_SG_REL_ VCM SG_ 1343 TrailerDirIndLeftOutputStat_ISig 6000;
BA_REL_ "GenSigTimeoutTime" BU_SG_REL_ VCM SG_ 1343 TrailerDirIndLeftOutputStat_ISig 1500;
BA_REL_ "GenSigFirstTimeoutTime" BU_SG_REL_ VCM SG_ 1343 TrailerBrakeLightOutputStat_ISig 6000;
BA_REL_ "GenSigTimeoutTime" BU_SG_REL_ VCM SG_ 1343 TrailerBrakeLightOutputStat_ISig 1500;
BA_REL_ "GenSigFirstTimeoutTime" BU_SG_REL_ VCM SG_ 1343 TrailerPosLightRightOutputStat_I 6000;
BA_REL_ "GenSigTimeoutTime" BU_SG_REL_ VCM SG_ 1343 TrailerPosLightRightOutputStat_I 1500;
BA_REL_ "GenSigFirstTimeoutTime" BU_SG_REL_ VCM SG_ 1343 TrailerPosLightLeftOutputStat_IS 6000;
BA_REL_ "GenSigTimeoutTime" BU_SG_REL_ VCM SG_ 1343 TrailerPosLightLeftOutputStat_IS 1500;
BA_REL_ "GenSigFirstTimeoutTime" BU_SG_REL_ VCM SG_ 1343 LoadDistributionSelected2_ISig_4 6000;
BA_REL_ "GenSigTimeoutTime" BU_SG_REL_ VCM SG_ 1343 LoadDistributionSelected2_ISig_4 1500;
BA_REL_ "GenSigFirstTimeoutTime" BU_SG_REL_ VCM SG_ 1343 DriveAxleLoad_ISig_4 6000;
BA_REL_ "GenSigTimeoutTime" BU_SG_REL_ VCM SG_ 1343 DriveAxleLoad_ISig_4 1500;
BA_REL_ "GenSigFirstTimeoutTime" BU_SG_REL_ VCM SG_ 1343 TrailerDirIndRightOutputStat_ISi 6000;
BA_REL_ "GenSigTimeoutTime" BU_SG_REL_ VCM SG_ 1343 TrailerDirIndRightOutputStat_ISi 1500;
BA_REL_ "GenSigFirstTimeoutTime" BU_SG_REL_ VCM SG_ 1343 ExtECSPressureUpdateAck 6000;
BA_REL_ "GenSigTimeoutTime" BU_SG_REL_ VCM SG_ 1343 ExtECSPressureUpdateAck 1500;
BA_REL_ "GenSigFirstTimeoutTime" BU_SG_REL_ VCM SG_ 1343 SecondaryDriveAxleLoad_ISig_4 6000;
BA_REL_ "GenSigTimeoutTime" BU_SG_REL_ VCM SG_ 1343 SecondaryDriveAxleLoad_ISig_4 1500;
BA_REL_ "GenSigFirstTimeoutTime" BU_SG_REL_ VCM SG_ 825 RevLightLamp_stat_ISig_4 3000;
BA_REL_ "GenSigTimeoutTime" BU_SG_REL_ VCM SG_ 825 RevLightLamp_stat_ISig_4 180;
BA_REL_ "GenSigFirstTimeoutTime" BU_SG_REL_ VCM SG_ 825 FirstAxleLowerPrioSelected_ISig_ 3000;
BA_REL_ "GenSigTimeoutTime" BU_SG_REL_ VCM SG_ 825 FirstAxleLowerPrioSelected_ISig_ 180;
BA_REL_ "GenSigFirstTimeoutTime" BU_SG_REL_ VCM SG_ 825 FrontParkBrakeOverrideInd_ISig_4 3000;
BA_REL_ "GenSigTimeoutTime" BU_SG_REL_ VCM SG_ 825 FrontParkBrakeOverrideInd_ISig_4 180;
BA_REL_ "GenSigFirstTimeoutTime" BU_SG_REL_ VCM SG_ 825 ECSLimpHomeNotification_ISig_4 3000;
BA_REL_ "GenSigTimeoutTime" BU_SG_REL_ VCM SG_ 825 ECSLimpHomeNotification_ISig_4 180;
BA_REL_ "GenSigFirstTimeoutTime" BU_SG_REL_ VCM SG_ 825 ECSValveActivationAllowed 3000;
BA_REL_ "GenSigTimeoutTime" BU_SG_REL_ VCM SG_ 825 ECSValveActivationAllowed 180;
BA_REL_ "GenSigFirstTimeoutTime" BU_SG_REL_ CCIOM SG_ 825 ECSValveActivationAllowed 3000;
BA_REL_ "GenSigTimeoutTime" BU_SG_REL_ CCIOM SG_ 825 ECSValveActivationAllowed 180;
BA_REL_ "GenSigFirstTimeoutTime" BU_SG_REL_ VCM SG_ 825 UnevenLoadWarning_ISig_4 3000;
BA_REL_ "GenSigTimeoutTime" BU_SG_REL_ VCM SG_ 825 UnevenLoadWarning_ISig_4 180;
BA_REL_ "GenSigFirstTimeoutTime" BU_SG_REL_ VCM SG_ 825 RampLevelRequestACK_ISig_4 3000;
BA_REL_ "GenSigTimeoutTime" BU_SG_REL_ VCM SG_ 825 RampLevelRequestACK_ISig_4 180;
BA_REL_ "GenSigFirstTimeoutTime" BU_SG_REL_ VCM SG_ 825 LoadDistributionSelected_ISig_4 3000;
BA_REL_ "GenSigTimeoutTime" BU_SG_REL_ VCM SG_ 825 LoadDistributionSelected_ISig_4 180;
BA_REL_ "GenSigFirstTimeoutTime" BU_SG_REL_ VCM SG_ 825 TrailerABSStatus_ISig_4 3000;
BA_REL_ "GenSigTimeoutTime" BU_SG_REL_ VCM SG_ 825 TrailerABSStatus_ISig_4 180;
BA_REL_ "GenSigFirstTimeoutTime" BU_SG_REL_ VCM SG_ 825 LoadDistributionALDChangeACK_ISi 3000;
BA_REL_ "GenSigTimeoutTime" BU_SG_REL_ VCM SG_ 825 LoadDistributionALDChangeACK_ISi 180;
BA_REL_ "GenSigFirstTimeoutTime" BU_SG_REL_ VCM SG_ 825 FogLightRearLamp_stat_ISig_4 3000;
BA_REL_ "GenSigTimeoutTime" BU_SG_REL_ VCM SG_ 825 FogLightRearLamp_stat_ISig_4 180;
BA_REL_ "GenSigFirstTimeoutTime" BU_SG_REL_ VCM SG_ 825 PositionLightRearLamp_stat_ISig_ 3000;
BA_REL_ "GenSigTimeoutTime" BU_SG_REL_ VCM SG_ 825 PositionLightRearLamp_stat_ISig_ 180;
BA_REL_ "GenSigFirstTimeoutTime" BU_SG_REL_ VCM SG_ 825 FerryFunctionSwitchChangeACK_ISi 3000;
BA_REL_ "GenSigTimeoutTime" BU_SG_REL_ VCM SG_ 825 FerryFunctionSwitchChangeACK_ISi 180;
BA_REL_ "GenSigFirstTimeoutTime" BU_SG_REL_ VCM SG_ 825 LiftAxle1AutoLiftSelected_ISig_4 3000;
BA_REL_ "GenSigTimeoutTime" BU_SG_REL_ VCM SG_ 825 LiftAxle1AutoLiftSelected_ISig_4 180;
BA_REL_ "GenSigFirstTimeoutTime" BU_SG_REL_ VCM SG_ 825 BrakeLightLamp_stat_ISig_4 3000;
BA_REL_ "GenSigTimeoutTime" BU_SG_REL_ VCM SG_ 825 BrakeLightLamp_stat_ISig_4 180;
BA_REL_ "GenSigFirstTimeoutTime" BU_SG_REL_ VCM SG_ 825 LiftAxle2AutoLiftSelected_ISig_4 3000;
BA_REL_ "GenSigTimeoutTime" BU_SG_REL_ VCM SG_ 825 LiftAxle2AutoLiftSelected_ISig_4 180;
BA_REL_ "GenSigFirstTimeoutTime" BU_SG_REL_ VCM SG_ 825 StartupProhibitStatus_ISig_4 3000;
BA_REL_ "GenSigTimeoutTime" BU_SG_REL_ VCM SG_ 825 StartupProhibitStatus_ISig_4 180;
BA_REL_ "GenSigFirstTimeoutTime" BU_SG_REL_ VCM SG_ 825 LiftAxle1LowerACK_ISig_4 3000;
BA_REL_ "GenSigTimeoutTime" BU_SG_REL_ VCM SG_ 825 LiftAxle1LowerACK_ISig_4 180;
BA_REL_ "GenSigFirstTimeoutTime" BU_SG_REL_ VCM SG_ 825 TrailerDirInd_status 3000;
BA_REL_ "GenSigTimeoutTime" BU_SG_REL_ VCM SG_ 825 TrailerDirInd_status 180;
BA_REL_ "GenSigFirstTimeoutTime" BU_SG_REL_ VCM SG_ 825 DriveLevelPosUserInteraction_ISi 3000;
BA_REL_ "GenSigTimeoutTime" BU_SG_REL_ VCM SG_ 825 DriveLevelPosUserInteraction_ISi 180;
BA_REL_ "GenSigFirstTimeoutTime" BU_SG_REL_ VCM SG_ 948 FrontEndPositionStatus 3000;
BA_REL_ "GenSigTimeoutTime" BU_SG_REL_ VCM SG_ 948 FrontEndPositionStatus 300;
BA_REL_ "GenSigFirstTimeoutTime" BU_SG_REL_ VCM SG_ 948 DirIndRearLamp_Stat_ISig_4 3000;
BA_REL_ "GenSigTimeoutTime" BU_SG_REL_ VCM SG_ 948 DirIndRearLamp_Stat_ISig_4 500;
BA_REL_ "GenSigFirstTimeoutTime" BU_SG_REL_ VCM SG_ 948 FrontAxleInBumperRange_ISig_4 3000;
BA_REL_ "GenSigTimeoutTime" BU_SG_REL_ VCM SG_ 948 FrontAxleInBumperRange_ISig_4 500;
BA_REL_ "GenSigFirstTimeoutTime" BU_SG_REL_ VCM SG_ 948 FrontRollAngleRef 3000;
BA_REL_ "GenSigTimeoutTime" BU_SG_REL_ VCM SG_ 948 FrontRollAngleRef 300;
BA_REL_ "GenSigFirstTimeoutTime" BU_SG_REL_ CCIOM SG_ 948 FrontRollAngleRef 3000;
BA_REL_ "GenSigTimeoutTime" BU_SG_REL_ CCIOM SG_ 948 FrontRollAngleRef 300;
BA_REL_ "GenSigFirstTimeoutTime" BU_SG_REL_ CCIOM SG_ 948 FrontSideKneelingAngleRef 3000;
BA_REL_ "GenSigTimeoutTime" BU_SG_REL_ CCIOM SG_ 948 FrontSideKneelingAngleRef 300;
BA_REL_ "GenSigFirstTimeoutTime" BU_SG_REL_ VCM SG_ 948 FrontSideKneelingAngleRef 3000;
BA_REL_ "GenSigTimeoutTime" BU_SG_REL_ VCM SG_ 948 FrontSideKneelingAngleRef 300;
BA_REL_ "GenSigFirstTimeoutTime" BU_SG_REL_ VCM SG_ 948 LoadDistributionRequestedACK_ISi 3000;
BA_REL_ "GenSigTimeoutTime" BU_SG_REL_ VCM SG_ 948 LoadDistributionRequestedACK_ISi 300;
BA_REL_ "GenSigFirstTimeoutTime" BU_SG_REL_ VCM SG_ 948 TotalFrontBellowTorqueRef 3000;
BA_REL_ "GenSigTimeoutTime" BU_SG_REL_ VCM SG_ 948 TotalFrontBellowTorqueRef 300;
BA_REL_ "GenSigFirstTimeoutTime" BU_SG_REL_ CCIOM SG_ 948 TotalFrontBellowTorqueRef 3000;
BA_REL_ "GenSigTimeoutTime" BU_SG_REL_ CCIOM SG_ 948 TotalFrontBellowTorqueRef 300;
BA_REL_ "GenSigFirstTimeoutTime" BU_SG_REL_ VCM SG_ 948 Rear1ClutchStatus 3000;
BA_REL_ "GenSigTimeoutTime" BU_SG_REL_ VCM SG_ 948 Rear1ClutchStatus 500;
BA_REL_ "GenSigFirstTimeoutTime" BU_SG_REL_ VCM SG_ 947 FPBRMMIStat_FPBRChangeAck_ISig_4 3000;
BA_REL_ "GenSigTimeoutTime" BU_SG_REL_ VCM SG_ 947 FPBRMMIStat_FPBRChangeAck_ISig_4 300;
BA_REL_ "GenSigFirstTimeoutTime" BU_SG_REL_ VCM SG_ 947 RelativeLevelRearAxleRight_ISig_ 3000;
BA_REL_ "GenSigTimeoutTime" BU_SG_REL_ VCM SG_ 947 RelativeLevelRearAxleRight_ISig_ 300;
BA_REL_ "GenSigFirstTimeoutTime" BU_SG_REL_ VCM SG_ 947 FPBRMMIStat_FPBRStatusInd_ISig_4 3000;
BA_REL_ "GenSigTimeoutTime" BU_SG_REL_ VCM SG_ 947 FPBRMMIStat_FPBRStatusInd_ISig_4 300;
BA_REL_ "GenSigFirstTimeoutTime" BU_SG_REL_ VCM SG_ 947 LiftAxle1LiftAllowed_Stat 3000;
BA_REL_ "GenSigTimeoutTime" BU_SG_REL_ VCM SG_ 947 LiftAxle1LiftAllowed_Stat 300;
BA_REL_ "GenSigFirstTimeoutTime" BU_SG_REL_ VCM SG_ 947 FrontLevRefCtrl_ShortPushCnt 3000;
BA_REL_ "GenSigTimeoutTime" BU_SG_REL_ VCM SG_ 947 FrontLevRefCtrl_ShortPushCnt 300;
BA_REL_ "GenSigFirstTimeoutTime" BU_SG_REL_ CCIOM SG_ 947 FrontLevRefCtrl_ShortPushCnt 3000;
BA_REL_ "GenSigTimeoutTime" BU_SG_REL_ CCIOM SG_ 947 FrontLevRefCtrl_ShortPushCnt 300;
BA_REL_ "GenSigFirstTimeoutTime" BU_SG_REL_ CCIOM SG_ 947 FrontLevRefCtrl_LevelRef 3000;
BA_REL_ "GenSigTimeoutTime" BU_SG_REL_ CCIOM SG_ 947 FrontLevRefCtrl_LevelRef 300;
BA_REL_ "GenSigFirstTimeoutTime" BU_SG_REL_ VCM SG_ 947 FrontLevRefCtrl_LevelRef 3000;
BA_REL_ "GenSigTimeoutTime" BU_SG_REL_ VCM SG_ 947 FrontLevRefCtrl_LevelRef 300;
BA_REL_ "GenSigFirstTimeoutTime" BU_SG_REL_ VCM SG_ 947 RelativeLevelRearAxleLeft_ISig_4 3000;
BA_REL_ "GenSigTimeoutTime" BU_SG_REL_ VCM SG_ 947 RelativeLevelRearAxleLeft_ISig_4 300;
BA_REL_ "GenSigFirstTimeoutTime" BU_SG_REL_ VCM SG_ 530 AirDumpStatus_ISig_4 3000;
BA_REL_ "GenSigTimeoutTime" BU_SG_REL_ VCM SG_ 530 AirDumpStatus_ISig_4 120;
BA_REL_ "GenSigFirstTimeoutTime" BU_SG_REL_ WSGW SG_ 530 RearAxle2DiffLock_stat_ISig_4 3000;
BA_REL_ "GenSigTimeoutTime" BU_SG_REL_ WSGW SG_ 530 RearAxle2DiffLock_stat_ISig_4 120;
BA_REL_ "GenSigFirstTimeoutTime" BU_SG_REL_ VCM SG_ 530 RearAxle2DiffLock_stat_ISig_4 3000;
BA_REL_ "GenSigTimeoutTime" BU_SG_REL_ VCM SG_ 530 RearAxle2DiffLock_stat_ISig_4 500;
BA_REL_ "GenSigFirstTimeoutTime" BU_SG_REL_ VCM SG_ 530 SWBrakeSwitch_ISig_4 3000;
BA_REL_ "GenSigTimeoutTime" BU_SG_REL_ VCM SG_ 530 SWBrakeSwitch_ISig_4 500;
BA_REL_ "GenSigFirstTimeoutTime" BU_SG_REL_ WSGW SG_ 530 RearAxle1DiffLock_stat_ISig_4 3000;
BA_REL_ "GenSigTimeoutTime" BU_SG_REL_ WSGW SG_ 530 RearAxle1DiffLock_stat_ISig_4 120;
BA_REL_ "GenSigFirstTimeoutTime" BU_SG_REL_ VCM SG_ 530 RearAxle1DiffLock_stat_ISig_4 3000;
BA_REL_ "GenSigTimeoutTime" BU_SG_REL_ VCM SG_ 530 RearAxle1DiffLock_stat_ISig_4 500;
BA_REL_ "GenSigFirstTimeoutTime" BU_SG_REL_ VCM SG_ 530 SupplyPressure_ISig_4 3000;
BA_REL_ "GenSigTimeoutTime" BU_SG_REL_ VCM SG_ 530 SupplyPressure_ISig_4 120;
BA_REL_ "GenSigFirstTimeoutTime" BU_SG_REL_ CCIOM SG_ 530 SupplyPressure_ISig_4 3000;
BA_REL_ "GenSigTimeoutTime" BU_SG_REL_ CCIOM SG_ 530 SupplyPressure_ISig_4 300;
BA_REL_ "GenSigFirstTimeoutTime" BU_SG_REL_ VCM SG_ 530 BackToDriveReqACK_ISig_4 3000;
BA_REL_ "GenSigTimeoutTime" BU_SG_REL_ VCM SG_ 530 BackToDriveReqACK_ISig_4 120;
BA_REL_ "GenSigFirstTimeoutTime" BU_SG_REL_ VCM SG_ 530 PitchAngleRef_ISig_4 3000;
BA_REL_ "GenSigTimeoutTime" BU_SG_REL_ VCM SG_ 530 PitchAngleRef_ISig_4 120;
BA_REL_ "GenSigFirstTimeoutTime" BU_SG_REL_ CCIOM SG_ 530 PitchAngleRef_ISig_4 3000;
BA_REL_ "GenSigTimeoutTime" BU_SG_REL_ CCIOM SG_ 530 PitchAngleRef_ISig_4 300;
BA_REL_ "GenSigFirstTimeoutTime" BU_SG_REL_ VCM SG_ 530 PitchAngle_ISig_4 3000;
BA_REL_ "GenSigTimeoutTime" BU_SG_REL_ VCM SG_ 530 PitchAngle_ISig_4 120;
BA_REL_ "GenSigFirstTimeoutTime" BU_SG_REL_ CCIOM SG_ 530 PitchAngle_ISig_4 3000;
BA_REL_ "GenSigTimeoutTime" BU_SG_REL_ CCIOM SG_ 530 PitchAngle_ISig_4 300;
BA_REL_ "GenSigFirstTimeoutTime" BU_SG_REL_ VCM SG_ 530 TrailerWithoutABS_ISig_4 3000;
BA_REL_ "GenSigTimeoutTime" BU_SG_REL_ VCM SG_ 530 TrailerWithoutABS_ISig_4 500;
BA_REL_ "GenSigFirstTimeoutTime" BU_SG_REL_ VCM SG_ 530 TrailerConnected_ISig_4 3000;
BA_REL_ "GenSigTimeoutTime" BU_SG_REL_ VCM SG_ 530 TrailerConnected_ISig_4 500;
BA_REL_ "GenSigFirstTimeoutTime" BU_SG_REL_ CCIOM SG_ 530 TrailerConnected_ISig_4 3000;
BA_REL_ "GenSigTimeoutTime" BU_SG_REL_ CCIOM SG_ 530 TrailerConnected_ISig_4 500;
BA_REL_ "GenSigFirstTimeoutTime" BU_SG_REL_ WSGW SG_ 530 TrailerConnected_ISig_4 3000;
BA_REL_ "GenSigTimeoutTime" BU_SG_REL_ WSGW SG_ 530 TrailerConnected_ISig_4 120;
BA_REL_ "GenSigFirstTimeoutTime" BU_SG_REL_ VCM SG_ 530 CentralRearDiffLock_stat_ISig_4 3000;
BA_REL_ "GenSigTimeoutTime" BU_SG_REL_ VCM SG_ 530 CentralRearDiffLock_stat_ISig_4 500;
BA_REL_ "GenSigFirstTimeoutTime" BU_SG_REL_ VCM SG_ 528 RollEndPositionStatus_ISig_4 3000;
BA_REL_ "GenSigTimeoutTime" BU_SG_REL_ VCM SG_ 528 RollEndPositionStatus_ISig_4 120;
BA_REL_ "GenSigFirstTimeoutTime" BU_SG_REL_ VCM SG_ 528 FrontFerryFunctionCmd_ISig_4 3000;
BA_REL_ "GenSigTimeoutTime" BU_SG_REL_ VCM SG_ 528 FrontFerryFunctionCmd_ISig_4 120;
BA_REL_ "GenSigFirstTimeoutTime" BU_SG_REL_ CCIOM SG_ 528 FrontFerryFunctionCmd_ISig_4 3000;
BA_REL_ "GenSigTimeoutTime" BU_SG_REL_ CCIOM SG_ 528 FrontFerryFunctionCmd_ISig_4 120;
BA_REL_ "GenSigFirstTimeoutTime" BU_SG_REL_ VCM SG_ 528 RideHeightFunctionStatus_ISig_4 3000;
BA_REL_ "GenSigTimeoutTime" BU_SG_REL_ VCM SG_ 528 RideHeightFunctionStatus_ISig_4 120;
BA_REL_ "GenSigFirstTimeoutTime" BU_SG_REL_ CCIOM SG_ 528 HeightControlMode_ISig_4 3000;
BA_REL_ "GenSigTimeoutTime" BU_SG_REL_ CCIOM SG_ 528 HeightControlMode_ISig_4 120;
BA_REL_ "GenSigFirstTimeoutTime" BU_SG_REL_ VCM SG_ 528 HeightControlMode_ISig_4 3000;
BA_REL_ "GenSigTimeoutTime" BU_SG_REL_ VCM SG_ 528 HeightControlMode_ISig_4 120;
BA_REL_ "GenSigFirstTimeoutTime" BU_SG_REL_ VCM SG_ 528 ECSShutdownCmd_ISig_4 3000;
BA_REL_ "GenSigTimeoutTime" BU_SG_REL_ VCM SG_ 528 ECSShutdownCmd_ISig_4 120;
BA_REL_ "GenSigFirstTimeoutTime" BU_SG_REL_ CCIOM SG_ 528 ECSShutdownCmd_ISig_4 3000;
BA_REL_ "GenSigTimeoutTime" BU_SG_REL_ CCIOM SG_ 528 ECSShutdownCmd_ISig_4 120;
BA_REL_ "GenSigFirstTimeoutTime" BU_SG_REL_ VCM SG_ 528 FerryFunctionStatus_ISig_4 3000;
BA_REL_ "GenSigTimeoutTime" BU_SG_REL_ VCM SG_ 528 FerryFunctionStatus_ISig_4 500;
BA_REL_ "GenSigFirstTimeoutTime" BU_SG_REL_ VCM SG_ 528 LevelControlInformation_ISig_4 3000;
BA_REL_ "GenSigTimeoutTime" BU_SG_REL_ VCM SG_ 528 LevelControlInformation_ISig_4 500;
BA_REL_ "GenSigFirstTimeoutTime" BU_SG_REL_ VCM SG_ 528 ChangeKneelACK_ISig_4 3000;
BA_REL_ "GenSigTimeoutTime" BU_SG_REL_ VCM SG_ 528 ChangeKneelACK_ISig_4 120;
BA_REL_ "GenSigFirstTimeoutTime" BU_SG_REL_ VCM SG_ 528 RearEndPositionStatus_ISig_4 3000;
BA_REL_ "GenSigTimeoutTime" BU_SG_REL_ VCM SG_ 528 RearEndPositionStatus_ISig_4 120;
BA_REL_ "GenSigFirstTimeoutTime" BU_SG_REL_ VCM SG_ 528 RampHeightOutsideTargetRange_ISi 3000;
BA_REL_ "GenSigTimeoutTime" BU_SG_REL_ VCM SG_ 528 RampHeightOutsideTargetRange_ISi 120;
BA_REL_ "GenSigFirstTimeoutTime" BU_SG_REL_ VCM SG_ 528 LoadDistributionFuncSelected_ISi 3000;
BA_REL_ "GenSigTimeoutTime" BU_SG_REL_ VCM SG_ 528 LoadDistributionFuncSelected_ISi 120;
BA_REL_ "GenSigFirstTimeoutTime" BU_SG_REL_ VCM SG_ 528 HeightAdjustmentAllowed_ISig_4 3000;
BA_REL_ "GenSigTimeoutTime" BU_SG_REL_ VCM SG_ 528 HeightAdjustmentAllowed_ISig_4 120;
BA_REL_ "GenSigFirstTimeoutTime" BU_SG_REL_ VCM SG_ 528 KneelingInformation_ISig_4 3000;
BA_REL_ "GenSigTimeoutTime" BU_SG_REL_ VCM SG_ 528 KneelingInformation_ISig_4 120;
BA_REL_ "GenSigFirstTimeoutTime" BU_SG_REL_ VCM SG_ 528 KneelingStatusHMI_ISig_4 3000;
BA_REL_ "GenSigTimeoutTime" BU_SG_REL_ VCM SG_ 528 KneelingStatusHMI_ISig_4 120;
BA_REL_ "GenSigFirstTimeoutTime" BU_SG_REL_ CCIOM SG_ 528 LiftAxle1PositionStatus_ISig_4 3000;
BA_REL_ "GenSigTimeoutTime" BU_SG_REL_ CCIOM SG_ 528 LiftAxle1PositionStatus_ISig_4 120;
BA_REL_ "GenSigFirstTimeoutTime" BU_SG_REL_ WSGW SG_ 528 LiftAxle1PositionStatus_ISig_4 3000;
BA_REL_ "GenSigTimeoutTime" BU_SG_REL_ WSGW SG_ 528 LiftAxle1PositionStatus_ISig_4 120;
BA_REL_ "GenSigFirstTimeoutTime" BU_SG_REL_ VCM SG_ 528 LiftAxle1PositionStatus_ISig_4 3000;
BA_REL_ "GenSigTimeoutTime" BU_SG_REL_ VCM SG_ 528 LiftAxle1PositionStatus_ISig_4 120;
BA_REL_ "GenSigFirstTimeoutTime" BU_SG_REL_ CCIOM SG_ 528 VehicleDynamicSuspProhibitStat_I 3000;
BA_REL_ "GenSigTimeoutTime" BU_SG_REL_ CCIOM SG_ 528 VehicleDynamicSuspProhibitStat_I 120;
BA_REL_ "GenSigFirstTimeoutTime" BU_SG_REL_ VCM SG_ 528 VehicleDynamicSuspProhibitStat_I 3000;
BA_REL_ "GenSigTimeoutTime" BU_SG_REL_ VCM SG_ 528 VehicleDynamicSuspProhibitStat_I 120;
BA_REL_ "GenSigFirstTimeoutTime" BU_SG_REL_ WSGW SG_ 528 LiftAxle2PositionStatus_ISig_4 3000;
BA_REL_ "GenSigTimeoutTime" BU_SG_REL_ WSGW SG_ 528 LiftAxle2PositionStatus_ISig_4 120;
BA_REL_ "GenSigFirstTimeoutTime" BU_SG_REL_ VCM SG_ 528 LiftAxle2PositionStatus_ISig_4 3000;
BA_REL_ "GenSigTimeoutTime" BU_SG_REL_ VCM SG_ 528 LiftAxle2PositionStatus_ISig_4 120;
BA_REL_ "GenSigFirstTimeoutTime" BU_SG_REL_ VCM SG_ 528 RideHeightStatus_ISig_4 3000;
BA_REL_ "GenSigTimeoutTime" BU_SG_REL_ VCM SG_ 528 RideHeightStatus_ISig_4 120;
BA_REL_ "GenSigFirstTimeoutTime" BU_SG_REL_ VCM SG_ 528 DirInd_Rear_Status_ISig_4 3000;
BA_REL_ "GenSigTimeoutTime" BU_SG_REL_ VCM SG_ 528 DirInd_Rear_Status_ISig_4 120;
VAL_ 945 EcoRollActiveStatus_ISig_4 3 "InactiveActive_NotAvailable" 2 "InactiveActive_Error" 1 "InactiveActive_Active" 0 "InactiveActive_Inactive" ;
VAL_ 928 RrRrItrWhlDiffLckActvnDrvrReq_IS 3 "DisengagedEngaged_NotAvailable" 2 "DisengagedEngaged_Error" 1 "DisengagedEngaged_Engaged" 0 "DisengagedEngaged_Disengaged" ;
VAL_ 928 LiftAxle1Request 15 "AxleLiftRequest_NotAvailable" 14 "AxleLiftRequest_Error" 13 "AxleLiftRequest_Spare7" 12 "AxleLiftRequest_Spare6" 11 "AxleLiftRequest_Spare5" 10 "AxleLiftRequest_Spare4" 9 "AxleLiftRequest_Spare3" 8 "AxleLiftRequest_Spare2" 7 "AxleLiftRequest_Spare1" 6 "AxleLiftRequest_LowerAxleFallbackCondition" 5 "AxleLiftRequest_LiftDenied" 4 "AxleLiftRequest_TransferLoadToLoweredAxle" 3 "AxleLiftRequest_LowerAxle" 2 "AxleLiftRequest_LiftAxle" 1 "AxleLiftRequest_PrepareLiftAxle" 0 "AxleLiftRequest_Idle" ;
VAL_ 928 Rear1ClutchRequest 3 "DisengageEngage_NotAvailable" 2 "DisengageEngage_Error" 1 "DisengageEngage_Engage" 0 "DisengageEngage_Disengage" ;
VAL_ 928 FrontWheelDifflockRequest_ISig_4 3 "DisengageEngage_NotAvailable" 2 "DisengageEngage_Error" 1 "DisengageEngage_Engage" 0 "DisengageEngage_Disengage" ;
VAL_ 537 LiftAxle2LiftPositionRequest_ISi 7 "LiftAxleLiftPositionRequest_NotAvailable" 6 "LiftAxleLiftPositionRequest_Error" 5 "LiftAxleLiftPositionRequest_Reserved_02" 4 "LiftAxleLiftPositionRequest_Reserved_01" 3 "LiftAxleLiftPositionRequest_Reserved" 2 "LiftAxleLiftPositionRequest_Up" 1 "LiftAxleLiftPositionRequest_Down" 0 "LiftAxleLiftPositionRequest_Idle" ;
VAL_ 537 LoadDistributionChangeRequest_IS 3 "LoadDistributionChangeRequest_NotAvailable" 2 "LoadDistributionChangeRequest_Error" 1 "LoadDistributionChangeRequest_ChangeLoadDistribution" 0 "LoadDistributionChangeRequest_Idle" ;
VAL_ 537 AltLoadDistribution_rqst_ISig_4 7 "AltLoadDistribution_rqst_NotAvailable" 6 "AltLoadDistribution_rqst_Error" 5 "AltLoadDistribution_rqst_Reserved_3" 4 "AltLoadDistribution_rqst_Reserved_2" 3 "AltLoadDistribution_rqst_Reserved_1" 2 "AltLoadDistribution_rqst_ALDOff" 1 "AltLoadDistribution_rqst_ALDOn" 0 "AltLoadDistribution_rqst_Idle" ;
VAL_ 537 LiftAxle1LiftPositionRequest_ISi 7 "LiftAxleLiftPositionRequest_NotAvailable" 6 "LiftAxleLiftPositionRequest_Error" 5 "LiftAxleLiftPositionRequest_Reserved_02" 4 "LiftAxleLiftPositionRequest_Reserved_01" 3 "LiftAxleLiftPositionRequest_Reserved" 2 "LiftAxleLiftPositionRequest_Up" 1 "LiftAxleLiftPositionRequest_Down" 0 "LiftAxleLiftPositionRequest_Idle" ;
VAL_ 537 RampLevelRequest_ISig_4 15 "RampLevelRequest_NotAvailable" 14 "RampLevelRequest_ErrorIndicator" 13 "RampLevelRequest_NotDefined_09" 12 "RampLevelRequest_NotDefined_08" 11 "RampLevelRequest_NotDefined_07" 10 "RampLevelRequest_NotDefined_06" 9 "RampLevelRequest_NotDefined_05" 8 "RampLevelRequest_NotDefined_04" 7 "RampLevelRequest_RampLevelM7" 6 "RampLevelRequest_RampLevelM6" 5 "RampLevelRequest_RampLevelM5" 4 "RampLevelRequest_RampLevelM4" 3 "RampLevelRequest_RampLevelM3" 2 "RampLevelRequest_RampLevelM2" 1 "RampLevelRequest_RampLevelM1" 0 "RampLevelRequest_TakeNoAction" ;
VAL_ 537 RampLevelStorageRequest_ISig_4 15 "RampLevelRequest_NotAvailable" 14 "RampLevelRequest_ErrorIndicator" 13 "RampLevelRequest_NotDefined_09" 12 "RampLevelRequest_NotDefined_08" 11 "RampLevelRequest_NotDefined_07" 10 "RampLevelRequest_NotDefined_06" 9 "RampLevelRequest_NotDefined_05" 8 "RampLevelRequest_NotDefined_04" 7 "RampLevelRequest_RampLevelM7" 6 "RampLevelRequest_RampLevelM6" 5 "RampLevelRequest_RampLevelM5" 4 "RampLevelRequest_RampLevelM4" 3 "RampLevelRequest_RampLevelM3" 2 "RampLevelRequest_RampLevelM2" 1 "RampLevelRequest_RampLevelM1" 0 "RampLevelRequest_TakeNoAction" ;
VAL_ 537 RideHeightFunctionRequest_ISig_4 15 "RideHeightFunction_NotAvailable" 14 "RideHeightFunction_ErrorIndicator" 13 "RideHeightFunction_NotDefined_05" 12 "RideHeightFunction_NotDefined_04" 11 "RideHeightFunction_NotDefined_03" 10 "RideHeightFunction_NotDefined_02" 9 "RideHeightFunction_NotDefined_01" 8 "RideHeightFunction_NotDefined" 7 "RideHeightFunction_AlternativeDrivePosition2" 6 "RideHeightFunction_AlternativeDrivePosition1" 5 "RideHeightFunction_LowDrivePosition" 4 "RideHeightFunction_HighDrivePosition" 3 "RideHeightFunction_SpeedDependentDrivePosition" 2 "RideHeightFunction_AlternativeDrivePosition" 1 "RideHeightFunction_StandardDrivePosition" 0 "RideHeightFunction_Inactive" ;
VAL_ 537 LiftAxle1AutoLiftRequest_ISig_4 3 "InactiveActive_NotAvailable" 2 "InactiveActive_Error" 1 "InactiveActive_Active" 0 "InactiveActive_Inactive" ;
VAL_ 537 FerryFunctionRequest_ISig_4 3 "Request_NotAvailable" 2 "Request_Error" 1 "Request_RequestActive" 0 "Request_NotRequested" ;
VAL_ 537 BBSystemKneelRequest 3 "Request_NotAvailable" 2 "Request_Error" 1 "Request_RequestActive" 0 "Request_NotRequested" ;
VAL_ 537 StopLevelChangeRequest_ISig_4 3 "Request_NotAvailable" 2 "Request_Error" 1 "Request_RequestActive" 0 "Request_NotRequested" ;
VAL_ 537 FirstAxleLowerPrioRequested_ISig 7 "FirstAxleLowerPrio_NotAvailable" 6 "FirstAxleLowerPrio_Error" 5 "FirstAxleLowerPrio_Reserved_03" 4 "FirstAxleLowerPrio_Reserved_02" 3 "FirstAxleLowerPrio_Reserved_01" 2 "FirstAxleLowerPrio_Reserved" 1 "FirstAxleLowerPrio_LowerPusher" 0 "FirstAxleLowerPrio_LowerTag" ;
VAL_ 537 LiftAxle2AutoLiftRequest_ISig_4 3 "InactiveActive_NotAvailable" 2 "InactiveActive_Error" 1 "InactiveActive_Active" 0 "InactiveActive_Inactive" ;
VAL_ 537 FerryFunctionSwitchChangeReq_ISi 3 "ChangeRequest2Bit_NotAvailable" 2 "ChangeRequest2Bit_Error" 1 "ChangeRequest2Bit_Change" 0 "ChangeRequest2Bit_TakeNoAction" ;
VAL_ 537 LevelStrokeRequest_ISig_4 3 "LevelStrokeRequest_NotAvailable" 2 "LevelStrokeRequest_ErrorIndicator" 1 "LevelStrokeRequest_DriveLevelControlStroke" 0 "LevelStrokeRequest_DockingLevelControlStroke" ;
VAL_ 537 BBSystemProhibitControlRequest 3 "Request_NotAvailable" 2 "Request_Error" 1 "Request_RequestActive" 0 "Request_NotRequested" ;
VAL_ 537 BBSystemAlternatLoadDistribReq 3 "InactiveActive_NotAvailable" 2 "InactiveActive_Error" 1 "InactiveActive_Active" 0 "InactiveActive_Inactive" ;
VAL_ 537 RideHeightStorageRequest_ISig_4 15 "RideHeightStorageRequest_NotAvailable" 14 "RideHeightStorageRequest_ErrorIndicator" 13 "RideHeightStorageRequest_NotDefined_06" 12 "RideHeightStorageRequest_NotDefined_05" 11 "RideHeightStorageRequest_NotDefined_04" 10 "RideHeightStorageRequest_NotDefined_03" 9 "RideHeightStorageRequest_NotDefined_02" 8 "RideHeightStorageRequest_NotDefined_01" 7 "RideHeightStorageRequest_NotDefined" 6 "RideHeightStorageRequest_ResetHighDrivePosition" 5 "RideHeightStorageRequest_ResetLowDrivePosition" 4 "RideHeightStorageRequest_StoreHighDrivePosition" 3 "RideHeightStorageRequest_StoreLowDrivePosition" 2 "RideHeightStorageRequest_StoreStandardUserDrivePosition" 1 "RideHeightStorageRequest_ResetToStoreFactoryDrivePosition" 0 "RideHeightStorageRequest_TakeNoAction" ;
VAL_ 537 BBSystemSpeedDepDriveLevelReq 3 "BBSystemSpeedDepDriveLevelReq_NotAvailable" 2 "BBSystemSpeedDepDriveLevelReq_ErrorIndicator" 1 "BBSystemSpeedDepDriveLevelReq_SpeedDependentDrivePosition" 0 "BBSystemSpeedDepDriveLevelReq_TakeNoAction" ;
VAL_ 531 BackToDriveReq_ISig_4 3 "Requested_NotAvailable" 2 "Requested_Error" 1 "BackToDriveReq_B2DRequested" 0 "BackToDriveReq_Idle" ;
VAL_ 531 FogLight_Front_cmd 3 "InactiveActive_NotAvailable" 2 "InactiveActive_Error" 1 "InactiveActive_Active" 0 "InactiveActive_Inactive" ;
VAL_ 531 SplitBoxDifflockActvnDrvrRqst_IS 3 "DisengageEngage_NotAvailable" 2 "DisengageEngage_Error" 1 "DisengageEngage_Engage" 0 "DisengageEngage_Disengage" ;
VAL_ 531 WS_Washing_cmd 3 "InactiveActive_NotAvailable" 2 "InactiveActive_Error" 1 "InactiveActive_Active" 0 "InactiveActive_Inactive" ;
VAL_ 531 FogLight_Rear_cmd 3 "InactiveActive_NotAvailable" 2 "InactiveActive_Error" 1 "InactiveActive_Active" 0 "InactiveActive_Inactive" ;
VAL_ 531 FrAxleDiffLockActvnDriverRqst 3 "DisengageEngage_NotAvailable" 2 "DisengageEngage_Error" 1 "DisengageEngage_Engage" 0 "DisengageEngage_Disengage" ;
VAL_ 392 MainBeam_cmd 7 "MainBeam_cmd_NotAvailable" 6 "MainBeam_cmd_SpareValue_03" 5 "MainBeam_cmd_SpareValue_02" 4 "MainBeam_cmd_SpareValue_01" 3 "MainBeam_cmd_SpareValue" 2 "MainBeam_cmd_MainBeamFlashOn" 1 "MainBeam_cmd_MainBeamOn" 0 "MainBeam_cmd_MainBeamOff" ;
VAL_ 392 DippedBeam_cmd 3 "InactiveActive_NotAvailable" 2 "InactiveActive_Error" 1 "InactiveActive_Active" 0 "InactiveActive_Inactive" ;
VAL_ 392 ExtraMainBeam_cmd 3 "InactiveActive_NotAvailable" 2 "InactiveActive_Error" 1 "InactiveActive_Active" 0 "InactiveActive_Inactive" ;
VAL_ 392 Hazard_rqst 3 "InactiveActive_NotAvailable" 2 "InactiveActive_Error" 1 "InactiveActive_Active" 0 "InactiveActive_Inactive" ;
VAL_ 392 DirectionIndicatorLights_rqst_IS 7 "DirectionIndicatorLights_rqst_NotAvailable" 6 "DirectionIndicatorLights_rqst_Error" 5 "DirectionIndicatorLights_rqst_SpareValue_02" 4 "DirectionIndicatorLights_rqst_SpareValue_01" 3 "DirectionIndicatorLights_rqst_SpareValue" 2 "DirectionIndicatorLights_rqst_RightDirectionIndicatorActive" 1 "DirectionIndicatorLights_rqst_LeftDirectionIndicatorActive" 0 "DirectionIndicatorLights_rqst_NotActive" ;
VAL_ 392 DRL_cmd_ISig_4 3 "InactiveActive_NotAvailable" 2 "InactiveActive_Error" 1 "InactiveActive_Active" 0 "InactiveActive_Inactive" ;
VAL_ 392 DirectionIndicatorLights_cmd_ISi 7 "DirectionIndicatorLights_cmd_NotAvailable" 6 "DirectionIndicatorLights_cmd_SpareValue_02" 5 "DirectionIndicatorLights_cmd_SpareValue_01" 4 "DirectionIndicatorLights_cmd_SpareValue" 3 "DirectionIndicatorLights_cmd_RightAndLeftActiveHazard" 2 "DirectionIndicatorLights_cmd_RightDirectionIndicatorActive" 1 "DirectionIndicatorLights_cmd_LeftDirectionIndicatorActive" 0 "DirectionIndicatorLights_cmd_NotActive" ;
VAL_ 392 PositionLight_cmd_ISig_4 3 "InactiveActive_NotAvailable" 2 "InactiveActive_Error" 1 "InactiveActive_Active" 0 "InactiveActive_Inactive" ;
VAL_ 392 StaticCornerLight_cmd 7 "StaticCornerLight_cmd_NotAvailable" 6 "StaticCornerLight_cmd_SpareValue_02" 5 "StaticCornerLight_cmd_SpareValue_01" 4 "StaticCornerLight_cmd_SpareValue" 3 "StaticCornerLight_cmd_LeftAndRightStaticCornerLightActive" 2 "StaticCornerLight_cmd_LeftStaticCornerLightActive" 1 "StaticCornerLight_cmd_RightStaticCornerLightActive" 0 "StaticCornerLight_cmd_Off" ;
VAL_ 392 WorkingLightChassisOutp_cmd 3 "OffOn_NotAvailable" 2 "OffOn_Error" 1 "OffOn_On" 0 "OffOn_Off" ;
VAL_ 895 ApproachLight_FrontRqst 3 "InactiveActive_NotAvailable" 2 "InactiveActive_Error" 1 "InactiveActive_Active" 0 "InactiveActive_Inactive" ;
VAL_ 895 EASTagLiftAxleLoweringInhibit 3 "InhibitStatus_NotAvailable" 2 "InhibitStatus_Reserved" 1 "InhibitStatus_Inhibited" 0 "InhibitStatus_NotInhibited" ;
VAL_ 895 FrRrItrWhlDiffLckActvnDrvrReq_IS 3 "DisengagedEngaged_NotAvailable" 2 "DisengagedEngaged_Error" 1 "DisengagedEngaged_Engaged" 0 "DisengagedEngaged_Disengaged" ;
VAL_ 895 ApproachLight_RearandSideRqst 3 "InactiveActive_NotAvailable" 2 "InactiveActive_Error" 1 "InactiveActive_Active" 0 "InactiveActive_Inactive" ;
VAL_ 895 ApproachLight_HLAnimationcmd 3 "InactiveActive_NotAvailable" 2 "InactiveActive_Error" 1 "InactiveActive_Active" 0 "InactiveActive_Inactive" ;
VAL_ 895 TransmEngineCrankEnable_ISig_4 3 "DisableEnable_NotAvailable" 2 "DisableEnable_Error" 1 "DisableEnable_Enable" 0 "DisableEnable_Disable" ;
VAL_ 895 TransmEngineCrankEnable2_ISig_4 3 "DisableEnable_NotAvailable" 2 "DisableEnable_Error" 1 "DisableEnable_Enable" 0 "DisableEnable_Disable" ;
VAL_ 588 VehicleMode_ISig_4 15 "VehicleMode_NotAvailable" 14 "VehicleMode_Error" 13 "VehicleMode_Spare_7" 12 "VehicleMode_Spare_6" 11 "VehicleMode_Spare_5" 10 "VehicleMode_Spare_4" 9 "VehicleMode_Spare_3" 8 "VehicleMode_Spare_2" 7 "VehicleMode_Spare_1" 6 "VehicleMode_Running" 5 "VehicleMode_Cranking" 4 "VehicleMode_PreRunning" 3 "VehicleMode_Accessory" 2 "VehicleMode_Living" 1 "VehicleMode_Parked" 0 "VehicleMode_Hibernate" ;
VAL_ 588 TransmissionDrivelineEngaged_ISi 3 "DisengageEngage_NotAvailable" 2 "DisengageEngage_Error" 1 "DisengageEngage_Engage" 0 "DisengageEngage_Disengage" ;
VAL_ 588 RevWarning_cmd 3 "RevWarning_cmd_NotAvailable" 2 "RevWarning_cmd_SpareValue" 1 "RevWarning_cmd_WarningSoundOn" 0 "RevWarning_cmd_WarningSoundOff" ;
VAL_ 588 SecuredNeutralPosition_ISig_4 3 "SecuredNeutralPosition_NotAvailable" 2 "SecuredNeutralPosition_Error" 1 "SecuredNeutralPosition_SecuredNeutralPosition" 0 "SecuredNeutralPosition_NotInSecuredNeutralPosition" ;
VAL_ 588 GearLeverPosition_ISig_4 15 "GearLeverPosition_NotAvailable" 14 "GearLeverPosition_Error" 13 "GearLeverPosition_SpareValue_06" 12 "GearLeverPosition_SpareValue_05" 11 "GearLeverPosition_SpareValue_04" 10 "GearLeverPosition_SpareValue_03" 9 "GearLeverPosition_SpareValue_02" 8 "GearLeverPosition_SpareValue_01" 7 "GearLeverPosition_SpareValue" 6 "GearLeverPosition_SEG6" 5 "GearLeverPosition_LowGear" 4 "GearLeverPosition_Manual" 3 "GearLeverPosition_Automatic" 2 "GearLeverPosition_Neutral" 1 "GearLeverPosition_Reverse" 0 "GearLeverPosition_GearFoldedAway" ;
VAL_ 588 EngineActiveStatus_ISig_4 15 "EngineActiveStatus_NotAvailable" 14 "EngineActiveStatus_Error" 13 "EngineActiveStatus_Spare_10" 12 "EngineActiveStatus_Spare_09" 11 "EngineActiveStatus_Spare_08" 10 "EngineActiveStatus_Spare_07" 9 "EngineActiveStatus_Spare_06" 8 "EngineActiveStatus_Spare_05" 7 "EngineActiveStatus_Spare_04" 6 "EngineActiveStatus_Spare_03" 5 "EngineActiveStatus_Spare_02" 4 "EngineActiveStatus_Spare_01" 3 "EngineActiveStatus_EngineStandby" 2 "EngineActiveStatus_ElectricPropulsionSystemRunning" 1 "EngineActiveStatus_InternalCombustionEngineRunning" 0 "EngineActiveStatus_DrivelineNotActive" ;
VAL_ 957 TrlrDirIndRightOutputStat_12V 7 "LightOutput_NotAvailable" 6 "LightOutput_Error" 5 "LightOutput_OutputActiveStatusUncertain" 4 "LightOutput_OutputActiveLightDetectedOnActivation" 3 "LightOutput_OutputActiveLightDetected" 2 "LightOutput_OutputActiveNoLightDetected" 1 "LightOutput_OutputActiveDetectionOngoing" 0 "LightOutput_OutputInactive" ;
VAL_ 957 TrailerBrakeLightOutputStat12V 7 "LightOutput_NotAvailable" 6 "LightOutput_Error" 5 "LightOutput_OutputActiveStatusUncertain" 4 "LightOutput_OutputActiveLightDetectedOnActivation" 3 "LightOutput_OutputActiveLightDetected" 2 "LightOutput_OutputActiveNoLightDetected" 1 "LightOutput_OutputActiveDetectionOngoing" 0 "LightOutput_OutputInactive" ;
VAL_ 957 TrailerDirIndLightRequested12V 3 "LightsRequested_NotAvailable" 2 "LightsRequested_Error" 1 "LightsRequested_LightsRequested" 0 "LightsRequested_LightNotRequested" ;
VAL_ 957 TD_BrakeLightsPulseRsp_12V 7 "LightDetected_NotAvailable" 6 "LightDetected_Error" 5 "LightDetected_Spare4" 4 "LightDetected_Spare3" 3 "LightDetected_Spare2" 2 "LightDetected_Spare1" 1 "LightDetected_LightDetected" 0 "LightDetected_NoLightDetected" ;
VAL_ 957 TD_DirInLgtPlsRsp_12V_Right 7 "LightDetected_NotAvailable" 6 "LightDetected_Error" 5 "LightDetected_Spare4" 4 "LightDetected_Spare3" 3 "LightDetected_Spare2" 2 "LightDetected_Spare1" 1 "LightDetected_LightDetected" 0 "LightDetected_NoLightDetected" ;
VAL_ 957 TrailerBrakeLightsRequested12V 3 "LightsRequested_NotAvailable" 2 "LightsRequested_Error" 1 "LightsRequested_LightsRequested" 0 "LightsRequested_LightNotRequested" ;
VAL_ 957 TrailerPos2OutputStat_12V 7 "LightOutput_NotAvailable" 6 "LightOutput_Error" 5 "LightOutput_OutputActiveStatusUncertain" 4 "LightOutput_OutputActiveLightDetectedOnActivation" 3 "LightOutput_OutputActiveLightDetected" 2 "LightOutput_OutputActiveNoLightDetected" 1 "LightOutput_OutputActiveDetectionOngoing" 0 "LightOutput_OutputInactive" ;
VAL_ 957 TD_PosLghtPlsRsp12V_Pos2 7 "LightDetected_NotAvailable" 6 "LightDetected_Error" 5 "LightDetected_Spare4" 4 "LightDetected_Spare3" 3 "LightDetected_Spare2" 2 "LightDetected_Spare1" 1 "LightDetected_LightDetected" 0 "LightDetected_NoLightDetected" ;
VAL_ 957 TrailerConnected_12VABSCurrent 3 "TrailerConnected_NotAvailalbe" 2 "TrailerConnected_Error" 1 "TrailerConnected_Trailer_Connected" 0 "TrailerConnected_Trailer_Disconnected" ;
VAL_ 957 TrailerPosLightRequested12V 3 "LightsRequested_NotAvailable" 2 "LightsRequested_Error" 1 "LightsRequested_LightsRequested" 0 "LightsRequested_LightNotRequested" ;
VAL_ 957 TD_PosLghtPlsRsp12V_Pos1 7 "LightDetected_NotAvailable" 6 "LightDetected_Error" 5 "LightDetected_Spare4" 4 "LightDetected_Spare3" 3 "LightDetected_Spare2" 2 "LightDetected_Spare1" 1 "LightDetected_LightDetected" 0 "LightDetected_NoLightDetected" ;
VAL_ 957 TrlrDirIndLeftOutputStat_12V 7 "LightOutput_NotAvailable" 6 "LightOutput_Error" 5 "LightOutput_OutputActiveStatusUncertain" 4 "LightOutput_OutputActiveLightDetectedOnActivation" 3 "LightOutput_OutputActiveLightDetected" 2 "LightOutput_OutputActiveNoLightDetected" 1 "LightOutput_OutputActiveDetectionOngoing" 0 "LightOutput_OutputInactive" ;
VAL_ 957 TrailerPos1OutputStat_12V 7 "LightOutput_NotAvailable" 6 "LightOutput_Error" 5 "LightOutput_OutputActiveStatusUncertain" 4 "LightOutput_OutputActiveLightDetectedOnActivation" 3 "LightOutput_OutputActiveLightDetected" 2 "LightOutput_OutputActiveNoLightDetected" 1 "LightOutput_OutputActiveDetectionOngoing" 0 "LightOutput_OutputInactive" ;
VAL_ 957 TD_DirInLgtPlsRsp_12V_Left 7 "LightDetected_NotAvailable" 6 "LightDetected_Error" 5 "LightDetected_Spare4" 4 "LightDetected_Spare3" 3 "LightDetected_Spare2" 2 "LightDetected_Spare1" 1 "LightDetected_LightDetected" 0 "LightDetected_NoLightDetected" ;
VAL_ 958 TD_LghtPlsReqBrk12V_Status 3 "TD_LightsPulseStatus_NotAvailable" 2 "TD_LightsPulseStatus_Error" 1 "TD_LightsPulseStatus_Spare" 0 "TD_LightsPulseStatus_OK" ;
VAL_ 958 TD_LghtPlsReqDir12V_Right 1 "DetectionLight_SendPulse" 0 "DetectionLight_Inactive" ;
VAL_ 958 TD_LghtPlsReqDir12V_Status 3 "TD_LightsPulseStatus_NotAvailable" 2 "TD_LightsPulseStatus_Error" 1 "TD_LightsPulseStatus_Spare" 0 "TD_LightsPulseStatus_OK" ;
VAL_ 958 TD_LightsResetReq_12V 3 "InactiveResetRequest_NotApplicable" 2 "InactiveResetRequest_Error" 1 "InactiveResetRequest_ResetRequest" 0 "InactiveResetRequest_Inactive" ;
VAL_ 958 TD_LghtPlsReqPos12V_Status 3 "TD_LightsPulseStatus_NotAvailable" 2 "TD_LightsPulseStatus_Error" 1 "TD_LightsPulseStatus_Spare" 0 "TD_LightsPulseStatus_OK" ;
VAL_ 958 TD_LghtPlsReqBrk12V_Brake 1 "DetectionLight_SendPulse" 0 "DetectionLight_Inactive" ;
VAL_ 958 TrailerConnectedType 3 "TrailerConnectedType_NotAvailable" 2 "TrailerConnectedType_Error" 1 "TrailerConnectedType_12V_Trailer" 0 "TrailerConnectedType_24V_Trailer" ;
VAL_ 958 ECSManStandbyStatus_ISig_4 3 "InactiveActive_NotAvailable" 2 "InactiveActive_Error" 1 "InactiveActive_Active" 0 "InactiveActive_Inactive" ;
VAL_ 958 TrailerLightsConnected_12V 3 "NoYes_NotAvailable" 2 "NoYes_Error" 1 "NoYes_Yes" 0 "NoYes_No" ;
VAL_ 958 TD_LghtPlsReqDir12V_Left 1 "DetectionLight_SendPulse" 0 "DetectionLight_Inactive" ;
VAL_ 958 TD_LghtPlsReqPos12V_Pos2 1 "DetectionLight_SendPulse" 0 "DetectionLight_Inactive" ;
VAL_ 958 TD_LghtPlsReqPos12V_Pos1 1 "DetectionLight_SendPulse" 0 "DetectionLight_Inactive" ;
VAL_ 958 ECSPreconForSWDL_NegStatInfo 7 "NegStatInfo_NotAvailable" 6 "NegStatInfo_Error" 5 "NegStatInfo_Spare2" 4 "NegStatInfo_Spare1" 3 "NegStatInfo_BB_SuspensionInhibitActive" 2 "NegStatInfo_KneelingActive" 1 "NegStatInfo_FerryFunctionActive" 0 "NegStatInfo_BB_AirDumpActive" ;
VAL_ 958 ECSPreconForSWDL_Status 3 "FalseTrue_NotAvaiable" 2 "FalseTrue_Error" 1 "FalseTrue_True" 0 "FalseTrue_False" ;
VAL_ 676 RearAxle3DiffLock_stat_ISig_4 3 "OffOn_NotAvailable" 2 "OffOn_Error" 1 "OffOn_On" 0 "OffOn_Off" ;
VAL_ 676 LeftBrakeAndDirInd_cmd 3 "InactiveActive_NotAvailable" 2 "InactiveActive_Error" 1 "InactiveActive_Active" 0 "InactiveActive_Inactive" ;
VAL_ 676 RightBrakeAndDirInd_cmd 3 "InactiveActive_NotAvailable" 2 "InactiveActive_Error" 1 "InactiveActive_Active" 0 "InactiveActive_Inactive" ;
VAL_ 951 DumpSwitchChangeAck_ISig_4 3 "DumpSwitchChangeAck_NotAvailable" 2 "DumpSwitchChangeAck_Error" 1 "DumpSwitchChangeAck_ChangeAcknowledged" 0 "DumpSwitchChangeAck_NoAction" ;
VAL_ 951 FrontDumpFunctionCmd 7 "DumpFunctionCmd_NotAvailable" 6 "DumpFunctionCmd_Error" 5 "DumpFunctionCmd_Spare3" 4 "DumpFunctionCmd_Spare2" 3 "DumpFunctionCmd_Idle" 2 "DumpFunctionCmd_PressureUpdating" 1 "DumpFunctionCmd_Active" 0 "DumpFunctionCmd_Inactive" ;
VAL_ 1344 RegenInhibitVehicleHeight_ISig_4 3 "ActiveStatus_NotAvailable" 2 "ActiveStatus_Error" 1 "ActiveStatus_Active" 0 "ActiveStatus_NotActive" ;
VAL_ 1344 SavedHeightControlMode_ISig_4 3 "SavedHeightControlMode_NotAvailable" 2 "SavedHeightControlMode_Error" 1 "SavedHeightControlMode_Drive" 0 "SavedHeightControlMode_Manual" ;
VAL_ 1343 TrailerDirIndLeftOutputStat_ISig 7 "TrailerLightOutputStat_NotAvailable" 6 "TrailerLightOutputStat_Error" 5 "TrailerLightOutputStat_OutputActiveStatusUncertain" 4 "TrailerLightOutputStat_OutputActiveLightDetectedOnActivation" 3 "TrailerLightOutputStat_OutputActiveLightDetected" 2 "TrailerLightOutputStat_OutputActiveNoLightDetected" 1 "TrailerLightOutputStat_OutputActiveDetectionOngoing" 0 "TrailerLightOutputStat_OutputInactive" ;
VAL_ 1343 TrailerBrakeLightOutputStat_ISig 7 "TrailerLightOutputStat_NotAvailable" 6 "TrailerLightOutputStat_Error" 5 "TrailerLightOutputStat_OutputActiveStatusUncertain" 4 "TrailerLightOutputStat_OutputActiveLightDetectedOnActivation" 3 "TrailerLightOutputStat_OutputActiveLightDetected" 2 "TrailerLightOutputStat_OutputActiveNoLightDetected" 1 "TrailerLightOutputStat_OutputActiveDetectionOngoing" 0 "TrailerLightOutputStat_OutputInactive" ;
VAL_ 1343 TrailerPosLightRightOutputStat_I 7 "TrailerLightOutputStat_NotAvailable" 6 "TrailerLightOutputStat_Error" 5 "TrailerLightOutputStat_OutputActiveStatusUncertain" 4 "TrailerLightOutputStat_OutputActiveLightDetectedOnActivation" 3 "TrailerLightOutputStat_OutputActiveLightDetected" 2 "TrailerLightOutputStat_OutputActiveNoLightDetected" 1 "TrailerLightOutputStat_OutputActiveDetectionOngoing" 0 "TrailerLightOutputStat_OutputInactive" ;
VAL_ 1343 TrailerPosLightLeftOutputStat_IS 7 "TrailerLightOutputStat_NotAvailable" 6 "TrailerLightOutputStat_Error" 5 "TrailerLightOutputStat_OutputActiveStatusUncertain" 4 "TrailerLightOutputStat_OutputActiveLightDetectedOnActivation" 3 "TrailerLightOutputStat_OutputActiveLightDetected" 2 "TrailerLightOutputStat_OutputActiveNoLightDetected" 1 "TrailerLightOutputStat_OutputActiveDetectionOngoing" 0 "TrailerLightOutputStat_OutputInactive" ;
VAL_ 1343 LoadDistributionSelected2_ISig_4 15 "LoadDistributionSelected2_NotAvailable" 14 "LoadDistributionSelected2_Error" 13 "LoadDistributionSelected2_Reserved_01" 12 "LoadDistributionSelected2_TractionHelp2InterDiff" 11 "LoadDistributionSelected2_StartingHelp2InterDiff" 10 "LoadDistributionSelected2_TractionHelp2" 9 "LoadDistributionSelected2_StartingHelp2" 8 "LoadDistributionSelected2_VariableAxleLoad" 7 "LoadDistributionSelected2_NoLoadDistribution" 6 "LoadDistributionSelected2_TractionHelpInterDiff" 5 "LoadDistributionSelected2_StartingHelpInterDiff" 4 "LoadDistributionSelected2_AlternativeLoad" 3 "LoadDistributionSelected2_TractionHelp" 2 "LoadDistributionSelected2_StartingHelp" 1 "LoadDistributionSelected2_OptimisedTraction" 0 "LoadDistributionSelected2_NormalLoad" ;
VAL_ 1343 TrailerDirIndRightOutputStat_ISi 7 "TrailerLightOutputStat_NotAvailable" 6 "TrailerLightOutputStat_Error" 5 "TrailerLightOutputStat_OutputActiveStatusUncertain" 4 "TrailerLightOutputStat_OutputActiveLightDetectedOnActivation" 3 "TrailerLightOutputStat_OutputActiveLightDetected" 2 "TrailerLightOutputStat_OutputActiveNoLightDetected" 1 "TrailerLightOutputStat_OutputActiveDetectionOngoing" 0 "TrailerLightOutputStat_OutputInactive" ;
VAL_ 1343 ExtECSPressureUpdateAck 7 "ExtECSPressureUpdateAck_NotAvailable" 6 "ExtECSPressureUpdateAck_Error" 5 "ExtECSPressureUpdateAck_Spare4" 4 "ExtECSPressureUpdateAck_Spare3" 3 "ExtECSPressureUpdateAck_Spare2" 2 "ExtECSPressureUpdateAck_Spare1" 1 "ExtECSPressureUpdateAck_InProgress" 0 "ExtECSPressureUpdateAck_NoRequest" ;
VAL_ 825 RevLightLamp_stat_ISig_4 7 "LampCheckLeftRight_stat_NotAvailable" 6 "LampCheckLeftRight_stat_Error" 5 "LampCheckLeftRight_stat_Spare" 4 "LampCheckLeftRight_stat_TestedLeftAndRightLampNOK" 3 "LampCheckLeftRight_stat_TestedRightLampNOK" 2 "LampCheckLeftRight_stat_TestedLeftLampNOK" 1 "LampCheckLeftRight_stat_TestedLampOK" 0 "LampCheckLeftRight_stat_NotTested" ;
VAL_ 825 FirstAxleLowerPrioSelected_ISig_ 7 "FirstAxleLowerPrio_NotAvailable" 6 "FirstAxleLowerPrio_Error" 5 "FirstAxleLowerPrio_Reserved_03" 4 "FirstAxleLowerPrio_Reserved_02" 3 "FirstAxleLowerPrio_Reserved_01" 2 "FirstAxleLowerPrio_Reserved" 1 "FirstAxleLowerPrio_LowerPusher" 0 "FirstAxleLowerPrio_LowerTag" ;
VAL_ 825 FrontParkBrakeOverrideInd_ISig_4 3 "FrontParkBrakeOverrideInd_NotAvailable" 2 "FrontParkBrakeOverrideInd_Error" 1 "FrontParkBrakeOverrideInd_FailedToOverride" 0 "FrontParkBrakeOverrideInd_OK" ;
VAL_ 825 ECSLimpHomeNotification_ISig_4 7 "ECSLimpHomeNotification_NotAvailable" 6 "ECSLimpHomeNotification_Error" 5 "ECSLimpHomeNotification_LimpHomeMode5" 4 "ECSLimpHomeNotification_LimpHomeMode4" 3 "ECSLimpHomeNotification_LimpHomeMode3" 2 "ECSLimpHomeNotification_LimpHomeMode2" 1 "ECSLimpHomeNotification_LimpHomeMode1" 0 "ECSLimpHomeNotification_NoLimpHomeMode" ;
VAL_ 825 ECSValveActivationAllowed 3 "FalseTrue_NotAvaiable" 2 "FalseTrue_Error" 1 "FalseTrue_True" 0 "FalseTrue_False" ;
VAL_ 825 UnevenLoadWarning_ISig_4 3 "Warning_NotAvailable" 2 "Warning_Error" 1 "Warning_Warning" 0 "Warning_NoWarning" ;
VAL_ 825 RampLevelRequestACK_ISig_4 3 "ChangeRequest2Bit_NotAvailable" 2 "ChangeRequest2Bit_Error" 1 "ChangeRequest2Bit_Change" 0 "ChangeRequest2Bit_TakeNoAction" ;
VAL_ 825 LoadDistributionSelected_ISig_4 15 "LoadDistributionSelected_NotAvailable" 14 "LoadDistributionSelected_Error" 13 "LoadDistributionSelected_Reserved_05" 12 "LoadDistributionSelected_Reserved_04" 11 "LoadDistributionSelected_Reserved_03" 10 "LoadDistributionSelected_TractionHelp2" 9 "LoadDistributionSelected_StartingHelp2" 8 "LoadDistributionSelected_VariableAxleLoad" 7 "LoadDistributionSelected_NoLoadDistribution" 6 "LoadDistributionSelected_TractionHelpInterDiff" 5 "LoadDistributionSelected_StartingHelpInterDiff" 4 "LoadDistributionSelected_AlternativeLoad" 3 "LoadDistributionSelected_TractionHelp" 2 "LoadDistributionSelected_StartingHelp" 1 "LoadDistributionSelected_OptimisedTraction" 0 "LoadDistributionSelected_NormalLoad" ;
VAL_ 825 TrailerABSStatus_ISig_4 3 "TrailerABSStatus_NotAvailable" 2 "TrailerABSStatus_ErrorIndicator" 1 "TrailerABSStatus_OK" 0 "TrailerABSStatus_Error" ;
VAL_ 825 LoadDistributionALDChangeACK_ISi 7 "LoadDistributionALDChangeACK_NotAvailable" 6 "LoadDistributionALDChangeACK_Error" 5 "LoadDistributionALDChangeACK_SystemDeniedVersatile" 4 "LoadDistributionALDChangeACK_Spare_01" 3 "LoadDistributionALDChangeACK_Spare" 2 "LoadDistributionALDChangeACK_LoadShiftDeniedOverspeed" 1 "LoadDistributionALDChangeACK_ChangeAcknowledged" 0 "LoadDistributionALDChangeACK_NoAction" ;
VAL_ 825 FogLightRearLamp_stat_ISig_4 7 "LampCheck_stat_NotAvailable" 6 "LampCheck_stat_Error" 5 "LampCheck_stat_Spare_02" 4 "LampCheck_stat_Spare_01" 3 "LampCheck_stat_Spare" 2 "LampCheck_stat_TestedLampNOK" 1 "LampCheck_stat_TestedLampOK" 0 "LampCheck_stat_NotTested" ;
VAL_ 825 PositionLightRearLamp_stat_ISig_ 7 "LampCheckLeftRight_stat_NotAvailable" 6 "LampCheckLeftRight_stat_Error" 5 "LampCheckLeftRight_stat_Spare" 4 "LampCheckLeftRight_stat_TestedLeftAndRightLampNOK" 3 "LampCheckLeftRight_stat_TestedRightLampNOK" 2 "LampCheckLeftRight_stat_TestedLeftLampNOK" 1 "LampCheckLeftRight_stat_TestedLampOK" 0 "LampCheckLeftRight_stat_NotTested" ;
VAL_ 825 FerryFunctionSwitchChangeACK_ISi 3 "Ack2Bit_NotAvailable" 2 "Ack2Bit_Error" 1 "Ack2Bit_ChangeAcknowledged" 0 "Ack2Bit_NoAction" ;
VAL_ 825 LiftAxle1AutoLiftSelected_ISig_4 3 "FalseTrue_NotAvaiable" 2 "FalseTrue_Error" 1 "FalseTrue_True" 0 "FalseTrue_False" ;
VAL_ 825 BrakeLightLamp_stat_ISig_4 7 "LampCheckLeftRight_stat_NotAvailable" 6 "LampCheckLeftRight_stat_Error" 5 "LampCheckLeftRight_stat_Spare" 4 "LampCheckLeftRight_stat_TestedLeftAndRightLampNOK" 3 "LampCheckLeftRight_stat_TestedRightLampNOK" 2 "LampCheckLeftRight_stat_TestedLeftLampNOK" 1 "LampCheckLeftRight_stat_TestedLampOK" 0 "LampCheckLeftRight_stat_NotTested" ;
VAL_ 825 LiftAxle2AutoLiftSelected_ISig_4 3 "FalseTrue_NotAvaiable" 2 "FalseTrue_Error" 1 "FalseTrue_True" 0 "FalseTrue_False" ;
VAL_ 825 StartupProhibitStatus_ISig_4 3 "InactiveActive_NotAvailable" 2 "InactiveActive_Error" 1 "InactiveActive_Active" 0 "InactiveActive_Inactive" ;
VAL_ 825 LiftAxle1LowerACK_ISig_4 7 "LiftAxle1LowerACK_NotAvailable" 6 "LiftAxle1LowerACK_Error" 5 "LiftAxle1LowerACK_SystemDeniedVersatile" 4 "LiftAxle1LowerACK_Spare_01" 3 "LiftAxle1LowerACK_Spare" 2 "LiftAxle1LowerACK_LowerDeniedRAS_EC" 1 "LiftAxle1LowerACK_ChangeAcknowledged" 0 "LiftAxle1LowerACK_NoAction" ;
VAL_ 825 TrailerDirInd_status 7 "DirIndFaultStatus_NotAvailable" 6 "DirIndFaultStatus_Error" 5 "DirIndFaultStatus_SpareValue_01" 4 "DirIndFaultStatus_SpareValue" 3 "DirIndFaultStatus_BothLeftAndRightDirectionIndicatorsFault" 2 "DirIndFaultStatus_RightDirectionIndicatorLampFault" 1 "DirIndFaultStatus_LeftDirectionIndicatorLampFault" 0 "DirIndFaultStatus_NoError" ;
VAL_ 825 DriveLevelPosUserInteraction_ISi 7 "DriveLevelPosUserInteraction_NotAvailable" 6 "DriveLevelPosUserInteraction_Error" 5 "DriveLevelPosUserInteraction_Spare3" 4 "DriveLevelPosUserInteraction_Spare2" 3 "DriveLevelPosUserInteraction_Spare1" 2 "DriveLevelPosUserInteraction_WarningDriveLevelPosNotSelected" 1 "DriveLevelPosUserInteraction_DriveLevelPositionNotSelected" 0 "DriveLevelPosUserInteraction_DriveLevelPositionSelected" ;
VAL_ 948 FrontEndPositionStatus 7 "EndPositionStatus_NotAvailable" 6 "EndPositionStatus_Error" 5 "EndPositionStatus_Reserved_01" 4 "EndPositionStatus_Reserved" 3 "EndPositionStatus_LiftingAndLoweringNotAllowed" 2 "EndPositionStatus_MinEndLevelReached" 1 "EndPositionStatus_MaxEndLevelReached" 0 "EndPositionStatus_NoEndLevelReached" ;
VAL_ 948 DirIndRearLamp_Stat_ISig_4 7 "LampCheckLeftRight_stat_NotAvailable" 6 "LampCheckLeftRight_stat_Error" 5 "LampCheckLeftRight_stat_Spare" 4 "LampCheckLeftRight_stat_TestedLeftAndRightLampNOK" 3 "LampCheckLeftRight_stat_TestedRightLampNOK" 2 "LampCheckLeftRight_stat_TestedLeftLampNOK" 1 "LampCheckLeftRight_stat_TestedLampOK" 0 "LampCheckLeftRight_stat_NotTested" ;
VAL_ 948 FrontAxleInBumperRange_ISig_4 3 "AxleInBumperRange_NotAvailable" 2 "AxleInBumperRange_ErrorIndicator" 1 "AxleInBumperRange_ActualLevelWithinBumperRange" 0 "AxleInBumperRange_ActualLevelOutOfBumperRange" ;
VAL_ 948 LoadDistributionRequestedACK_ISi 7 "LoadDistributionRequestedACK_NotAvailable" 6 "LoadDistributionRequestedACK_Error" 5 "LoadDistributionRequestedACK_SystemDeniedVersatile" 4 "LoadDistributionRequestedACK_Reserved2" 3 "LoadDistributionRequestedACK_DeniedDueToDisengagedDifflock" 2 "LoadDistributionRequestedACK_LoadShiftDeniedFALIMOverload" 1 "LoadDistributionRequestedACK_ChangeAcknowledged" 0 "LoadDistributionRequestedACK_NoAction" ;
VAL_ 948 Rear1ClutchStatus 3 "DisengageEngage_NotAvailable" 2 "DisengageEngage_Error" 1 "DisengageEngage_Engage" 0 "DisengageEngage_Disengage" ;
VAL_ 947 FPBRMMIStat_FPBRChangeAck_ISig_4 3 "Ack2Bit_NotAvailable" 2 "Ack2Bit_Error" 1 "Ack2Bit_ChangeAcknowledged" 0 "Ack2Bit_NoAction" ;
VAL_ 947 FPBRMMIStat_FPBRStatusInd_ISig_4 3 "FPBRStatusInd_NotAvailable" 2 "FPBRStatusInd_Changing" 1 "FPBRStatusInd_On" 0 "FPBRStatusInd_Off" ;
VAL_ 947 LiftAxle1LiftAllowed_Stat 7 "LiftAxleLiftAllowed_NotAvailable" 6 "LiftAxleLiftAllowed_Error" 5 "LiftAxleLiftAllowed_Spare2" 4 "LiftAxleLiftAllowed_Spare1" 3 "LiftAxleLiftAllowed_Stat_SystemDeniedVersatile" 2 "LiftAxleLiftAllowed_Stat_LiftDeniedRearOverload" 1 "LiftAxleLiftAllowed_Stat_LiftDeniedFrontOverload" 0 "LiftAxleLiftAllowed_Stat_LiftAllowed" ;
VAL_ 530 AirDumpStatus_ISig_4 7 "AirDumpStatus_NotAvailable" 6 "AirDumpStatus_Error" 5 "AirDumpStatus_Spare2" 4 "AirDumpStatus_Spare1" 3 "AirDumpStatus_Denied" 2 "AirDumpStatus_ActiveReached" 1 "AirDumpStatus_ActiveNotReached" 0 "AirDumpStatus_Inactive" ;
VAL_ 530 RearAxle2DiffLock_stat_ISig_4 3 "OffOn_NotAvailable" 2 "OffOn_Error" 1 "OffOn_On" 0 "OffOn_Off" ;
VAL_ 530 SWBrakeSwitch_ISig_4 3 "BrakeSwitch_NotAvailable" 2 "BrakeSwitch_Error" 1 "BrakeSwitch_BrakePedalDepressed" 0 "BrakeSwitch_BrakePedalReleased" ;
VAL_ 530 RearAxle1DiffLock_stat_ISig_4 3 "OffOn_NotAvailable" 2 "OffOn_Error" 1 "OffOn_On" 0 "OffOn_Off" ;
VAL_ 530 BackToDriveReqACK_ISig_4 3 "BackToDriveReqACK_NotAvailable" 2 "BackToDriveReqACK_Error" 1 "BackToDriveReqACK_ChangeAcknowledged" 0 "BackToDriveReqACK_TakNoAction" ;
VAL_ 530 TrailerWithoutABS_ISig_4 3 "TrailerWithoutABS_NotAvailableOrNotInstalled" 2 "TrailerWithoutABS_ErrorIndicator" 1 "TrailerWithoutABS_YesTrailerWithoutABS" 0 "TrailerWithoutABS_NoNoTrailerPresentOraTrailerWithABS" ;
VAL_ 530 TrailerConnected_ISig_4 3 "NoYes_NotAvailable" 2 "NoYes_Error" 1 "NoYes_Yes" 0 "NoYes_No" ;
VAL_ 530 CentralRearDiffLock_stat_ISig_4 3 "DisengageEngage_NotAvailable" 2 "DisengageEngage_Error" 1 "DisengageEngage_Engage" 0 "DisengageEngage_Disengage" ;
VAL_ 528 RollEndPositionStatus_ISig_4 7 "RollEndPositionStatus_NotAvailable" 6 "RollEndPositionStatus_Error" 5 "RollEndPositionStatus_Reserved_01" 4 "RollEndPositionStatus_Reserved" 3 "RollEndPositionStatus_NoRollingAllowed" 2 "RollEndPositionStatus_CounterClockwiseEndLevelReached" 1 "RollEndPositionStatus_ClockwiseEndLevelReached" 0 "RollEndPositionStatus_NoEndLevelReached" ;
VAL_ 528 FrontFerryFunctionCmd_ISig_4 7 "FerryFunctionCmd_NotAvailable" 6 "FerryFunctionCmd_Error" 5 "FerryFunctionCmd_Spare2" 4 "FerryFunctionCmd_Spare1" 3 "FerryFunctionCmd_Spare0" 2 "FerryFunctionCmd_Drain" 1 "FerryFunctionCmd_CloseValves" 0 "FerryFunctionCmd_Inactive" ;
VAL_ 528 RideHeightFunctionStatus_ISig_4 15 "RideHeightFunction_NotAvailable" 14 "RideHeightFunction_ErrorIndicator" 13 "RideHeightFunction_NotDefined_05" 12 "RideHeightFunction_NotDefined_04" 11 "RideHeightFunction_NotDefined_03" 10 "RideHeightFunction_NotDefined_02" 9 "RideHeightFunction_NotDefined_01" 8 "RideHeightFunction_NotDefined" 7 "RideHeightFunction_AlternativeDrivePosition2" 6 "RideHeightFunction_AlternativeDrivePosition1" 5 "RideHeightFunction_LowDrivePosition" 4 "RideHeightFunction_HighDrivePosition" 3 "RideHeightFunction_SpeedDependentDrivePosition" 2 "RideHeightFunction_AlternativeDrivePosition" 1 "RideHeightFunction_StandardDrivePosition" 0 "RideHeightFunction_Inactive" ;
VAL_ 528 HeightControlMode_ISig_4 15 "HeightControlMode_NotAvailable" 14 "HeightControlMode_ErrorIndicator" 13 "HeightControlMode_DumpFunction" 12 "HeightControlMode_FactorySupportMode" 11 "HeightControlMode_Calibration" 10 "HeightControlMode_Prohibit" 9 "HeightControlMode_FunctionTest" 8 "HeightControlMode_Stop" 7 "HeightControlMode_LimpHome" 6 "HeightControlMode_FerryFunction" 5 "HeightControlMode_KneelingHeight" 4 "HeightControlMode_DriveHeight" 3 "HeightControlMode_DockingRampHeight" 2 "HeightControlMode_HeightAdjustment" 1 "HeightControlMode_StartUpHeight" 0 "HeightControlMode_TakeNoAction" ;
VAL_ 528 ECSShutdownCmd_ISig_4 3 "FalseTrue_NotAvaiable" 2 "FalseTrue_Error" 1 "FalseTrue_True" 0 "FalseTrue_False" ;
VAL_ 528 FerryFunctionStatus_ISig_4 7 "FerryFunctionStatus_NotAvailable" 6 "FerryFunctionStatus_Error" 5 "FerryFunctionStatus_Spare_03" 4 "FerryFunctionStatus_Spare_02" 3 "FerryFunctionStatus_Spare_01" 2 "FerryFunctionStatus_FerryFunctionActiveLeveNotlReached" 1 "FerryFunctionStatus_FerryFunctionActiveLevelReached" 0 "FerryFunctionStatus_FerryFunctionNotActive" ;
VAL_ 528 LevelControlInformation_ISig_4 15 "LevelControlInformation_NotAvailable" 14 "LevelControlInformation_Error" 13 "LevelControlInformation_Reserved_06" 12 "LevelControlInformation_Reserved_05" 11 "LevelControlInformation_Reserved_04" 10 "LevelControlInformation_Reserved_03" 9 "LevelControlInformation_Reserved_02" 8 "LevelControlInformation_Reserved_01" 7 "LevelControlInformation_Reserved" 6 "LevelControlInformation_LimpHome" 5 "LevelControlInformation_FerryFunction" 4 "LevelControlInformation_KneelingHeight" 3 "LevelControlInformation_DriveHeight" 2 "LevelControlInformation_DockingHeight" 1 "LevelControlInformation_HeightAdjustment" 0 "LevelControlInformation_Prohibit" ;
VAL_ 528 ChangeKneelACK_ISig_4 3 "ChangeKneelACK_NotAvailable" 2 "ChangeKneelACK_Error" 1 "ChangeKneelACK_ChangeAcknowledged" 0 "ChangeKneelACK_NoAction" ;
VAL_ 528 RearEndPositionStatus_ISig_4 7 "EndPositionStatus_NotAvailable" 6 "EndPositionStatus_Error" 5 "EndPositionStatus_Reserved_01" 4 "EndPositionStatus_Reserved" 3 "EndPositionStatus_LiftingAndLoweringNotAllowed" 2 "EndPositionStatus_MinEndLevelReached" 1 "EndPositionStatus_MaxEndLevelReached" 0 "EndPositionStatus_NoEndLevelReached" ;
VAL_ 528 RampHeightOutsideTargetRange_ISi 7 "HeightOutsideTargetRange_NotAvailable" 6 "HeightOutsideTargetRange_Error" 5 "HeightOutsideTargetRange_NotDefined_02" 4 "HeightOutsideTargetRange_NotDefined_01" 3 "HeightOutsideTargetRange_NotDefined" 2 "HeightOutsideTargetRange_ToHigh" 1 "HeightOutsideTargetRange_ToLow" 0 "HeightOutsideTargetRange_Inactive" ;
VAL_ 528 LoadDistributionFuncSelected_ISi 15 "LoadDistributionFuncSelected_NotAvaiable" 14 "LoadDistributionFuncSelected_ErrorIndicator" 13 "LoadDistributionFuncSelected_SpareValue_08" 12 "LoadDistributionFuncSelected_SpareValue_07" 11 "LoadDistributionFuncSelected_SpareValue_06" 10 "LoadDistributionFuncSelected_SpareValue_05" 9 "LoadDistributionFuncSelected_SpareValue_04" 8 "LoadDistributionFuncSelected_SpareValue_03" 7 "LoadDistributionFuncSelected_SpareValue_02" 6 "LoadDistributionFuncSelected_MaximumTractionStartingHelp" 5 "LoadDistributionFuncSelected_VariableAxleLoad" 4 "LoadDistributionFuncSelected_NoLoadDistribution" 3 "LoadDistributionFuncSelected_AlternativeLoad" 2 "LoadDistributionFuncSelected_MaximumTractionTractionHelp" 1 "LoadDistributionFuncSelected_OptimisedTraction" 0 "LoadDistributionFuncSelected_NormalLoad" ;
VAL_ 528 HeightAdjustmentAllowed_ISig_4 3 "FalseTrue_NotAvaiable" 2 "FalseTrue_Error" 1 "FalseTrue_True" 0 "FalseTrue_False" ;
VAL_ 528 KneelingInformation_ISig_4 15 "KneelingInformation_NotAvailable" 14 "KneelingInformation_ErrorIndicator" 13 "KneelingInformation_NotDefined_08" 12 "KneelingInformation_NotDefined_07" 11 "KneelingInformation_NotDefined_06" 10 "KneelingInformation_NotDefined_05" 9 "KneelingInformation_NotDefined_04" 8 "KneelingInformation_NotDefined_03" 7 "KneelingInformation_NotDefined_02" 6 "KneelingInformation_NotDefined_01" 5 "KneelingInformation_NotDefined" 4 "KneelingInformation_KneelingAborted" 3 "KneelingInformation_LiftingActiveVehicleIsLiftedDueToRcvrReq" 2 "KneelingInformation_KneelLevelReachedVehicleIsAtFixeKneelLvl" 1 "KneelingInformation_LoweringActiveTheVehIsLoweredDueToKneelReq" 0 "KneelingInformation_NotActiveTheKneelingFunctionIsNotActive" ;
VAL_ 528 KneelingStatusHMI_ISig_4 3 "KneelingStatusHMI_NotAvailable" 2 "KneelingStatusHMI_Error" 1 "KneelingStatusHMI_Active" 0 "KneelingStatusHMI_Inactive" ;
VAL_ 528 LiftAxle1PositionStatus_ISig_4 7 "LiftAxlePositionStatus_NotAvailable" 6 "LiftAxlePositionStatus_Error" 5 "LiftAxlePositionStatus_Reserved_01" 4 "LiftAxlePositionStatus_Reserved" 3 "LiftAxlePositionStatus_Lifting" 2 "LiftAxlePositionStatus_Lowering" 1 "LiftAxlePositionStatus_Lifted" 0 "LiftAxlePositionStatus_Lowered" ;
VAL_ 528 VehicleDynamicSuspProhibitStat_I 3 "InactiveActive_NotAvailable" 2 "InactiveActive_Error" 1 "InactiveActive_Active" 0 "InactiveActive_Inactive" ;
VAL_ 528 LiftAxle2PositionStatus_ISig_4 7 "LiftAxlePositionStatus_NotAvailable" 6 "LiftAxlePositionStatus_Error" 5 "LiftAxlePositionStatus_Reserved_01" 4 "LiftAxlePositionStatus_Reserved" 3 "LiftAxlePositionStatus_Lifting" 2 "LiftAxlePositionStatus_Lowering" 1 "LiftAxlePositionStatus_Lifted" 0 "LiftAxlePositionStatus_Lowered" ;
VAL_ 528 RideHeightStatus_ISig_4 15 "RideHeightStatus_NotAvailable" 14 "RideHeightStatus_ErrorIndicator" 13 "RideHeightStatus_NotDefined_03" 12 "RideHeightStatus_NotDefined_02" 11 "RideHeightStatus_NotDefined_01" 10 "RideHeightStatus_NotDefined" 9 "RideHeightStatus_AlternativeDrivePosition2" 8 "RideHeightStatus_AlternativeDrivePosition1" 7 "RideHeightStatus_AlternativeDrivePosition" 6 "RideHeightStatus_HighDrivePosition" 5 "RideHeightStatus_LowDrivePosition" 4 "RideHeightStatus_SpeedDependentDrivePositionHighSpeed" 3 "RideHeightStatus_SpeedDependentDrivePositionLowSpeed" 2 "RideHeightStatus_StandardUserDrivePosition" 1 "RideHeightStatus_StandardFactoryDrivePosition" 0 "RideHeightStatus_Inactive" ;
VAL_ 528 DirInd_Rear_Status_ISig_4 7 "DirIndFaultStatus_NotAvailable" 6 "DirIndFaultStatus_Error" 5 "DirIndFaultStatus_SpareValue_01" 4 "DirIndFaultStatus_SpareValue" 3 "DirIndFaultStatus_BothLeftAndRightDirectionIndicatorsFault" 2 "DirIndFaultStatus_RightDirectionIndicatorLampFault" 1 "DirIndFaultStatus_LeftDirectionIndicatorLampFault" 0 "DirIndFaultStatus_NoError" ;
SIG_GROUP_ 957 TD_PosLghtPlsRsp12V_sg 1 : TD_PosLghtPlsRsp12V_Pos2 TD_PosLghtPlsRsp12V_Pos1;
SIG_GROUP_ 957 TD_DirInLgtPlsRsp_12V_sg 1 : TD_DirInLgtPlsRsp_12V_Right TD_DirInLgtPlsRsp_12V_Left;
SIG_GROUP_ 958 ECSPreconForSWDL_sg 1 : ECSPreconForSWDL_NegStatInfo ECSPreconForSWDL_Status;
SIG_GROUP_ 958 TD_LghtPlsReqPos12V_sg 1 : TD_LghtPlsReqPos12V_Status TD_LghtPlsReqPos12V_Pos2 TD_LghtPlsReqPos12V_Pos1;
SIG_GROUP_ 958 TD_LghtPlsReqBrk12V_sg 1 : TD_LghtPlsReqBrk12V_Status TD_LghtPlsReqBrk12V_Brake;
SIG_GROUP_ 958 TD_LghtPlsReqDir12V_sg 1 : TD_LghtPlsReqDir12V_Right TD_LghtPlsReqDir12V_Status TD_LghtPlsReqDir12V_Left;
SIG_GROUP_ 947 FrontLevRefCtrl_sg 1 : FrontLevRefCtrl_ShortPushCnt FrontLevRefCtrl_LevelRef;
SIG_GROUP_ 947 FPBRMMIStat_sg_ISig_4 1 : FPBRMMIStat_FPBRChangeAck_ISig_4 FPBRMMIStat_FPBRStatusInd_ISig_4;
